VERSION ""

NS_ :

BS_:

BU_: VDCU_M CDCU VDR_TBOX ADCU VIU_B VIU_C VDCU_V EPB EBS FCS EPS_M EPS_S CMS_R CMS_B ECAS EGSM MTCU

BO_ 2566834778 DM1_MTCU: 56 MTCU
 SG_ ProtectLampStatus_MTCU : 0|2@1+ (1,0) [0|3] "" VDCU_M
 SG_ AmberWarningLampStatus_MTCU : 2|2@1+ (1,0) [0|3] "" VDCU_M
 SG_ RedStopLampState_MTCU : 4|2@1+ (1,0) [0|3] "" VDCU_M
 SG_ MalfunctionIndicatorLampStatus_MTCU : 6|2@1+ (1,0) [0|3] "" VDCU_M
 SG_ FlashProtectLamp_MTCU : 8|2@1+ (1,0) [0|3] "" VDCU_M
 SG_ FlashAmberWarningLamp_MTCU : 10|2@1+ (1,0) [0|3] "" VDCU_M
 SG_ FlashRedStopLamp_MTCU : 12|2@1+ (1,0) [0|3] "" VDCU_M
 SG_ FlashMalfuncIndicatorLamp_MTCU : 14|2@1+ (1,0) [0|3] "" VDCU_M
 SG_ DTC1_MTCU : 16|32@1+ (1,0) [0|4294967295] "" VDCU_M
 SG_ DTC2_MTCU : 48|32@1+ (1,0) [0|4294967295] "" VDCU_M
 SG_ DTC3_MTCU : 80|32@1+ (1,0) [0|4294967295] "" VDCU_M
 SG_ DTC4_MTCU : 112|32@1+ (1,0) [0|4294967295] "" VDCU_M
 SG_ DTC5_MTCU : 144|32@1+ (1,0) [0|4294967295] "" VDCU_M

BO_ 2566834692 DM1_MTCU_Axle2: 56 MTCU
 SG_ ProtectLampStatus_MTCU_Axle2 : 0|2@1+ (1,0) [0|3] "" VDCU_M
 SG_ AmberWarningLampStatus_MTCU_Axle2 : 2|2@1+ (1,0) [0|3] "" VDCU_M
 SG_ RedStopLampState_MTCU_Axle2 : 4|2@1+ (1,0) [0|3] "" VDCU_M
 SG_ MalfunctionIndicatorLampStatus_MTCU_Axle2 : 6|2@1+ (1,0) [0|3] "" VDCU_M
 SG_ FlashProtectLamp_MTCU_Axle2 : 8|2@1+ (1,0) [0|3] "" VDCU_M
 SG_ FlashAmberWarningLamp_MTCU_Axle2 : 10|2@1+ (1,0) [0|3] "" VDCU_M
 SG_ FlashRedStopLamp_MTCU_Axle2 : 12|2@1+ (1,0) [0|3] "" VDCU_M
 SG_ FlashMalfuncIndicatorLamp_MTCU_Axle2 : 14|2@1+ (1,0) [0|3] "" VDCU_M
 SG_ DTC1_MTCU_Axle2 : 16|32@1+ (1,0) [0|4294967295] "" VDCU_M
 SG_ DTC2_MTCU_Axle2 : 48|32@1+ (1,0) [0|4294967295] "" VDCU_M
 SG_ DTC3_MTCU_Axle2 : 80|32@1+ (1,0) [0|4294967295] "" VDCU_M
 SG_ DTC4_MTCU_Axle2 : 112|32@1+ (1,0) [0|4294967295] "" VDCU_M
 SG_ DTC5_MTCU_Axle2 : 144|32@1+ (1,0) [0|4294967295] "" VDCU_M

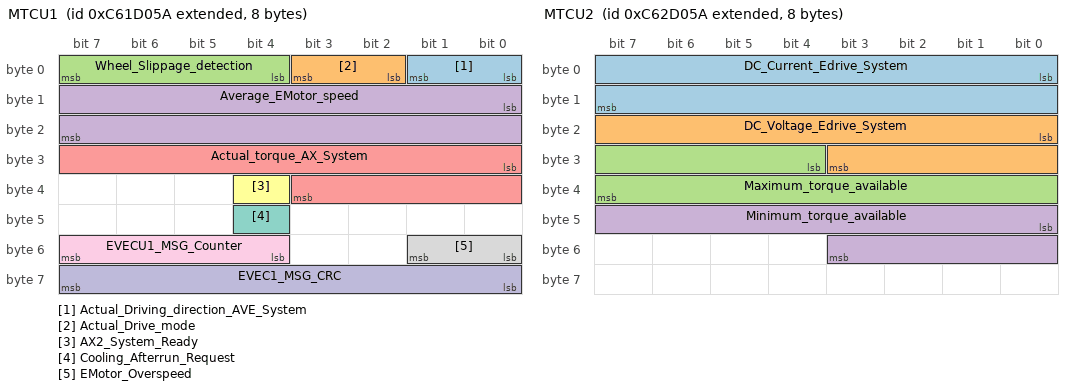
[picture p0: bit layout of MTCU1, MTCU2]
BO_ 2355220570 MTCU1: 8 MTCU
 SG_ Actual_Driving_direction_AVE_System : 0|2@1+ (1,0) [0|2] "" VDCU_M
 SG_ Actual_Drive_mode : 2|2@1+ (1,0) [0|3] "" VDCU_M
 SG_ Wheel_Slippage_detection : 4|4@1+ (1,0) [0|3] "" VDCU_M
 SG_ Average_EMotor_speed : 8|16@1+ (1,0) [0|15000] "rpm" VDCU_M
 SG_ Actual_torque_AX_System : 24|12@1+ (1,0) [0|3200] "Nm" VDCU_M
 SG_ AX2_System_Ready : 36|1@1+ (1,0) [0|1] "" VDCU_M
 SG_ Cooling_Afterrun_Request : 44|1@1+ (1,0) [0|1] "" VDCU_M
 SG_ EMotor_Overspeed : 48|2@1+ (1,0) [0|3] "" VDCU_M
 SG_ EVECU1_MSG_Counter : 52|4@1+ (1,0) [0|15] "" VDCU_M
 SG_ EVEC1_MSG_CRC : 56|8@1+ (1,0) [0|255] "" VDCU_M

BO_ 2355286106 MTCU2: 8 MTCU
 SG_ DC_Current_Edrive_System : 0|16@1+ (0.05,-1638) [-1638|1638] "A" VDCU_M
 SG_ DC_Voltage_Edrive_System : 16|12@1+ (0.25,0) [0|1022] "V" VDCU_M
 SG_ Maximum_torque_available : 28|12@1+ (1,0) [0|3200] "Nm" VDCU_M
 SG_ Minimum_torque_available : 40|12@1+ (1,-3200) [-3200|0] "Nm" VDCU_M

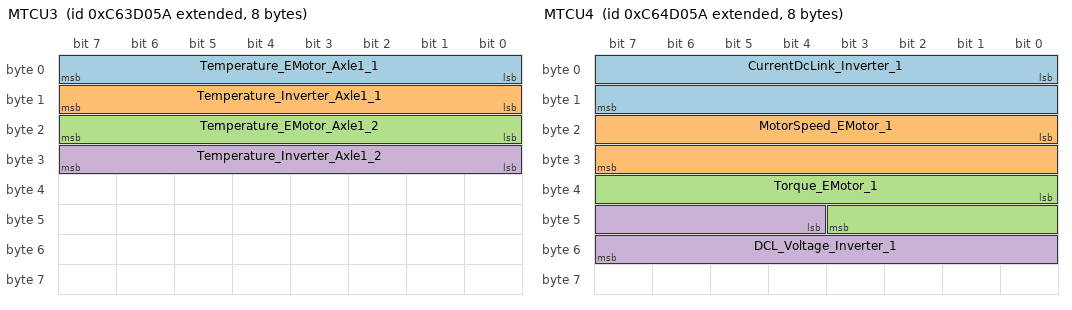
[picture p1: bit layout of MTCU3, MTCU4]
BO_ 2355351642 MTCU3: 8 MTCU
 SG_ Temperature_EMotor_Axle1_1 : 0|8@1+ (1,-40) [-40|213] "°C" VDCU_M
 SG_ Temperature_Inverter_Axle1_1 : 8|8@1+ (1,-40) [-40|213] "°C" VDCU_M
 SG_ Temperature_EMotor_Axle1_2 : 16|8@1+ (1,-40) [-40|213] "°C" VDCU_M
 SG_ Temperature_Inverter_Axle1_2 : 24|8@1+ (1,-40) [-40|213] "°C" VDCU_M

BO_ 2355417178 MTCU4: 8 MTCU
 SG_ CurrentDcLink_Inverter_1 : 0|16@1+ (0.05,-1638) [-1638|1638] "A" VDCU_M
 SG_ MotorSpeed_EMotor_1 : 16|16@1+ (1,-32128) [-32128|32128] "rpm" VDCU_M
 SG_ Torque_EMotor_1 : 32|12@1+ (1,-2048) [-2048|2047] "Nm" VDCU_M
 SG_ DCL_Voltage_Inverter_1 : 44|12@1+ (1,0) [0|2047] "V" VDCU_M

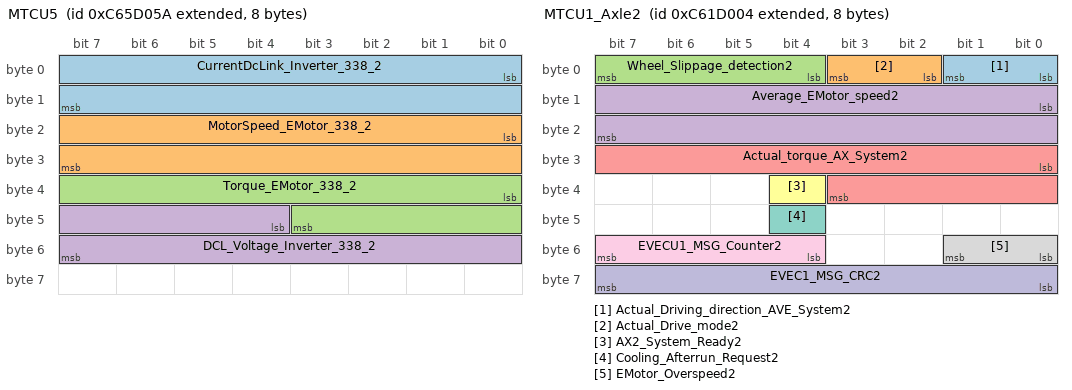
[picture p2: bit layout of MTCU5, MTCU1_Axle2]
BO_ 2355482714 MTCU5: 8 MTCU
 SG_ CurrentDcLink_Inverter_338_2 : 0|16@1+ (0.05,-1638) [-1638|1638] "A" VDCU_M
 SG_ MotorSpeed_EMotor_338_2 : 16|16@1+ (1,-32128) [-32128|32128] "rpm" VDCU_M
 SG_ Torque_EMotor_338_2 : 32|12@1+ (1,-2048) [-2048|2047] "Nm" VDCU_M
 SG_ DCL_Voltage_Inverter_338_2 : 44|12@1+ (1,0) [0|2047] "V" VDCU_M

BO_ 2355548250 MTCU_Inf: 8 MTCU
 SG_ ECU_Cl15_State : 0|2@1+ (1,0) [0|3] "" VDCU_M
 SG_ EV_Driveline_Shutdown_Indication : 2|2@1+ (1,0) [0|3] "" VDCU_M

BO_ 2356007002 Derating: 8 MTCU
 SG_ Derating_Flag : 18|11@1+ (1,0) [0|2047] "" VDCU_M

BO_ 2355220484 MTCU1_Axle2: 8 MTCU
 SG_ Actual_Driving_direction_AVE_System2 : 0|2@1+ (1,0) [0|2] "" VDCU_M
 SG_ Actual_Drive_mode2 : 2|2@1+ (1,0) [0|3] "" VDCU_M
 SG_ Wheel_Slippage_detection2 : 4|4@1+ (1,0) [0|3] "" VDCU_M
 SG_ Average_EMotor_speed2 : 8|16@1+ (1,0) [0|15000] "rpm" VDCU_M
 SG_ Actual_torque_AX_System2 : 24|12@1+ (1,0) [0|3200] "Nm" VDCU_M
 SG_ AX2_System_Ready2 : 36|1@1+ (1,0) [0|1] "" VDCU_M
 SG_ Cooling_Afterrun_Request2 : 44|1@1+ (1,0) [0|1] "" VDCU_M
 SG_ EMotor_Overspeed2 : 48|2@1+ (1,0) [0|3] "" VDCU_M
 SG_ EVECU1_MSG_Counter2 : 52|4@1+ (1,0) [0|15] "" VDCU_M
 SG_ EVEC1_MSG_CRC2 : 56|8@1+ (1,0) [0|255] "" VDCU_M

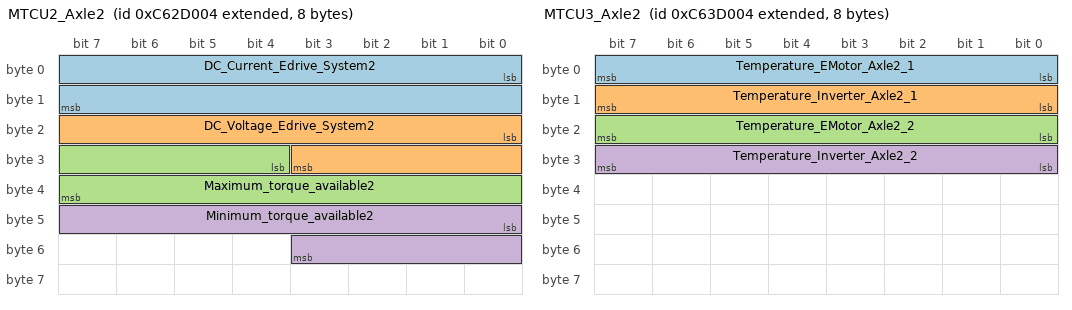
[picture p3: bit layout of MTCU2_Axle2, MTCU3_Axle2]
BO_ 2355286020 MTCU2_Axle2: 8 MTCU
 SG_ DC_Current_Edrive_System2 : 0|16@1+ (0.05,-1638) [-1638|1638] "A" VDCU_M
 SG_ DC_Voltage_Edrive_System2 : 16|12@1+ (0.25,0) [0|1022] "V" VDCU_M
 SG_ Maximum_torque_available2 : 28|12@1+ (1,0) [0|3200] "Nm" VDCU_M
 SG_ Minimum_torque_available2 : 40|12@1+ (1,-3200) [-3200|0] "Nm" VDCU_M

BO_ 2355351556 MTCU3_Axle2: 8 MTCU
 SG_ Temperature_EMotor_Axle2_1 : 0|8@1+ (1,-40) [-40|213] "°C" VDCU_M
 SG_ Temperature_Inverter_Axle2_1 : 8|8@1+ (1,-40) [-40|213] "°C" VDCU_M
 SG_ Temperature_EMotor_Axle2_2 : 16|8@1+ (1,-40) [-40|213] "°C" VDCU_M
 SG_ Temperature_Inverter_Axle2_2 : 24|8@1+ (1,-40) [-40|213] "°C" VDCU_M

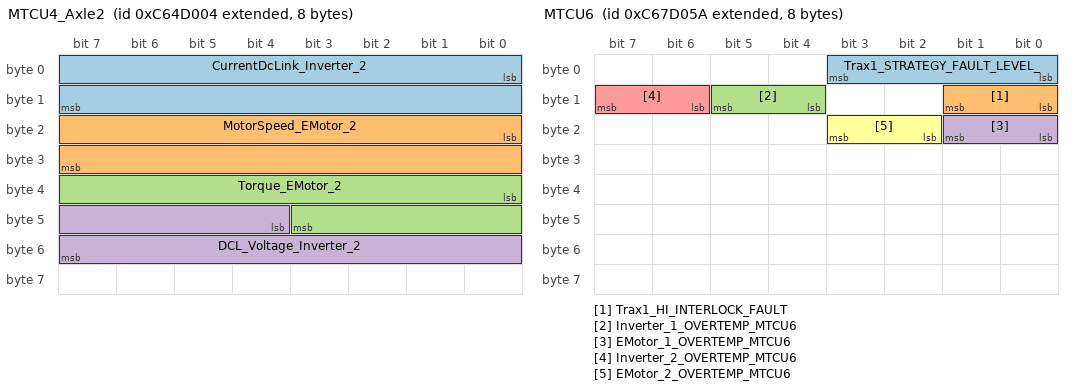
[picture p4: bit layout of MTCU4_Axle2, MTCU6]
BO_ 2355417092 MTCU4_Axle2: 8 MTCU
 SG_ CurrentDcLink_Inverter_2 : 0|16@1+ (0.05,-1638) [-1638|1638] "A" VDCU_M
 SG_ MotorSpeed_EMotor_2 : 16|16@1+ (1,-32128) [-32128|32128] "rpm" VDCU_M
 SG_ Torque_EMotor_2 : 32|12@1+ (1,-2048) [-2048|2047] "Nm" VDCU_M
 SG_ DCL_Voltage_Inverter_2 : 44|12@1+ (1,0) [0|2047] "V" VDCU_M

BO_ 2355548164 MTCU_Inf_Axle2: 8 MTCU
 SG_ ECU_Cl15_State2 : 0|2@1+ (1,0) [0|3] "" VDCU_M
 SG_ EV_Driveline_Shutdown_Indication2 : 2|2@1+ (1,0) [0|3] "" VDCU_M

BO_ 2356006916 Derating_Axle2: 8 MTCU
 SG_ Derating_Flag_Axle2 : 18|11@1+ (1,0) [0|2047] "" VDCU_M

BO_ 2355613786 MTCU6: 8 MTCU
 SG_ Trax1_STRATEGY_FAULT_LEVEL_ : 0|4@1+ (1,0) [0|15] "" VDCU_M
 SG_ Trax1_HI_INTERLOCK_FAULT : 8|2@1+ (1,0) [0|3] "" VDCU_M
 SG_ Inverter_1_OVERTEMP_MTCU6 : 12|2@1+ (1,0) [0|3] "" VDCU_M
 SG_ EMotor_1_OVERTEMP_MTCU6 : 16|2@1+ (1,0) [0|3] "" VDCU_M
 SG_ Inverter_2_OVERTEMP_MTCU6 : 14|2@1+ (1,0) [0|3] "" VDCU_M
 SG_ EMotor_2_OVERTEMP_MTCU6 : 18|2@1+ (1,0) [0|3] "" VDCU_M

BO_ 2557005914 MTCU7: 8 MTCU
 SG_ MCU1_NRF_PHASE_HW_OVERCUR : 0|1@1+ (1,0) [0|1] "" VDCU_M
 SG_ MCU1_RF_UNBANLANCEDCUR : 1|1@1+ (1,0) [0|1] "" VDCU_M
 SG_ MCU1_NRF_CUR_SENSORZERO_FAULT_U : 2|1@1+ (1,0) [0|1] "" VDCU_M
 SG_ MCU1_NRF_CUR_SENSORZERO_FAULT_V : 3|1@1+ (1,0) [0|1] "" VDCU_M
 SG_ MCU1_NRF_CUR_SENSORZERO_FAULT_W : 4|1@1+ (1,0) [0|1] "" VDCU_M
 SG_ MCU1_NRF_PHASE_OVERCUR_U : 5|1@1+ (1,0) [0|1] "" VDCU_M
 SG_ MCU1_NRF_PHASE_OVERCUR_V : 6|1@1+ (1,0) [0|1] "" VDCU_M
 SG_ MCU1_NRF_PHASE_OVERCUR_W : 7|1@1+ (1,0) [0|1] "" VDCU_M
 SG_ MCU1_RF_PHASE_OVERCUR_U : 8|1@1+ (1,0) [0|1] "" VDCU_M
 SG_ MCU1_RF_PHASE_OVERCUR_V : 9|1@1+ (1,0) [0|1] "" VDCU_M
 SG_ MCU1_RF_PHASE_OVERCUR_W : 10|1@1+ (1,0) [0|1] "" VDCU_M
 SG_ MCU1_NRF_DC_SENSORZERO_FAULT : 11|1@1+ (1,0) [0|1] "" VDCU_M
 SG_ MCU1_NRF_DC_OVERCUR : 12|1@1+ (1,0) [0|1] "" VDCU_M
 SG_ MCU1_NRF_DCFEED_INTERRUPT : 13|1@1+ (1,0) [0|1] "" VDCU_M
 SG_ MCU1_NRF_DC_HW_OVERVOL : 14|1@1+ (1,0) [0|1] "" VDCU_M
 SG_ MCU1_NRF_DC_SW_OVERVOL : 15|1@1+ (1,0) [0|1] "" VDCU_M
 SG_ MCU1_RF_DC_OVERVOL : 16|1@1+ (1,0) [0|1] "" VDCU_M
 SG_ MCU1_LIF_DC_OVERVOL : 17|1@1+ (1,0) [0|1] "" VDCU_M
 SG_ MCU1_NRF_DC_UNDERVOL : 18|1@1+ (1,0) [0|1] "" VDCU_M
 SG_ MCU1_RF_DC_UNDERVOL : 19|1@1+ (1,0) [0|1] "" VDCU_M
 SG_ MCU1_LIF_DC_UNDERVO : 20|1@1+ (1,0) [0|1] "" VDCU_M
 SG_ MCU1_IGBT_TEMPSENSOR_FAULT : 21|1@1+ (1,0) [0|1] "" VDCU_M
 SG_ MCU1_RF_INVTEMP_OVERTEMP : 23|1@1+ (1,0) [0|1] "" VDCU_M
 SG_ MCU1_TORQUE_LOSTCONTROL : 24|1@1+ (1,0) [0|1] "" VDCU_M
 SG_ MCU1_MOTOR_TEMSENSOR_FAULT : 25|1@1+ (1,0) [0|1] "" VDCU_M
 SG_ MCU1_RF_MOTOR_OVERTEMP : 27|1@1+ (1,0) [0|1] "" VDCU_M
 SG_ MCU1_NRF_RDC_FAULT : 28|1@1+ (1,0) [0|1] "" VDCU_M
 SG_ MCU1_NRF_F_OVERSPEED : 29|1@1+ (1,0) [0|1] "" VDCU_M
 SG_ MCU1_RF_F_OVERSPEED : 30|1@1+ (1,0) [0|1] "" VDCU_M
 SG_ MCU1_LIF_R_OVERSPEED : 31|1@1+ (1,0) [0|1] "" VDCU_M
 SG_ MCU1_NRF_IGBT_HWTEST_FAULT : 32|1@1+ (1,0) [0|1] "" VDCU_M
 SG_ MCU1_NRF_IGBT_HWLV_VOL_FAULT : 33|1@1+ (1,0) [0|1] "" VDCU_M
 SG_ MCU1_NRF_5V_SUPPLY_FAULT : 34|1@1+ (1,0) [0|1] "" VDCU_M
 SG_ MCU1_LIF_MOTOR_OVERTEMP : 35|1@1+ (1,0) [0|1] "" VDCU_M
 SG_ MCU1_NRF_LV_VOL_SUPPLY : 36|1@1+ (1,0) [0|1] "" VDCU_M
 SG_ MCU1_LIF_INVTEMP_OVERTEMP : 37|1@1+ (1,0) [0|1] "" VDCU_M
 SG_ MCU1_NRF_CAN_BUSOFF : 38|1@1+ (1,0) [0|1] "" VDCU_M
 SG_ MCU1_RF_CAN_BUSOFF : 39|1@1+ (1,0) [0|1] "" VDCU_M
 SG_ MCU1_RF_CAN_INTERNAL_FAULT : 40|1@1+ (1,0) [0|1] "" VDCU_M
 SG_ MCU1_VCU_COM_LOST_ : 41|1@1+ (1,0) [0|1] "" VDCU_M
 SG_ MCU1_EEPRROM_FAULT_ : 42|1@1+ (1,0) [0|1] "" VDCU_M
 SG_ MCU1_LOCKED_ROTOR_FAULT : 43|1@1+ (1,0) [0|1] "" VDCU_M
 SG_ MCU1_DISCHARGE_FAULT : 44|1@1+ (1,0) [0|1] "" VDCU_M
 SG_ MCU1_SOFTWARE_INTERRUPT : 45|1@1+ (1,0) [0|1] "" VDCU_M
 SG_ MCU1_POST_FAULT : 46|1@1+ (1,0) [0|1] "" VDCU_M
 SG_ MCU1_MOTOR_SELFLEARNING_FAULT : 47|1@1+ (1,0) [0|1] "" VDCU_M
 SG_ MCU1_DATA_OVERFLOW_FAULT : 48|1@1+ (1,0) [0|1] "" VDCU_M
 SG_ MCU1_MCU_OVERLOAD_FAULT : 49|1@1+ (1,0) [0|1] "" VDCU_M
 SG_ MCU1_MOTOR_OVERLOAD_FAULT : 50|1@1+ (1,0) [0|1] "" VDCU_M
 SG_ MCU1_LIF_F_OVERSPEED : 51|1@1+ (1,0) [0|1] "" VDCU_M
 SG_ MCU1_TjIGBT_OVER_TEMP : 53|1@1+ (1,0) [0|1] "" VDCU_M
 SG_ MCU1_FS_Mw_faultiac_L3 : 54|1@1+ (1,0) [0|1] "" VDCU_M
 SG_ MCU1_FS_Mw_faultUdc_L3 : 55|1@1+ (1,0) [0|1] "" VDCU_M
 SG_ MCU1_FS_Mw_faultspeedcal_L3 : 56|1@1+ (1,0) [0|1] "" VDCU_M
 SG_ MCU1_FS_Mw_faulttorcomp_L3 : 57|1@1+ (1,0) [0|1] "" VDCU_M
 SG_ MCU1_FS_Mw_faultpwmpowerup_L3 : 58|1@1+ (1,0) [0|1] "" VDCU_M
 SG_ MCU1_FS_Mw_faultpwmpowerdown_L3 : 59|1@1+ (1,0) [0|1] "" VDCU_M
 SG_ MCU1_FS_Mw_faultpwm_L3 : 60|1@1+ (1,0) [0|1] "" VDCU_M
 SG_ MCU1_FS_Mw_faultacdischarge_L3 : 61|1@1+ (1,0) [0|1] "" VDCU_M
 SG_ MCU1_FS_Mw_faultpowermanager_L3 : 62|1@1+ (1,0) [0|1] "" VDCU_M

BO_ 2557071450 MTCU8: 8 MTCU
 SG_ MCU1_516_CURSENSOR_SHORT_FAULT__A : 0|1@1+ (1,0) [0|1] "" VDCU_M
 SG_ MCU1_516_CURSENSOR_SHORT_FAULT__B : 1|1@1+ (1,0) [0|1] "" VDCU_M
 SG_ MCU1_516_CURSENSOR_SHORT_FAULT__C : 2|1@1+ (1,0) [0|1] "" VDCU_M
 SG_ MCU1_516_CURSENSOR_OPEN_FAULT__A : 3|1@1+ (1,0) [0|1] "" VDCU_M
 SG_ MCU1_516_CURSENSOR_OPEN_FAULT__B : 4|1@1+ (1,0) [0|1] "" VDCU_M
 SG_ MCU1_516_CURSENSOR_OPEN_FAULT__C : 5|1@1+ (1,0) [0|1] "" VDCU_M
 SG_ MCU1_516_NRF_ANGLE_FAULT : 6|1@1+ (1,0) [0|1] "" VDCU_M
 SG_ MCU1_516_RF_POWER_FAULT : 7|1@1+ (1,0) [0|1] "" VDCU_M
 SG_ MCU1_516_NRF_PHASE_LOST_FAULT : 8|1@1+ (1,0) [0|1] "" VDCU_M
 SG_ MCU1_516_NRF_HEATSINK_FAULT : 9|1@1+ (1,0) [0|1] "" VDCU_M
 SG_ MCU1_516_RF_HEATSINK_FAULT : 10|1@1+ (1,0) [0|1] "" VDCU_M
 SG_ MCU1_516_LIF_HEATSINK_FAULT : 11|1@1+ (1,0) [0|1] "" VDCU_M
 SG_ MCU1_NRF_IGBT_B_HWTEST_FAULT : 12|1@1+ (1,0) [0|1] "" VDCU_M
 SG_ MCU1_NRF_IGBT_C_HWTEST_FAULT : 13|1@1+ (1,0) [0|1] "" VDCU_M
 SG_ MCU1_NRF_PHASE_B_HW_OVERCUR : 14|1@1+ (1,0) [0|1] "" VDCU_M
 SG_ MCU1_NRF_PHASE_C_HW_OVERCUR : 15|1@1+ (1,0) [0|1] "" VDCU_M
 SG_ MCU1_NRF_PHASE_OVERCUR : 16|1@1+ (1,0) [0|1] "" VDCU_M
 SG_ MCU1_RF_PHASE_OVERCUR : 17|1@1+ (1,0) [0|1] "" VDCU_M
 SG_ MCU1_LIF_PHASE_OVERCUR : 18|1@1+ (1,0) [0|1] "" VDCU_M
 SG_ MCU1_LIF_PHASE_OVERCUR_U : 19|1@1+ (1,0) [0|1] "" VDCU_M
 SG_ MCU1_LIF_PHASE_OVERCUR_V : 20|1@1+ (1,0) [0|1] "" VDCU_M
 SG_ MCU1_LIF_PHASE_OVERCUR_W : 21|1@1+ (1,0) [0|1] "" VDCU_M
 SG_ MCU1_MCU_OVERLOAD_FAULT_A : 22|1@1+ (1,0) [0|1] "" VDCU_M
 SG_ MCU1_MCU_OVERLOAD_FAULT_B : 23|1@1+ (1,0) [0|1] "" VDCU_M
 SG_ MCU1_MCU_OVERLOAD_FAULT_C : 24|1@1+ (1,0) [0|1] "" VDCU_M
 SG_ MCU1_IGBT_TEMPSENSOR_SHORT_FAULT_B : 25|1@1+ (1,0) [0|1] "" VDCU_M
 SG_ MCU1_IGBT_TEMPSENSOR_SHORT_FAULT_C : 26|1@1+ (1,0) [0|1] "" VDCU_M
 SG_ MCU1_IGBT_TEMPSENSOR_OPEN_FAULT_A : 27|1@1+ (1,0) [0|1] "" VDCU_M
 SG_ MCU1_IGBT_TEMPSENSOR_OPEN_FAULT_B : 28|1@1+ (1,0) [0|1] "" VDCU_M
 SG_ MCU1_IGBT_TEMPSENSOR_OPEN_FAULT_C : 29|1@1+ (1,0) [0|1] "" VDCU_M
 SG_ MCU1_NRF_INVTEMP_OVERTEMP_A : 30|1@1+ (1,0) [0|1] "" VDCU_M
 SG_ MCU1_NRF_INVTEMP_OVERTEMP_B : 31|1@1+ (1,0) [0|1] "" VDCU_M
 SG_ MCU1_NRF_INVTEMP_OVERTEMP_C : 32|1@1+ (1,0) [0|1] "" VDCU_M
 SG_ MCU1_RF_INVTEMP_OVERTEMP_A : 33|1@1+ (1,0) [0|1] "" VDCU_M
 SG_ MCU1_RF_INVTEMP_OVERTEMP_B : 34|1@1+ (1,0) [0|1] "" VDCU_M
 SG_ MCU1_RF_INVTEMP_OVERTEMP_C : 35|1@1+ (1,0) [0|1] "" VDCU_M
 SG_ MCU1_LIF_INVTEMP_OVERTEMP_A : 36|1@1+ (1,0) [0|1] "" VDCU_M
 SG_ MCU1_LIF_INVTEMP_OVERTEMP_B : 37|1@1+ (1,0) [0|1] "" VDCU_M
 SG_ MCU1_LIF_INVTEMP_OVERTEMP_C : 38|1@1+ (1,0) [0|1] "" VDCU_M
 SG_ MCU1_MOTOR_TEMSENSOR_1_SHORT_FAULT : 39|1@1+ (1,0) [0|1] "" VDCU_M
 SG_ MCU1_MOTOR_TEMSENSOR_1_OPEN_FAULT : 40|1@1+ (1,0) [0|1] "" VDCU_M
 SG_ MCU1_MOTOR_TEMSENSOR_2_OPEN_FAULT : 41|1@1+ (1,0) [0|1] "" VDCU_M
 SG_ MCU1_RF_R_OVERSPEED : 42|1@1+ (1,0) [0|1] "" VDCU_M
 SG_ MCU1_NRF_LV_OVERVOL_SUPPLY : 43|1@1+ (1,0) [0|1] "" VDCU_M
 SG_ MCU1_NRF_LV_BKP_OVERVOL_SUPPLY : 44|1@1+ (1,0) [0|1] "" VDCU_M
 SG_ MCU1_NRF_LV_BKP_UNDERVOL_SUPPLY : 45|1@1+ (1,0) [0|1] "" VDCU_M
 SG_ MCU1_NRF_DC_HW_OVERVOL_2 : 46|1@1+ (1,0) [0|1] "" VDCU_M
 SG_ MCU1_NRF_DC_HW_OVERVOL_1 : 47|1@1+ (1,0) [0|1] "" VDCU_M
 SG_ MCU1_NRF_DC_HW_HVIL : 48|1@1+ (1,0) [0|1] "" VDCU_M
 SG_ MCU1_NRF_5V_DCCUR_SUPPLY_OVERVOL_FAULT : 49|1@1+ (1,0) [0|1] "" VDCU_M
 SG_ MCU1_NRF_5V_DCCUR_SUPPLY_UNDERVOL_FAULT : 50|1@1+ (1,0) [0|1] "" VDCU_M
 SG_ MCU1_NRF_5V_CUR_SUPPLY_OVERVOL_FAULT : 51|1@1+ (1,0) [0|1] "" VDCU_M
 SG_ MCU1_NRF_5V_CUR_SUPPLY_UNDERVOL_FAULT : 52|1@1+ (1,0) [0|1] "" VDCU_M
 SG_ MCU1_NRF_5V_DRV_SUPPLY_OVERVOL_FAULT : 53|1@1+ (1,0) [0|1] "" VDCU_M
 SG_ MCU1_NRF_PCBTEMP_OVERTEMP : 54|1@1+ (1,0) [0|1] "" VDCU_M
 SG_ MCU1_ACCLR_FAULT : 55|1@1+ (1,0) [0|1] "" VDCU_M

BO_ 2557136986 MTCU9: 8 MTCU
 SG_ TCU_Power_Over_1st : 0|1@1+ (1,0) [0|1] "" VDCU_M
 SG_ TCU_Power_Down_1st : 1|1@1+ (1,0) [0|1] "" VDCU_M
 SG_ TCU_CPUNvm_Fault_1st : 2|1@1+ (1,0) [0|1] "" VDCU_M
 SG_ TCU_CPURam_Fault_1st : 3|1@1+ (1,0) [0|1] "" VDCU_M
 SG_ TCU_CPURom_Fault_1st : 4|1@1+ (1,0) [0|1] "" VDCU_M
 SG_ TCU_Reset_Fault_1st : 5|1@1+ (1,0) [0|1] "" VDCU_M
 SG_ TCU_System_Fault_1st : 6|1@1+ (1,0) [0|1] "" VDCU_M
 SG_ TCU_HSD2AndPowerShort_1st : 7|1@1+ (1,0) [0|1] "" VDCU_M
 SG_ TCU_HighPinShort_1st : 8|1@1+ (1,0) [0|1] "" VDCU_M
 SG_ TCU_CAN1Disconnect_1st : 9|1@1+ (1,0) [0|1] "" VDCU_M
 SG_ TCU_CAN2Disconnect_1st : 10|1@1+ (1,0) [0|1] "" VDCU_M
 SG_ TCU_HSD1AndPowerShort_1st : 11|1@1+ (1,0) [0|1] "" VDCU_M
 SG_ TCU_AccPdlLoss_1st : 12|1@1+ (1,0) [0|1] "" VDCU_M
 SG_ TCU_AccPdlMessgLengthErr_1st : 13|1@1+ (1,0) [0|1] "" VDCU_M
 SG_ TCU_AccPdlCheckSumCheckErr_1st : 14|1@1+ (1,0) [0|1] "" VDCU_M
 SG_ TCU_AccPdlRollingCounterErr_1st : 15|1@1+ (1,0) [0|1] "" VDCU_M
 SG_ TCU_AccPdlInvalidEnab_1st : 16|1@1+ (1,0) [0|1] "" VDCU_M
 SG_ TCU_AccPdlEqualInvalidVal_1st : 17|1@1+ (1,0) [0|1] "" VDCU_M
 SG_ TCU_TemSnsrOpen_1st : 18|1@1+ (1,0) [0|1] "" VDCU_M
 SG_ TCU_TemSnsrShorttoPower_1st : 19|1@1+ (1,0) [0|1] "" VDCU_M
 SG_ TCU_TemSnsrShorttoGround_1st : 20|1@1+ (1,0) [0|1] "" VDCU_M
 SG_ TCU_OutSftSpdSnsrOpen_1st : 21|1@1+ (1,0) [0|1] "" VDCU_M
 SG_ TCU_OutSftSpdShorttoPower_1st : 22|1@1+ (1,0) [0|1] "" VDCU_M
 SG_ TCU_OutSftSpdShorttoGround_1st : 23|1@1+ (1,0) [0|1] "" VDCU_M
 SG_ TCU_SlctGValStPCSG2_Open_1st : 24|1@1+ (1,0) [0|1] "" VDCU_M
 SG_ TCU_SlctGValStPCSG2_ShorttoPower_1st : 25|1@1+ (1,0) [0|1] "" VDCU_M
 SG_ TCU_SlctGValStPCSG2_ShorttoGround_1st : 26|1@1+ (1,0) [0|1] "" VDCU_M
 SG_ TCU_SlctGValStPCSG2_OverLoad_1st : 27|1@1+ (1,0) [0|1] "" VDCU_M
 SG_ TCU_SlctGValStPCSG2_UnderLoad_1st : 28|1@1+ (1,0) [0|1] "" VDCU_M
 SG_ TCU_SlctGValStPCSG4_Open_1st : 29|1@1+ (1,0) [0|1] "" VDCU_M
 SG_ TCU_SlctGValStPCSG4_ShorttoPower_1st : 30|1@1+ (1,0) [0|1] "" VDCU_M
 SG_ TCU_SlctGValStPCSG4_ShorttoGround_1st : 31|1@1+ (1,0) [0|1] "" VDCU_M
 SG_ TCU_SlctGValStPCSG4_OverLoad_1st : 32|1@1+ (1,0) [0|1] "" VDCU_M
 SG_ TCU_SlctGValStPCSG4_UnderLoad_1st : 33|1@1+ (1,0) [0|1] "" VDCU_M
 SG_ TCU_SlctGValStPCSS3_Open_1st : 34|1@1+ (1,0) [0|1] "" VDCU_M
 SG_ TCU_SlctGValStPCSS3_ShorttoPower_1st : 35|1@1+ (1,0) [0|1] "" VDCU_M
 SG_ TCU_SlctGValStPCSS3_ShorttoGround_1st : 36|1@1+ (1,0) [0|1] "" VDCU_M
 SG_ TCU_SlctGValStPCSS3_OverLoad_1st : 37|1@1+ (1,0) [0|1] "" VDCU_M
 SG_ TCU_SlctGValStPCSS3_UnderLoad_1st : 38|1@1+ (1,0) [0|1] "" VDCU_M
 SG_ TCU_SlctGValStPCSS4_Open_1st : 39|1@1+ (1,0) [0|1] "" VDCU_M
 SG_ TCU_SlctGValStPCSS4_ShorttoPower_1st : 40|1@1+ (1,0) [0|1] "" VDCU_M
 SG_ TCU_SlctGValStPCSS4_ShorttoGround_1st : 41|1@1+ (1,0) [0|1] "" VDCU_M
 SG_ TCU_SlctGValStPCSS4_OverLoad_1st : 42|1@1+ (1,0) [0|1] "" VDCU_M
 SG_ TCU_SlctGValStPCSS4_UnderLoad_1st : 43|1@1+ (1,0) [0|1] "" VDCU_M
 SG_ TCU_9VElectricity_OverHigh_1st : 44|1@1+ (1,0) [0|1] "" VDCU_M
 SG_ TCU_9VElectricity_OverLow_1st : 45|1@1+ (1,0) [0|1] "" VDCU_M
 SG_ TCU_9VElectricityAndPow_Short_1st : 46|1@1+ (1,0) [0|1] "" VDCU_M
 SG_ TCU_9VElectricityAndGnd_Short_1st : 47|1@1+ (1,0) [0|1] "" VDCU_M
 SG_ TCU_HSD1_Broken_1st : 48|1@1+ (1,0) [0|1] "" VDCU_M
 SG_ TCU_HSD1AndGnd_Broken_1st : 49|1@1+ (1,0) [0|1] "" VDCU_M
 SG_ TCU_HSD2_Broken_1st : 50|1@1+ (1,0) [0|1] "" VDCU_M
 SG_ TCU_HSD2AndGnd_Broken_1st : 51|1@1+ (1,0) [0|1] "" VDCU_M
 SG_ TCU_CAN1Node_Fault_1st : 52|1@1+ (1,0) [0|1] "" VDCU_M
 SG_ TCU_CANBus_Silence_1st : 53|1@1+ (1,0) [0|1] "" VDCU_M
 SG_ TCU_CAN2Node_Fault_1st : 54|1@1+ (1,0) [0|1] "" VDCU_M
 SG_ TCU_PosSensorD_Broken_1st : 55|1@1+ (1,0) [0|1] "" VDCU_M
 SG_ TCU_PosSensorDAndPow_Broken_1st : 56|1@1+ (1,0) [0|1] "" VDCU_M
 SG_ TCU_PosSensorDAndGnd_Broken_1st : 57|1@1+ (1,0) [0|1] "" VDCU_M
 SG_ TCU_PosSensorE_Broken_1st : 58|1@1+ (1,0) [0|1] "" VDCU_M
 SG_ TCU_PosSensorEAndPow_Broken_1st : 59|1@1+ (1,0) [0|1] "" VDCU_M
 SG_ TCU_PosSensorEAndGnd_Broken_1st : 60|1@1+ (1,0) [0|1] "" VDCU_M
 SG_ TCU_PrssSenso_Broken_1st : 61|1@1+ (1,0) [0|1] "" VDCU_M
 SG_ TCU_PrssSensoAndPow_Broken_1st : 62|1@1+ (1,0) [0|1] "" VDCU_M
 SG_ TCU_PrssSensoAndGnd_Broken_1st : 63|1@1+ (1,0) [0|1] "" VDCU_M

BO_ 2557202522 MTCU10: 8 MTCU
 SG_ TCU_5VElectricity_OverHigh_1st : 0|1@1+ (1,0) [0|1] "" VDCU_M
 SG_ TCU_5VElectricity_OverLow_1st : 1|1@1+ (1,0) [0|1] "" VDCU_M
 SG_ TCU_5VElectricityAndPow_Short_1st : 2|1@1+ (1,0) [0|1] "" VDCU_M
 SG_ TCU_5VElectricityAndGnd_Short_1st : 3|1@1+ (1,0) [0|1] "" VDCU_M
 SG_ TCU_VehSpd_Lost_1st : 4|1@1+ (1,0) [0|1] "" VDCU_M
 SG_ TCU_VehSpdMessLength_Fault_1st : 5|1@1+ (1,0) [0|1] "" VDCU_M
 SG_ TCU_VehSpdChecSum_Fault_1st : 6|1@1+ (1,0) [0|1] "" VDCU_M
 SG_ TCU_VehSpd_InvalidFg_1st : 7|1@1+ (1,0) [0|1] "" VDCU_M
 SG_ TCU_VehSpd_Invalid_1st : 8|1@1+ (1,0) [0|1] "" VDCU_M
 SG_ TCU_OilTemp_level3_1st : 9|1@1+ (1,0) [0|1] "" VDCU_M
 SG_ TCU_OilTemp_level4_1st : 10|1@1+ (1,0) [0|1] "" VDCU_M
 SG_ TCU_ATFOilTemp_Low_1st : 11|1@1+ (1,0) [0|1] "" VDCU_M
 SG_ TCU_ATFOilTemp_Hop_1st : 12|1@1+ (1,0) [0|1] "" VDCU_M
 SG_ TCU_OptSftSpd_High_1st : 13|1@1+ (1,0) [0|1] "" VDCU_M
 SG_ TCU_OptSftSpd_Hop_1st : 14|1@1+ (1,0) [0|1] "" VDCU_M
 SG_ TCU_OptSftSpd_Zero_1st : 15|1@1+ (1,0) [0|1] "" VDCU_M
 SG_ TCU_SftOG_Stuk_1st : 16|1@1+ (1,0) [0|1] "" VDCU_M
 SG_ TCU_TqResponse_Failure_1st : 17|1@1+ (1,0) [0|1] "" VDCU_M
 SG_ TCU_SftIG_Stuk_1st : 18|1@1+ (1,0) [0|1] "" VDCU_M
 SG_ TCU_RollingCounter_Fault_1st : 19|1@1+ (1,0) [0|1] "" VDCU_M
 SG_ TCU_PowOn_Failure_1st : 20|1@1+ (1,0) [0|1] "" VDCU_M
 SG_ TCU_PowOff_Failure_1st : 21|1@1+ (1,0) [0|1] "" VDCU_M
 SG_ TCU_OilTemp_level1_1st : 22|1@1+ (1,0) [0|1] "" VDCU_M
 SG_ TCU_OilTemp_level2_1st : 23|1@1+ (1,0) [0|1] "" VDCU_M

BO_ 2566899802 CR1: 8 MTCU
 SG_ Coolant_Request : 0|16@1+ (0.03125,-273) [-273|1734.94] "°C" VDCU_M
 SG_ Coolant_flow_request : 16|16@1+ (0.1,0) [0|6425.5] "l/min" VDCU_M

BO_ 2566840666 RC1: 19 MTCU
 SG_ Retarder_Type : 0|4@1+ (1,0) [0|15] "" VDCU_M
 SG_ Retarder_Location : 4|4@1+ (1,0) [0|15] "" VDCU_M
 SG_ Retarder_Speed_at_Idle_point1 : 16|16@1+ (0.125,0) [0|8031.875] "rpm" VDCU_M
 SG_ RC_Percent_Torque_at_Idle_point1 : 32|8@1+ (1,-125) [-125|125] "%" VDCU_M
 SG_ Maximum_Retarder_Speed_point2 : 40|16@1+ (0.125,0) [0|8031.875] "rpm" VDCU_M
 SG_ RC_Percent_Torque_at_maximum_Speed_point2 : 56|8@1+ (1,-125) [-125|125] "%" VDCU_M
 SG_ Retarder_Speed_at_point3 : 64|16@1+ (0.125,0) [0|8031.875] "rpm" VDCU_M
 SG_ RC_Percent_Torque_at_point3 : 80|8@1+ (1,-125) [-125|125] "%" VDCU_M
 SG_ Retarder_Speed_at_point4 : 88|16@1+ (0.125,0) [0|8031.875] "rpm" VDCU_M
 SG_ RC_Percent_Torque_at_point4 : 104|8@1+ (1,-125) [-125|125] "%" VDCU_M
 SG_ Retarder_Speed_at_peak_Torque_point5 : 112|16@1+ (1,0) [0|64255] "Nm" VDCU_M
 SG_ Reference_Retarder_Torque : 128|16@1+ (1,0) [0|64255] "Nm" VDCU_M
 SG_ RC_Percent_Torque_at_point5 : 144|8@1+ (1,-125) [-125|125] "%" VDCU_M

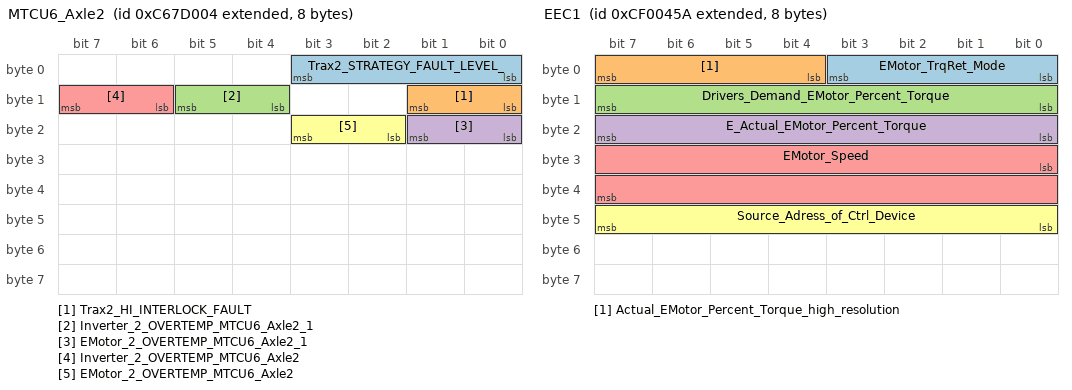
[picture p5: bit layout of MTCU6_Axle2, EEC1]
BO_ 2355613700 MTCU6_Axle2: 8 MTCU
 SG_ Trax2_STRATEGY_FAULT_LEVEL_ : 0|4@1+ (1,0) [0|15] "" VDCU_M
 SG_ Trax2_HI_INTERLOCK_FAULT : 8|2@1+ (1,0) [0|3] "" VDCU_M
 SG_ Inverter_2_OVERTEMP_MTCU6_Axle2_1 : 12|2@1+ (1,0) [0|3] "" VDCU_M
 SG_ EMotor_2_OVERTEMP_MTCU6_Axle2_1 : 16|2@1+ (1,0) [0|3] "" VDCU_M
 SG_ Inverter_2_OVERTEMP_MTCU6_Axle2 : 14|2@1+ (1,0) [0|3] "" VDCU_M
 SG_ EMotor_2_OVERTEMP_MTCU6_Axle2 : 18|2@1+ (1,0) [0|3] "" VDCU_M

BO_ 2557005828 MTCU7_Axle2: 8 MTCU
 SG_ MCU2_NRF_PHASE_HW_OVERCUR : 0|1@1+ (1,0) [0|1] "" VDCU_M
 SG_ MCU2_RF_UNBANLANCEDCUR : 1|1@1+ (1,0) [0|1] "" VDCU_M
 SG_ MCU2_NRF_CUR_SENSORZERO_FAULT_U : 2|1@1+ (1,0) [0|1] "" VDCU_M
 SG_ MCU2_NRF_CUR_SENSORZERO_FAULT_V : 3|1@1+ (1,0) [0|1] "" VDCU_M
 SG_ MCU2_NRF_CUR_SENSORZERO_FAULT_W : 4|1@1+ (1,0) [0|1] "" VDCU_M
 SG_ MCU2_NRF_PHASE_OVERCUR_U : 5|1@1+ (1,0) [0|1] "" VDCU_M
 SG_ MCU2_NRF_PHASE_OVERCUR_V : 6|1@1+ (1,0) [0|1] "" VDCU_M
 SG_ MCU2_NRF_PHASE_OVERCUR_W : 7|1@1+ (1,0) [0|1] "" VDCU_M
 SG_ MCU2_RF_PHASE_OVERCUR_U : 8|1@1+ (1,0) [0|1] "" VDCU_M
 SG_ MCU2_RF_PHASE_OVERCUR_V : 9|1@1+ (1,0) [0|1] "" VDCU_M
 SG_ MCU2_RF_PHASE_OVERCUR_W : 10|1@1+ (1,0) [0|1] "" VDCU_M
 SG_ MCU2_NRF_DC_SENSORZERO_FAULT : 11|1@1+ (1,0) [0|1] "" VDCU_M
 SG_ MCU2_NRF_DC_OVERCUR : 12|1@1+ (1,0) [0|1] "" VDCU_M
 SG_ MCU2_NRF_DCFEED_INTERRUPT : 13|1@1+ (1,0) [0|1] "" VDCU_M
 SG_ MCU2_NRF_DC_HW_OVERVOL : 14|1@1+ (1,0) [0|1] "" VDCU_M
 SG_ MCU2_NRF_DC_SW_OVERVOL : 15|1@1+ (1,0) [0|1] "" VDCU_M
 SG_ MCU2_RF_DC_OVERVOL : 16|1@1+ (1,0) [0|1] "" VDCU_M
 SG_ MCU2_LIF_DC_OVERVOL : 17|1@1+ (1,0) [0|1] "" VDCU_M
 SG_ MCU2_NRF_DC_UNDERVOL : 18|1@1+ (1,0) [0|1] "" VDCU_M
 SG_ MCU2_RF_DC_UNDERVOL : 19|1@1+ (1,0) [0|1] "" VDCU_M
 SG_ MCU2_LIF_DC_UNDERVO : 20|1@1+ (1,0) [0|1] "" VDCU_M
 SG_ MCU2_IGBT_TEMPSENSOR_FAULT : 21|1@1+ (1,0) [0|1] "" VDCU_M
 SG_ MCU2_RF_INVTEMP_OVERTEMP : 23|1@1+ (1,0) [0|1] "" VDCU_M
 SG_ MCU2_TORQUE_LOSTCONTROL : 24|1@1+ (1,0) [0|1] "" VDCU_M
 SG_ MCU2_MOTOR_TEMSENSOR_FAULT : 25|1@1+ (1,0) [0|1] "" VDCU_M
 SG_ MCU2_RF_MOTOR_OVERTEMP : 27|1@1+ (1,0) [0|1] "" VDCU_M
 SG_ MCU2_NRF_RDC_FAULT : 28|1@1+ (1,0) [0|1] "" VDCU_M
 SG_ MCU2_NRF_F_OVERSPEED : 29|1@1+ (1,0) [0|1] "" VDCU_M
 SG_ MCU2_RF_F_OVERSPEED : 30|1@1+ (1,0) [0|1] "" VDCU_M
 SG_ MCU2_LIF_R_OVERSPEED : 31|1@1+ (1,0) [0|1] "" VDCU_M
 SG_ MCU2_NRF_IGBT_HWTEST_FAULT : 32|1@1+ (1,0) [0|1] "" VDCU_M
 SG_ MCU2_NRF_IGBT_HWLV_VOL_FAULT : 33|1@1+ (1,0) [0|1] "" VDCU_M
 SG_ MCU2_NRF_5V_SUPPLY_FAULT : 34|1@1+ (1,0) [0|1] "" VDCU_M
 SG_ MCU2_LIF_MOTOR_OVERTEMP : 35|1@1+ (1,0) [0|1] "" VDCU_M
 SG_ MCU2_NRF_LV_VOL_SUPPLY : 36|1@1+ (1,0) [0|1] "" VDCU_M
 SG_ MCU2_LIF_INVTEMP_OVERTEMP : 37|1@1+ (1,0) [0|1] "" VDCU_M
 SG_ MCU2_NRF_CAN_BUSOFF : 38|1@1+ (1,0) [0|1] "" VDCU_M
 SG_ MCU2_RF_CAN_BUSOFF : 39|1@1+ (1,0) [0|1] "" VDCU_M
 SG_ MCU2_RF_CAN_INTERNAL_FAULT : 40|1@1+ (1,0) [0|1] "" VDCU_M
 SG_ MCU2_VCU_COM_LOST_ : 41|1@1+ (1,0) [0|1] "" VDCU_M
 SG_ MCU2_EEPRROM_FAULT_ : 42|1@1+ (1,0) [0|1] "" VDCU_M
 SG_ MCU2_LOCKED_ROTOR_FAULT : 43|1@1+ (1,0) [0|1] "" VDCU_M
 SG_ MCU2_DISCHARGE_FAULT : 44|1@1+ (1,0) [0|1] "" VDCU_M
 SG_ MCU2_SOFTWARE_INTERRUPT : 45|1@1+ (1,0) [0|1] "" VDCU_M
 SG_ MCU2_POST_FAULT : 46|1@1+ (1,0) [0|1] "" VDCU_M
 SG_ MCU2_MOTOR_SELFLEARNING_FAULT : 47|1@1+ (1,0) [0|1] "" VDCU_M
 SG_ MCU2_DATA_OVERFLOW_FAULT : 48|1@1+ (1,0) [0|1] "" VDCU_M
 SG_ MCU2_MCU_OVERLOAD_FAULT : 49|1@1+ (1,0) [0|1] "" VDCU_M
 SG_ MCU2_MOTOR_OVERLOAD_FAULT : 50|1@1+ (1,0) [0|1] "" VDCU_M
 SG_ MCU2_LIF_F_OVERSPEED : 51|1@1+ (1,0) [0|1] "" VDCU_M
 SG_ MCU2_TjIGBT_OVER_TEMP : 53|1@1+ (1,0) [0|1] "" VDCU_M
 SG_ MCU2_FS_Mw_faultiac_L3 : 54|1@1+ (1,0) [0|1] "" VDCU_M
 SG_ MCU2_FS_Mw_faultUdc_L3 : 55|1@1+ (1,0) [0|1] "" VDCU_M
 SG_ MCU2_FS_Mw_faultspeedcal_L3 : 56|1@1+ (1,0) [0|1] "" VDCU_M
 SG_ MCU2_FS_Mw_faulttorcomp_L3 : 57|1@1+ (1,0) [0|1] "" VDCU_M
 SG_ MCU2_FS_Mw_faultpwmpowerup_L3 : 58|1@1+ (1,0) [0|1] "" VDCU_M
 SG_ MCU2_FS_Mw_faultpwmpowerdown_L3 : 59|1@1+ (1,0) [0|1] "" VDCU_M
 SG_ MCU2_FS_Mw_faultpwm_L3 : 60|1@1+ (1,0) [0|1] "" VDCU_M
 SG_ MCU2_FS_Mw_faultacdischarge_L3 : 61|1@1+ (1,0) [0|1] "" VDCU_M
 SG_ MCU2_FS_Mw_faultpowermanager_L3 : 62|1@1+ (1,0) [0|1] "" VDCU_M

BO_ 2557071364 MTCU8_Axle2: 8 MTCU
 SG_ MCU2_516_CURSENSOR_SHORT_FAULT__A : 0|1@1+ (1,0) [0|1] "" VDCU_M
 SG_ MCU2_516_CURSENSOR_SHORT_FAULT__B : 1|1@1+ (1,0) [0|1] "" VDCU_M
 SG_ MCU2_516_CURSENSOR_SHORT_FAULT__C : 2|1@1+ (1,0) [0|1] "" VDCU_M
 SG_ MCU2_516_CURSENSOR_OPEN_FAULT__A : 3|1@1+ (1,0) [0|1] "" VDCU_M
 SG_ MCU2_516_CURSENSOR_OPEN_FAULT__B : 4|1@1+ (1,0) [0|1] "" VDCU_M
 SG_ MCU2_516_CURSENSOR_OPEN_FAULT__C : 5|1@1+ (1,0) [0|1] "" VDCU_M
 SG_ MCU2_516_NRF_ANGLE_FAULT : 6|1@1+ (1,0) [0|1] "" VDCU_M
 SG_ MCU2_516_RF_POWER_FAULT : 7|1@1+ (1,0) [0|1] "" VDCU_M
 SG_ MCU2_516_NRF_PHASE_LOST_FAULT : 8|1@1+ (1,0) [0|1] "" VDCU_M
 SG_ MCU2_516_NRF_HEATSINK_FAULT : 9|1@1+ (1,0) [0|1] "" VDCU_M
 SG_ MCU2_516_RF_HEATSINK_FAULT : 10|1@1+ (1,0) [0|1] "" VDCU_M
 SG_ MCU2_516_LIF_HEATSINK_FAULT : 11|1@1+ (1,0) [0|1] "" VDCU_M
 SG_ MCU2_NRF_IGBT_B_HWTEST_FAULT : 12|1@1+ (1,0) [0|1] "" VDCU_M
 SG_ MCU2_NRF_IGBT_C_HWTEST_FAULT : 13|1@1+ (1,0) [0|1] "" VDCU_M
 SG_ MCU2_NRF_PHASE_B_HW_OVERCUR : 14|1@1+ (1,0) [0|1] "" VDCU_M
 SG_ MCU2_NRF_PHASE_C_HW_OVERCUR : 15|1@1+ (1,0) [0|1] "" VDCU_M
 SG_ MCU2_NRF_PHASE_OVERCUR : 16|1@1+ (1,0) [0|1] "" VDCU_M
 SG_ MCU2_RF_PHASE_OVERCUR : 17|1@1+ (1,0) [0|1] "" VDCU_M
 SG_ MCU2_LIF_PHASE_OVERCUR : 18|1@1+ (1,0) [0|1] "" VDCU_M
 SG_ MCU2_LIF_PHASE_OVERCUR_U : 19|1@1+ (1,0) [0|1] "" VDCU_M
 SG_ MCU2_LIF_PHASE_OVERCUR_V : 20|1@1+ (1,0) [0|1] "" VDCU_M
 SG_ MCU2_LIF_PHASE_OVERCUR_W : 21|1@1+ (1,0) [0|1] "" VDCU_M
 SG_ MCU2_MCU_OVERLOAD_FAULT_A : 22|1@1+ (1,0) [0|1] "" VDCU_M
 SG_ MCU2_MCU_OVERLOAD_FAULT_B : 23|1@1+ (1,0) [0|1] "" VDCU_M
 SG_ MCU2_MCU_OVERLOAD_FAULT_C : 24|1@1+ (1,0) [0|1] "" VDCU_M
 SG_ MCU2_IGBT_TEMPSENSOR_SHORT_FAULT_B : 25|1@1+ (1,0) [0|1] "" VDCU_M
 SG_ MCU2_IGBT_TEMPSENSOR_SHORT_FAULT_C : 26|1@1+ (1,0) [0|1] "" VDCU_M
 SG_ MCU2_IGBT_TEMPSENSOR_OPEN_FAULT_A : 27|1@1+ (1,0) [0|1] "" VDCU_M
 SG_ MCU2_IGBT_TEMPSENSOR_OPEN_FAULT_B : 28|1@1+ (1,0) [0|1] "" VDCU_M
 SG_ MCU2_IGBT_TEMPSENSOR_OPEN_FAULT_C : 29|1@1+ (1,0) [0|1] "" VDCU_M
 SG_ MCU2_NRF_INVTEMP_OVERTEMP_A : 30|1@1+ (1,0) [0|1] "" VDCU_M
 SG_ MCU2_NRF_INVTEMP_OVERTEMP_B : 31|1@1+ (1,0) [0|1] "" VDCU_M
 SG_ MCU2_NRF_INVTEMP_OVERTEMP_C : 32|1@1+ (1,0) [0|1] "" VDCU_M
 SG_ MCU2_RF_INVTEMP_OVERTEMP_A : 33|1@1+ (1,0) [0|1] "" VDCU_M
 SG_ MCU2_RF_INVTEMP_OVERTEMP_B : 34|1@1+ (1,0) [0|1] "" VDCU_M
 SG_ MCU2_RF_INVTEMP_OVERTEMP_C : 35|1@1+ (1,0) [0|1] "" VDCU_M
 SG_ MCU2_LIF_INVTEMP_OVERTEMP_A : 36|1@1+ (1,0) [0|1] "" VDCU_M
 SG_ MCU2_LIF_INVTEMP_OVERTEMP_B : 37|1@1+ (1,0) [0|1] "" VDCU_M
 SG_ MCU2_LIF_INVTEMP_OVERTEMP_C : 38|1@1+ (1,0) [0|1] "" VDCU_M
 SG_ MCU2_MOTOR_TEMSENSOR_1_SHORT_FAULT : 39|1@1+ (1,0) [0|1] "" VDCU_M
 SG_ MCU2_MOTOR_TEMSENSOR_1_OPEN_FAULT : 40|1@1+ (1,0) [0|1] "" VDCU_M
 SG_ MCU2_MOTOR_TEMSENSOR_2_OPEN_FAULT : 41|1@1+ (1,0) [0|1] "" VDCU_M
 SG_ MCU2_RF_R_OVERSPEED : 42|1@1+ (1,0) [0|1] "" VDCU_M
 SG_ MCU2_NRF_LV_OVERVOL_SUPPLY : 43|1@1+ (1,0) [0|1] "" VDCU_M
 SG_ MCU2_NRF_LV_BKP_OVERVOL_SUPPLY : 44|1@1+ (1,0) [0|1] "" VDCU_M
 SG_ MCU2_NRF_LV_BKP_UNDERVOL_SUPPLY : 45|1@1+ (1,0) [0|1] "" VDCU_M
 SG_ MCU2_NRF_DC_HW_OVERVOL_2 : 46|1@1+ (1,0) [0|1] "" VDCU_M
 SG_ MCU2_NRF_DC_HW_OVERVOL_1 : 47|1@1+ (1,0) [0|1] "" VDCU_M
 SG_ MCU2_NRF_DC_HW_HVIL : 48|1@1+ (1,0) [0|1] "" VDCU_M
 SG_ MCU2_NRF_5V_DCCUR_SUPPLY_OVERVOL_FAULT : 49|1@1+ (1,0) [0|1] "" VDCU_M
 SG_ MCU2_NRF_5V_DCCUR_SUPPLY_UNDERVOL_FAULT : 50|1@1+ (1,0) [0|1] "" VDCU_M
 SG_ MCU2_NRF_5V_CUR_SUPPLY_OVERVOL_FAULT : 51|1@1+ (1,0) [0|1] "" VDCU_M
 SG_ MCU2_NRF_5V_CUR_SUPPLY_UNDERVOL_FAULT : 52|1@1+ (1,0) [0|1] "" VDCU_M
 SG_ MCU2_NRF_5V_DRV_SUPPLY_OVERVOL_FAULT : 53|1@1+ (1,0) [0|1] "" VDCU_M
 SG_ MCU2_NRF_PCBTEMP_OVERTEMP : 54|1@1+ (1,0) [0|1] "" VDCU_M
 SG_ MCU2_ACCLR_FAULT : 55|1@1+ (1,0) [0|1] "" VDCU_M

BO_ 2557136900 MTCU9_Axle2: 8 MTCU
 SG_ TCU_Power_Over_2nd : 0|1@1+ (1,0) [0|1] "" VDCU_M
 SG_ TCU_Power_Down_2nd : 1|1@1+ (1,0) [0|1] "" VDCU_M
 SG_ TCU_CPUNvm_Fault_2nd : 2|1@1+ (1,0) [0|1] "" VDCU_M
 SG_ TCU_CPURam_Fault_2nd : 3|1@1+ (1,0) [0|1] "" VDCU_M
 SG_ TCU_CPURom_Fault_2nd : 4|1@1+ (1,0) [0|1] "" VDCU_M
 SG_ TCU_Reset_Fault_2nd : 5|1@1+ (1,0) [0|1] "" VDCU_M
 SG_ TCU_System_Fault_2nd : 6|1@1+ (1,0) [0|1] "" VDCU_M
 SG_ TCU_HSD2AndPowerShort_2nd : 7|1@1+ (1,0) [0|1] "" VDCU_M
 SG_ TCU_HighPinShort_2nd : 8|1@1+ (1,0) [0|1] "" VDCU_M
 SG_ TCU_CAN1Disconnect_2nd : 9|1@1+ (1,0) [0|1] "" VDCU_M
 SG_ TCU_CAN2Disconnect_2nd : 10|1@1+ (1,0) [0|1] "" VDCU_M
 SG_ TCU_HSD1AndPowerShort_2nd : 11|1@1+ (1,0) [0|1] "" VDCU_M
 SG_ TCU_AccPdlLoss_2nd : 12|1@1+ (1,0) [0|1] "" VDCU_M
 SG_ TCU_AccPdlMessgLengthErr_2nd : 13|1@1+ (1,0) [0|1] "" VDCU_M
 SG_ TCU_AccPdlCheckSumCheckErr_2nd : 14|1@1+ (1,0) [0|1] "" VDCU_M
 SG_ TCU_AccPdlRollingCounterErr_2nd : 15|1@1+ (1,0) [0|1] "" VDCU_M
 SG_ TCU_AccPdlInvalidEnab_2nd : 16|1@1+ (1,0) [0|1] "" VDCU_M
 SG_ TCU_AccPdlEqualInvalidVal_2nd : 17|1@1+ (1,0) [0|1] "" VDCU_M
 SG_ TCU_TemSnsrOpen_2nd : 18|1@1+ (1,0) [0|1] "" VDCU_M
 SG_ TCU_TemSnsrShorttoPower_2nd : 19|1@1+ (1,0) [0|1] "" VDCU_M
 SG_ TCU_TemSnsrShorttoGround_2nd : 20|1@1+ (1,0) [0|1] "" VDCU_M
 SG_ TCU_OutSftSpdSnsrOpen_2nd : 21|1@1+ (1,0) [0|1] "" VDCU_M
 SG_ TCU_OutSftSpdShorttoPower_2nd : 22|1@1+ (1,0) [0|1] "" VDCU_M
 SG_ TCU_OutSftSpdShorttoGround_2nd : 23|1@1+ (1,0) [0|1] "" VDCU_M
 SG_ TCU_SlctGValStPCSG2_Open_2nd : 24|1@1+ (1,0) [0|1] "" VDCU_M
 SG_ TCU_SlctGValStPCSG2_ShorttoPower_2nd : 25|1@1+ (1,0) [0|1] "" VDCU_M
 SG_ TCU_SlctGValStPCSG2_ShorttoGround_2nd : 26|1@1+ (1,0) [0|1] "" VDCU_M
 SG_ TCU_SlctGValStPCSG2_OverLoad_2nd : 27|1@1+ (1,0) [0|1] "" VDCU_M
 SG_ TCU_SlctGValStPCSG2_UnderLoad_2nd : 28|1@1+ (1,0) [0|1] "" VDCU_M
 SG_ TCU_SlctGValStPCSG4_Open_2nd : 29|1@1+ (1,0) [0|1] "" VDCU_M
 SG_ TCU_SlctGValStPCSG4_ShorttoPower_2nd : 30|1@1+ (1,0) [0|1] "" VDCU_M
 SG_ TCU_SlctGValStPCSG4_ShorttoGround_2nd : 31|1@1+ (1,0) [0|1] "" VDCU_M
 SG_ TCU_SlctGValStPCSG4_OverLoad_2nd : 32|1@1+ (1,0) [0|1] "" VDCU_M
 SG_ TCU_SlctGValStPCSG4_UnderLoad_2nd : 33|1@1+ (1,0) [0|1] "" VDCU_M
 SG_ TCU_SlctGValStPCSS3_Open_2nd : 34|1@1+ (1,0) [0|1] "" VDCU_M
 SG_ TCU_SlctGValStPCSS3_ShorttoPower_2nd : 35|1@1+ (1,0) [0|1] "" VDCU_M
 SG_ TCU_SlctGValStPCSS3_ShorttoGround_2nd : 36|1@1+ (1,0) [0|1] "" VDCU_M
 SG_ TCU_SlctGValStPCSS3_OverLoad_2nd : 37|1@1+ (1,0) [0|1] "" VDCU_M
 SG_ TCU_SlctGValStPCSS3_UnderLoad_2nd : 38|1@1+ (1,0) [0|1] "" VDCU_M
 SG_ TCU_SlctGValStPCSS4_Open_2nd : 39|1@1+ (1,0) [0|1] "" VDCU_M
 SG_ TCU_SlctGValStPCSS4_ShorttoPower_2nd : 40|1@1+ (1,0) [0|1] "" VDCU_M
 SG_ TCU_SlctGValStPCSS4_ShorttoGround_2nd : 41|1@1+ (1,0) [0|1] "" VDCU_M
 SG_ TCU_SlctGValStPCSS4_OverLoad_2nd : 42|1@1+ (1,0) [0|1] "" VDCU_M
 SG_ TCU_SlctGValStPCSS4_UnderLoad_2nd : 43|1@1+ (1,0) [0|1] "" VDCU_M
 SG_ TCU_9VElectricity_OverHigh_2nd : 44|1@1+ (1,0) [0|1] "" VDCU_M
 SG_ TCU_9VElectricity_OverLow_2nd : 45|1@1+ (1,0) [0|1] "" VDCU_M
 SG_ TCU_9VElectricityAndPow_Short_2nd : 46|1@1+ (1,0) [0|1] "" VDCU_M
 SG_ TCU_9VElectricityAndGnd_Short_2nd : 47|1@1+ (1,0) [0|1] "" VDCU_M
 SG_ TCU_HSD1_Broken_2nd : 48|1@1+ (1,0) [0|1] "" VDCU_M
 SG_ TCU_HSD1AndGnd_Broken_2nd : 49|1@1+ (1,0) [0|1] "" VDCU_M
 SG_ TCU_HSD2_Broken_2nd : 50|1@1+ (1,0) [0|1] "" VDCU_M
 SG_ TCU_HSD2AndGnd_Broken_2nd : 51|1@1+ (1,0) [0|1] "" VDCU_M
 SG_ TCU_CAN1Node_Fault_2nd : 52|1@1+ (1,0) [0|1] "" VDCU_M
 SG_ TCU_CANBus_Silence_2nd : 53|1@1+ (1,0) [0|1] "" VDCU_M
 SG_ TCU_CAN2Node_Fault_2nd : 54|1@1+ (1,0) [0|1] "" VDCU_M
 SG_ TCU_PosSensorD_Broken_2nd : 55|1@1+ (1,0) [0|1] "" VDCU_M
 SG_ TCU_PosSensorDAndPow_Broken_2nd : 56|1@1+ (1,0) [0|1] "" VDCU_M
 SG_ TCU_PosSensorDAndGnd_Broken_2nd : 57|1@1+ (1,0) [0|1] "" VDCU_M
 SG_ TCU_PosSensorE_Broken_2nd : 58|1@1+ (1,0) [0|1] "" VDCU_M
 SG_ TCU_PosSensorEAndPow_Broken_2nd : 59|1@1+ (1,0) [0|1] "" VDCU_M
 SG_ TCU_PosSensorEAndGnd_Broken_2nd : 60|1@1+ (1,0) [0|1] "" VDCU_M
 SG_ TCU_PrssSenso_Broken_2nd : 61|1@1+ (1,0) [0|1] "" VDCU_M
 SG_ TCU_PrssSensoAndPow_Broken_2nd : 62|1@1+ (1,0) [0|1] "" VDCU_M
 SG_ TCU_PrssSensoAndGnd_Broken_2nd : 63|1@1+ (1,0) [0|1] "" VDCU_M

BO_ 2557202436 MTCU10_Axle2: 8 MTCU
 SG_ TCU_5VElectricity_OverHigh_2nd : 0|1@1+ (1,0) [0|1] "" VDCU_M
 SG_ TCU_5VElectricity_OverLow_2nd : 1|1@1+ (1,0) [0|1] "" VDCU_M
 SG_ TCU_5VElectricityAndPow_Short_2nd : 2|1@1+ (1,0) [0|1] "" VDCU_M
 SG_ TCU_5VElectricityAndGnd_Short_2nd : 3|1@1+ (1,0) [0|1] "" VDCU_M
 SG_ TCU_VehSpd_Lost_2nd : 4|1@1+ (1,0) [0|1] "" VDCU_M
 SG_ TCU_VehSpdMessLength_Fault_2nd : 5|1@1+ (1,0) [0|1] "" VDCU_M
 SG_ TCU_VehSpdChecSum_Fault_2nd : 6|1@1+ (1,0) [0|1] "" VDCU_M
 SG_ TCU_VehSpd_InvalidFg_2nd : 7|1@1+ (1,0) [0|1] "" VDCU_M
 SG_ TCU_VehSpd_Invalid_2nd : 8|1@1+ (1,0) [0|1] "" VDCU_M
 SG_ TCU_OilTemp_level3_2nd : 9|1@1+ (1,0) [0|1] "" VDCU_M
 SG_ TCU_OilTemp_level4_2nd : 10|1@1+ (1,0) [0|1] "" VDCU_M
 SG_ TCU_ATFOilTemp_Low_2nd : 11|1@1+ (1,0) [0|1] "" VDCU_M
 SG_ TCU_ATFOilTemp_Hop_2nd : 12|1@1+ (1,0) [0|1] "" VDCU_M
 SG_ TCU_OptSftSpd_High_2nd : 13|1@1+ (1,0) [0|1] "" VDCU_M
 SG_ TCU_OptSftSpd_Hop_2nd : 14|1@1+ (1,0) [0|1] "" VDCU_M
 SG_ TCU_OptSftSpd_Zero_2nd : 15|1@1+ (1,0) [0|1] "" VDCU_M
 SG_ TCU_SftOG_Stuk_2nd : 16|1@1+ (1,0) [0|1] "" VDCU_M
 SG_ TCU_TqResponse_Failure_2nd : 17|1@1+ (1,0) [0|1] "" VDCU_M
 SG_ TCU_SftIG_Stuk_2nd : 18|1@1+ (1,0) [0|1] "" VDCU_M
 SG_ TCU_RollingCounter_Fault_2nd : 19|1@1+ (1,0) [0|1] "" VDCU_M
 SG_ TCU_PowOn_Failure_2nd : 20|1@1+ (1,0) [0|1] "" VDCU_M
 SG_ TCU_PowOff_Failure_2nd : 21|1@1+ (1,0) [0|1] "" VDCU_M
 SG_ TCU_OilTemp_level1_2nd : 22|1@1+ (1,0) [0|1] "" VDCU_M
 SG_ TCU_OilTemp_level2_2nd : 23|1@1+ (1,0) [0|1] "" VDCU_M

BO_ 2566899716 CR1_Axle2: 8 MTCU
 SG_ Coolant_Request_Axle2 : 0|16@1+ (0.03125,-273) [-273|1734.94] "°C" VDCU_M
 SG_ Coolant_flow_request_Axle2 : 16|16@1+ (0.1,0) [0|6425.5] "l/min" VDCU_M

BO_ 2566840580 RC1_Axle2: 20 MTCU
 SG_ Retarder_Type_Axle2 : 0|4@1+ (1,0) [0|15] "" VDCU_M
 SG_ Retarder_Location_Axle2 : 4|4@1+ (1,0) [0|15] "" VDCU_M
 SG_ Retarder_Speed_at_Idle_point1_Axle2 : 16|16@1+ (0.125,0) [0|8031.875] "rpm" VDCU_M
 SG_ RC_Percent_Torque_at_Idle_point1_Axle2 : 32|8@1+ (1,-125) [-125|125] "%" VDCU_M
 SG_ Maximum_Retarder_Speed_point2_Axle2 : 40|16@1+ (0.125,0) [0|8031.875] "rpm" VDCU_M
 SG_ RC_Percent_Torque_at_maximum_Speed_point2_Axle2 : 56|8@1+ (1,-125) [-125|125] "%" VDCU_M
 SG_ Retarder_Speed_at_point3_Axle2 : 64|16@1+ (0.125,0) [0|8031.875] "rpm" VDCU_M
 SG_ RC_Percent_Torque_at_point3_Axle2 : 80|8@1+ (1,-125) [-125|125] "%" VDCU_M
 SG_ Retarder_Speed_at_point4_Axle2 : 88|16@1+ (0.125,0) [0|8031.875] "rpm" VDCU_M
 SG_ RC_Percent_Torque_at_point4_Axle2 : 104|8@1+ (1,-125) [-125|125] "%" VDCU_M
 SG_ Retarder_Speed_at_peak_Torque_point5_Axle2 : 112|16@1+ (1,0) [0|64255] "Nm" VDCU_M
 SG_ Reference_Retarder_Torque_Axle2 : 128|16@1+ (1,0) [0|64255] "Nm" VDCU_M
 SG_ RC_Percent_Torque_at_point5_Axle2 : 144|8@1+ (1,-125) [-125|125] "%" VDCU_M

BO_ 2566841178 EC1: 48 MTCU
 SG_ EMotor_speed_at_idle_Point1 : 0|16@1+ (0.125,0) [0|8031.875] "rpm" VDCU_M
 SG_ EC_Percent_Torque_at_Idle_Point1 : 16|8@1+ (1,-125) [-125|125] "%" VDCU_M
 SG_ EMotor_Speed_at_Point2 : 24|16@1+ (0.125,0) [0|8031.875] "rpm" VDCU_M
 SG_ EC_Percent_Torque_at_Point2 : 40|8@1+ (1,-125) [-125|125] "%" VDCU_M
 SG_ EMotor_Speed_at_Point3 : 48|16@1+ (0.125,0) [0|8031.875] "rpm" VDCU_M
 SG_ EC_Percent_Torque_at_Point3 : 64|8@1+ (1,-125) [-125|125] "%" VDCU_M
 SG_ EMotor_Speed_at_Point4 : 72|16@1+ (0.125,0) [0|8031.875] "rpm" VDCU_M
 SG_ EC_Percent_Torque_at_Point4 : 88|8@1+ (1,-125) [-125|125] "%" VDCU_M
 SG_ EMotor_Speed_at_Point5 : 96|16@1+ (0.125,0) [0|8031.875] "rpm" VDCU_M
 SG_ EC_Percent_Torque_at_Point5 : 112|8@1+ (1,-125) [-125|125] "%" VDCU_M
 SG_ EMotor_reference_torque : 152|16@1+ (1,0) [0|64255] "Nm" VDCU_M

BO_ 2566841092 EC1_Axle2: 48 MTCU
 SG_ EMotor_speed_at_idle_Point1_Axle2 : 0|16@1+ (0.125,0) [0|8031.875] "rpm" VDCU_M
 SG_ EC_Percent_Torque_at_Idle_Point1_Axle2 : 16|8@1+ (1,-125) [-125|125] "%" VDCU_M
 SG_ EMotor_Speed_at_Point2_Axle2 : 24|16@1+ (0.125,0) [0|8031.875] "rpm" VDCU_M
 SG_ EC_Percent_Torque_at_Point2_Axle2 : 40|8@1+ (1,-125) [-125|125] "%" VDCU_M
 SG_ EMotor_Speed_at_Point3_Axle2 : 48|16@1+ (0.125,0) [0|8031.875] "rpm" VDCU_M
 SG_ EC_Percent_Torque_at_Point3_Axle2 : 64|8@1+ (1,-125) [-125|125] "%" VDCU_M
 SG_ EMotor_Speed_at_Point4_Axle2 : 72|16@1+ (0.125,0) [0|8031.875] "rpm" VDCU_M
 SG_ EC_Percent_Torque_at_Point4_Axle2 : 88|8@1+ (1,-125) [-125|125] "%" VDCU_M
 SG_ EMotor_Speed_at_Point5_Axle2 : 96|16@1+ (0.125,0) [0|8031.875] "rpm" VDCU_M
 SG_ EC_Percent_Torque_at_Point5_Axle2 : 112|8@1+ (1,-125) [-125|125] "%" VDCU_M
 SG_ EMotor_reference_torque_Axle2 : 152|16@1+ (1,0) [0|64255] "Nm" VDCU_M

BO_ 2364539994 EEC1: 8 MTCU
 SG_ EMotor_TrqRet_Mode : 0|4@1+ (1,0) [0|15] "" VDCU_M
 SG_ Actual_EMotor_Percent_Torque_high_resolution : 4|4@1+ (0.125,0) [0|0.875] "%" VDCU_M
 SG_ Drivers_Demand_EMotor_Percent_Torque : 8|8@1+ (1,-125) [-125|125] "%" VDCU_M
 SG_ E_Actual_EMotor_Percent_Torque : 16|8@1+ (1,-125) [-125|125] "%" VDCU_M
 SG_ EMotor_Speed : 24|16@1+ (0.125,0) [0|8031.875] "rpm" VDCU_M
 SG_ Source_Adress_of_Ctrl_Device : 40|8@1+ (1,0) [0|255] "" VDCU_M

BO_ 2364539738 EEC2: 8 MTCU
 SG_ Actual_Maximum_Available_Engine_Percent_Torque : 48|8@1+ (0.4,0) [0|100] "%" VDCU_M

BO_ 2566840154 EEC3: 8 MTCU
 SG_ Nominal_FrictionPercent_Torque : 0|8@1+ (1,-125) [-125|125] "%" VDCU_M
 SG_ Engine_EMotor_Parasitic_Losses : 32|8@1+ (1,-125) [-125|125] "%" VDCU_M

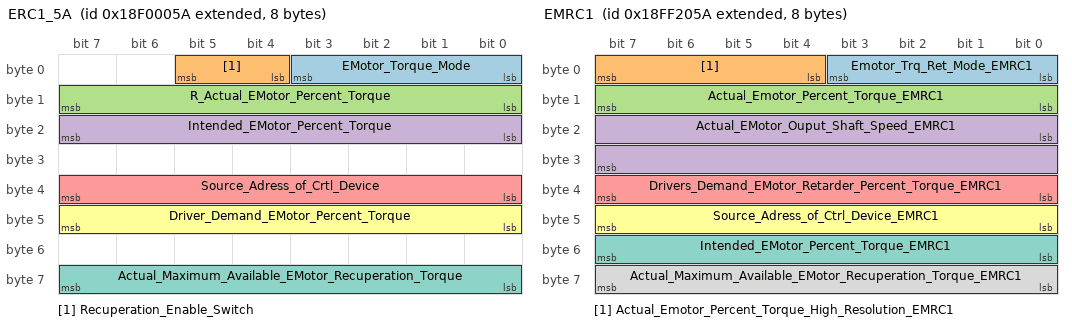
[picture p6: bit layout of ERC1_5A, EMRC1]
BO_ 2565865562 ERC1_5A: 8 MTCU
 SG_ EMotor_Torque_Mode : 0|4@1+ (1,0) [0|15] "" VDCU_M
 SG_ Recuperation_Enable_Switch : 4|2@1+ (1,0) [0|1] "" VDCU_M
 SG_ R_Actual_EMotor_Percent_Torque : 8|8@1+ (1,-125) [-125|125] "%" VDCU_M
 SG_ Intended_EMotor_Percent_Torque : 16|8@1+ (1,-125) [-125|125] "%" VDCU_M
 SG_ Source_Adress_of_Crtl_Device : 32|8@1+ (1,0) [0|255] "" VDCU_M
 SG_ Driver_Demand_EMotor_Percent_Torque : 40|8@1+ (1,-125) [-125|125] "%" VDCU_M
 SG_ Actual_Maximum_Available_EMotor_Recuperation_Torque : 56|8@1+ (1,-125) [-125|125] "%" VDCU_M

BO_ 2566856794 EMRC1: 8 MTCU
 SG_ Emotor_Trq_Ret_Mode_EMRC1 : 0|4@1+ (1,0) [0|15] "" VDCU_M
 SG_ Actual_Emotor_Percent_Torque_High_Resolution_EMRC1 : 4|4@1+ (0.125,0) [0|0.875] "%" VDCU_M
 SG_ Actual_Emotor_Percent_Torque_EMRC1 : 8|8@1+ (1,0) [0|0.875] "%" VDCU_M
 SG_ Actual_EMotor_Ouput_Shaft_Speed_EMRC1 : 16|16@1+ (0.25,0) [0|16255] "rpm" VDCU_M
 SG_ Drivers_Demand_EMotor_Retarder_Percent_Torque_EMRC1 : 32|8@1+ (1,-125) [-125|125] "%" VDCU_M
 SG_ Source_Adress_of_Ctrl_Device_EMRC1 : 40|8@1+ (1,0) [0|255] "" VDCU_M
 SG_ Intended_EMotor_Percent_Torque_EMRC1 : 48|8@1+ (1,-125) [-125|125] "%" VDCU_M
 SG_ Actual_Maximum_Available_EMotor_Recuperation_Torque_EMRC1 : 56|8@1+ (1,-125) [-125|125] "%" VDCU_M

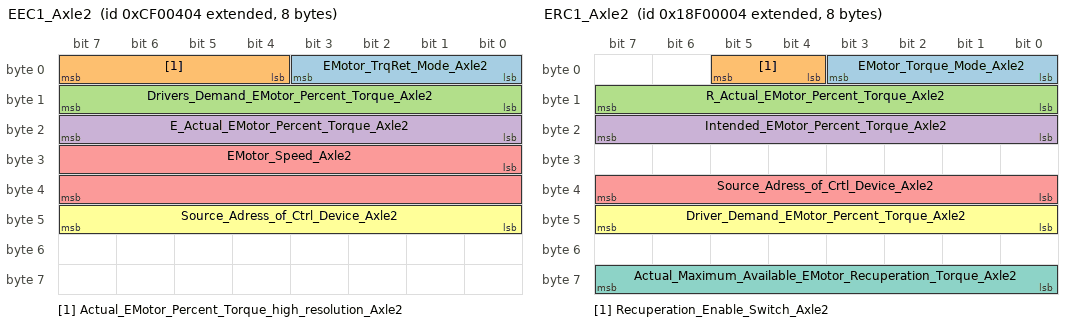
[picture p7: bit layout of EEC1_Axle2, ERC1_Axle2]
BO_ 2364539908 EEC1_Axle2: 8 MTCU
 SG_ EMotor_TrqRet_Mode_Axle2 : 0|4@1+ (1,0) [0|15] "" VDCU_M
 SG_ Actual_EMotor_Percent_Torque_high_resolution_Axle2 : 4|4@1+ (0.125,0) [0|0.875] "%" VDCU_M
 SG_ Drivers_Demand_EMotor_Percent_Torque_Axle2 : 8|8@1+ (1,-125) [-125|125] "%" VDCU_M
 SG_ E_Actual_EMotor_Percent_Torque_Axle2 : 16|8@1+ (1,-125) [-125|125] "%" VDCU_M
 SG_ EMotor_Speed_Axle2 : 24|16@1+ (0.125,0) [0|8031.875] "rpm" VDCU_M
 SG_ Source_Adress_of_Ctrl_Device_Axle2 : 40|8@1+ (1,0) [0|255] "" VDCU_M

BO_ 2364539652 EEC2_Axle2: 8 MTCU
 SG_ Actual_Maximum_Available_Engine_Percent_Torque_Axle2 : 48|8@1+ (0.4,0) [0|100] "%" VDCU_M

BO_ 2566840068 EEC3_Axle2: 8 MTCU
 SG_ Nominal_FrictionPercent_Torque_Axle2 : 0|8@1+ (1,-125) [-125|125] "%" VDCU_M
 SG_ Engine_EMotor_Parasitic_Losses_Axle2 : 32|8@1+ (1,-125) [-125|125] "%" VDCU_M

BO_ 2565865476 ERC1_Axle2: 8 MTCU
 SG_ EMotor_Torque_Mode_Axle2 : 0|4@1+ (1,0) [0|15] "" VDCU_M
 SG_ Recuperation_Enable_Switch_Axle2 : 4|2@1+ (1,0) [0|1] "" VDCU_M
 SG_ R_Actual_EMotor_Percent_Torque_Axle2 : 8|8@1+ (1,-125) [-125|125] "%" VDCU_M
 SG_ Intended_EMotor_Percent_Torque_Axle2 : 16|8@1+ (1,-125) [-125|125] "%" VDCU_M
 SG_ Source_Adress_of_Crtl_Device_Axle2 : 32|8@1+ (1,0) [0|255] "" VDCU_M
 SG_ Driver_Demand_EMotor_Percent_Torque_Axle2 : 40|8@1+ (1,-125) [-125|125] "%" VDCU_M
 SG_ Actual_Maximum_Available_EMotor_Recuperation_Torque_Axle2 : 56|8@1+ (1,-125) [-125|125] "%" VDCU_M

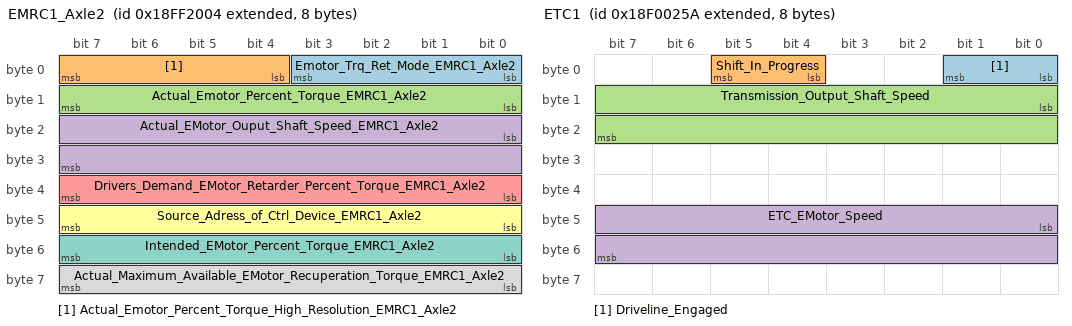
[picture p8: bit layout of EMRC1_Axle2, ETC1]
BO_ 2566856708 EMRC1_Axle2: 8 MTCU
 SG_ Emotor_Trq_Ret_Mode_EMRC1_Axle2 : 0|4@1+ (1,0) [0|15] "" VDCU_M
 SG_ Actual_Emotor_Percent_Torque_High_Resolution_EMRC1_Axle2 : 4|4@1+ (0.125,0) [0|0.875] "%" VDCU_M
 SG_ Actual_Emotor_Percent_Torque_EMRC1_Axle2 : 8|8@1+ (1,0) [0|0.875] "%" VDCU_M
 SG_ Actual_EMotor_Ouput_Shaft_Speed_EMRC1_Axle2 : 16|16@1+ (0.25,0) [0|16255] "rpm" VDCU_M
 SG_ Drivers_Demand_EMotor_Retarder_Percent_Torque_EMRC1_Axle2 : 32|8@1+ (1,-125) [-125|125] "%" VDCU_M
 SG_ Source_Adress_of_Ctrl_Device_EMRC1_Axle2 : 40|8@1+ (1,0) [0|255] "" VDCU_M
 SG_ Intended_EMotor_Percent_Torque_EMRC1_Axle2 : 48|8@1+ (1,-125) [-125|125] "%" VDCU_M
 SG_ Actual_Maximum_Available_EMotor_Recuperation_Torque_EMRC1_Axle2 : 56|8@1+ (1,-125) [-125|125] "%" VDCU_M

BO_ 2565866074 ETC1: 8 MTCU
 SG_ Driveline_Engaged : 0|2@1+ (1,0) [0|3] "" VDCU_M
 SG_ Shift_In_Progress : 4|2@1+ (1,0) [0|1] "" VDCU_M
 SG_ Transmission_Output_Shaft_Speed : 8|16@1+ (0.125,0) [0|8031.875] "rpm" VDCU_M
 SG_ ETC_EMotor_Speed : 40|16@1+ (0.125,0) [0|8031.875] "rpm" VDCU_M

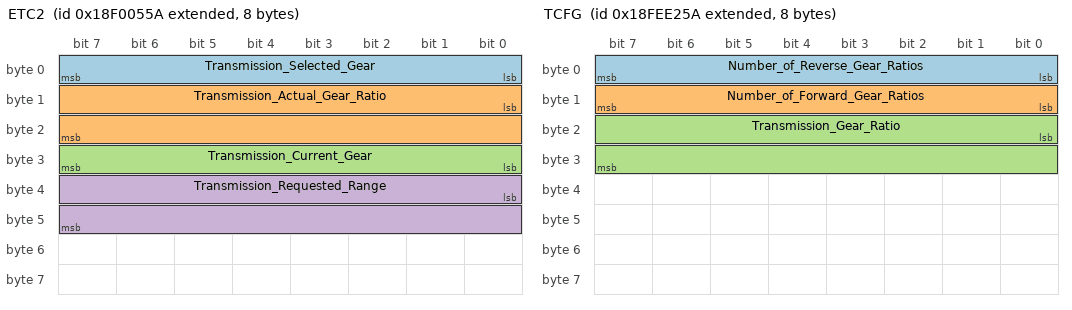
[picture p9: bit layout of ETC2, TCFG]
BO_ 2565866842 ETC2: 8 MTCU
 SG_ Transmission_Selected_Gear : 0|8@1+ (1,-125) [-125|125] "" VDCU_M
 SG_ Transmission_Actual_Gear_Ratio : 8|16@1+ (0.001,0) [0|64.255] "ratio" VDCU_M
 SG_ Transmission_Current_Gear : 24|8@1+ (1,-125) [-125|125] "" VDCU_M
 SG_ Transmission_Requested_Range : 32|16@1+ (1,0) [0|255] "ASC" VDCU_M

BO_ 2566802010 ETC7: 8 MTCU
 SG_ Transmission_Ready_for_Brake_Release : 8|2@1+ (1,0) [0|3] "" VDCU_M

BO_ 2566840922 TCFG: 8 MTCU
 SG_ Number_of_Reverse_Gear_Ratios : 0|8@1+ (1,0) [0|250] "" VDCU_M
 SG_ Number_of_Forward_Gear_Ratios : 8|8@1+ (1,0) [0|250] "" VDCU_M
 SG_ Transmission_Gear_Ratio : 16|16@1+ (0.001,0) [0|64.255] "" VDCU_M

BO_ 2566846554 TRF1: 8 MTCU
 SG_ Transmission_Oil_Temperature1 : 32|16@1+ (0.03125,-273) [-273|1734.96875] "°C" VDCU_M

BO_ 2565867098 EAC1: 8 MTCU
 SG_ DiffLockStateRearAxle1_EAC1 : 12|2@1+ (1,0) [0|3] "" VDCU_M

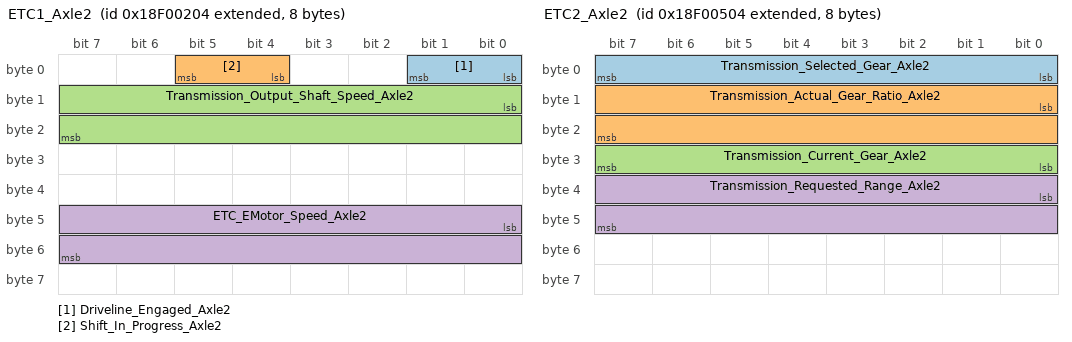
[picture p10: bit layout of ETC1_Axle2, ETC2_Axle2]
BO_ 2565865988 ETC1_Axle2: 8 MTCU
 SG_ Driveline_Engaged_Axle2 : 0|2@1+ (1,0) [0|3] "" VDCU_M
 SG_ Shift_In_Progress_Axle2 : 4|2@1+ (1,0) [0|1] "" VDCU_M
 SG_ Transmission_Output_Shaft_Speed_Axle2 : 8|16@1+ (0.125,0) [0|8031.875] "rpm" VDCU_M
 SG_ ETC_EMotor_Speed_Axle2 : 40|16@1+ (0.125,0) [0|8031.875] "rpm" VDCU_M

BO_ 2565866756 ETC2_Axle2: 8 MTCU
 SG_ Transmission_Selected_Gear_Axle2 : 0|8@1+ (1,-125) [-125|125] "" VDCU_M
 SG_ Transmission_Actual_Gear_Ratio_Axle2 : 8|16@1+ (0.001,0) [0|64.255] "ratio" VDCU_M
 SG_ Transmission_Current_Gear_Axle2 : 24|8@1+ (1,-125) [-125|125] "" VDCU_M
 SG_ Transmission_Requested_Range_Axle2 : 32|16@1+ (1,0) [0|255] "ASC" VDCU_M

BO_ 2566801924 ETC7_Axle_2: 8 MTCU
 SG_ Transmission_Ready_for_Brake_Release_Axle2 : 8|2@1+ (1,0) [0|3] "" VDCU_M

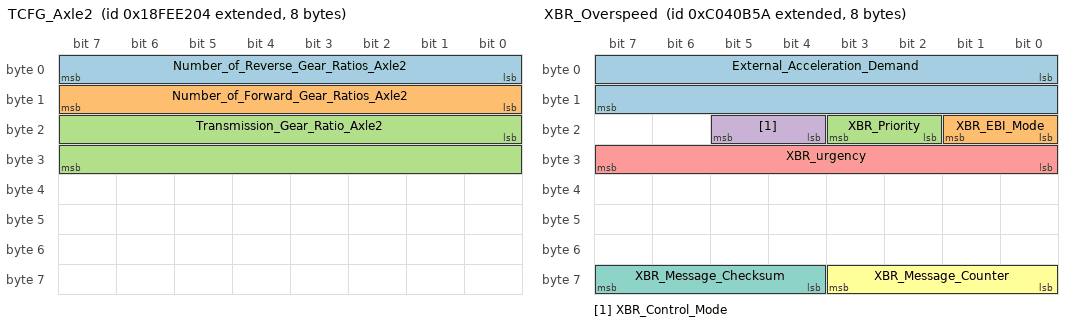
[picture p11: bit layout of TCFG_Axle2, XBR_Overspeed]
BO_ 2566840836 TCFG_Axle2: 8 MTCU
 SG_ Number_of_Reverse_Gear_Ratios_Axle2 : 0|8@1+ (1,0) [0|250] "" VDCU_M
 SG_ Number_of_Forward_Gear_Ratios_Axle2 : 8|8@1+ (1,0) [0|250] "" VDCU_M
 SG_ Transmission_Gear_Ratio_Axle2 : 16|16@1+ (0.001,0) [0|64.255] "" VDCU_M

BO_ 2566846468 TRF1_Axle2: 8 MTCU
 SG_ Transmission_Oil_Temperature1_Axle2 : 32|16@1+ (0.03125,-273) [-273|1734.96875] "°C" VDCU_M

BO_ 2565867012 EAC1_Axel2: 8 MTCU
 SG_ DiffLockStateRearAxle2_EAC1 : 14|2@1+ (1,0) [0|3] "" VDCU_M

BO_ 2349075290 XBR_Overspeed: 8 MTCU
 SG_ External_Acceleration_Demand : 0|16@1+ (4.8828125E-4,-15.687) [-15.687|15.687] "m/s?" VDCU_M
 SG_ XBR_EBI_Mode : 16|2@1+ (1,0) [0|3] "" VDCU_M
 SG_ XBR_Priority : 18|2@1+ (1,0) [0|3] "" VDCU_M
 SG_ XBR_Control_Mode : 20|2@1+ (1,0) [0|3] "" VDCU_M
 SG_ XBR_urgency : 24|8@1+ (1,0) [0|255] "" VDCU_M
 SG_ XBR_Message_Counter : 56|4@1+ (1,0) [0|15] "" VDCU_M
 SG_ XBR_Message_Checksum : 60|4@1+ (1,0) [0|15] "" VDCU_M

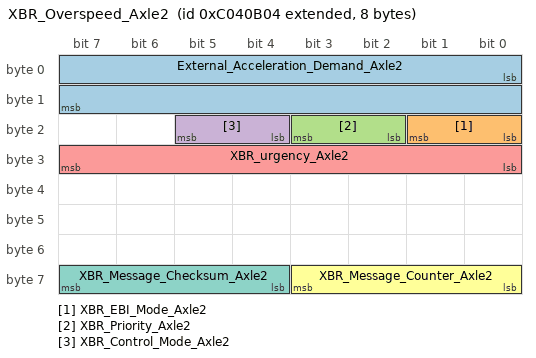
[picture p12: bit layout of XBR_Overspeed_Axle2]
BO_ 2349075204 XBR_Overspeed_Axle2: 8 MTCU
 SG_ External_Acceleration_Demand_Axle2 : 0|16@1+ (4.8828125E-4,-15.687) [-15.687|15.687] "m/s?" VDCU_M
 SG_ XBR_EBI_Mode_Axle2 : 16|2@1+ (1,0) [0|3] "" VDCU_M
 SG_ XBR_Priority_Axle2 : 18|2@1+ (1,0) [0|3] "" VDCU_M
 SG_ XBR_Control_Mode_Axle2 : 20|2@1+ (1,0) [0|3] "" VDCU_M
 SG_ XBR_urgency_Axle2 : 24|8@1+ (1,0) [0|255] "" VDCU_M
 SG_ XBR_Message_Counter_Axle2 : 56|4@1+ (1,0) [0|15] "" VDCU_M
 SG_ XBR_Message_Checksum_Axle2 : 60|4@1+ (1,0) [0|15] "" VDCU_M

BO_ 2355941466 Towing: 8 MTCU
 SG_ Allowed_Towing_Mode : 16|3@1+ (1,0) [0|7] "" VDCU_M
 SG_ Towing_Error : 19|4@1+ (1,0) [0|15] "" VDCU_M

BO_ 2355941380 Towing_Axle2: 8 MTCU
 SG_ Allowed_Towing_Mode_Axle2 : 16|3@1+ (1,0) [0|7] "" VDCU_M
 SG_ Towing_Error_Axle2 : 19|4@1+ (1,0) [0|15] "" VDCU_M

CM_ SG_ 2566834778 ProtectLampStatus_MTCU "This lamp is used to relay trouble code information that is reporting a problem with a vehicle system that is most probably not electronic subsystem related. For instance, engine coolant temperature is exceeding its prescribed temperature range.00 ...";
CM_ SG_ 2566834778 AmberWarningLampStatus_MTCU "This lamp is used to relay trouble code information that is reporting a problem with the vehicle system but the vehicle need not be immediately stopped. 00     Lamp Off01     Lamp On10     Reserved11     Not available";
CM_ SG_ 2566834778 RedStopLampState_MTCU "This lamp is used to relay trouble code information that is of a severe enough condition that it warrants stopping the vehicle.00     Lamp Off01     Lamp On10     Reserved11     Not available";
CM_ SG_ 2566834778 MalfunctionIndicatorLampStatus_MTCU "A lamp used to relay only emissions-related trouble code information. This lamp is only illuminated when there is an emission-related trouble code active.00     Lamp Off01     Lamp On10     Short MIL for WWH OBD11     Not availableNote ...";
CM_ SG_ 2566834778 FlashProtectLamp_MTCU "This parameter provides the capability to flash the engine protect lamp00 - Slow Flash (1 Hz, 50 % duty cycle)01 - Fast Flash (2 Hz or faster, 50% duty cycle)10 - Reserved11 - Unavailable / Do Not Flash";
CM_ SG_ 2566834778 FlashAmberWarningLamp_MTCU "This parameter provides the capability to flash the AWL00 - Slow Flash (1 Hz, 50 % duty cycle)01 - Fast Flash (2 Hz or faster, 50% duty cycle)10 - Reserved11 - Unavailable / Do Not Flash";
CM_ SG_ 2566834778 FlashRedStopLamp_MTCU "This parameter provides the capability to flash the RSL00 - Slow Flash (1 Hz, 50 % duty cycle)01 - Fast Flash (2 Hz or faster, 50% duty cycle)10 - Reserved11 - Unavailable / Do Not Flash";
CM_ SG_ 2566834778 FlashMalfuncIndicatorLamp_MTCU "This parameter provides the capability to flash the MIL00 - Slow Flash (1 Hz, 50 % duty cycle)01 - Fast Flash (2 Hz or faster, 50% duty cycle)10 - Class C DTC11 - Unavailable / Do Not FlashNote:  State 10 is for WWH OBD discriminatory ...";
CM_ SG_ 2566834778 DTC1_MTCU "Diagnostic Trouble Code";
CM_ SG_ 2566834778 DTC2_MTCU "Diagnostic Trouble Code";
CM_ SG_ 2566834778 DTC3_MTCU "Diagnostic Trouble Code";
CM_ SG_ 2566834778 DTC4_MTCU "Diagnostic Trouble Code";
CM_ SG_ 2566834778 DTC5_MTCU "Diagnostic Trouble Code";
CM_ SG_ 2566834692 ProtectLampStatus_MTCU_Axle2 "This lamp is used to relay trouble code information that is reporting a problem with a vehicle system that is most probably not electronic subsystem related. For instance, engine coolant temperature is exceeding its prescribed temperature range.00 ...";
CM_ SG_ 2566834692 AmberWarningLampStatus_MTCU_Axle2 "This lamp is used to relay trouble code information that is reporting a problem with the vehicle system but the vehicle need not be immediately stopped. 00     Lamp Off01     Lamp On10     Reserved11     Not available";
CM_ SG_ 2566834692 RedStopLampState_MTCU_Axle2 "This lamp is used to relay trouble code information that is of a severe enough condition that it warrants stopping the vehicle.00     Lamp Off01     Lamp On10     Reserved11     Not available";
CM_ SG_ 2566834692 MalfunctionIndicatorLampStatus_MTCU_Axle2 "A lamp used to relay only emissions-related trouble code information. This lamp is only illuminated when there is an emission-related trouble code active.00     Lamp Off01     Lamp On10     Short MIL for WWH OBD11     Not availableNote ...";
CM_ SG_ 2566834692 FlashProtectLamp_MTCU_Axle2 "This parameter provides the capability to flash the engine protect lamp00 - Slow Flash (1 Hz, 50 % duty cycle)01 - Fast Flash (2 Hz or faster, 50% duty cycle)10 - Reserved11 - Unavailable / Do Not Flash";
CM_ SG_ 2566834692 FlashAmberWarningLamp_MTCU_Axle2 "This parameter provides the capability to flash the AWL00 - Slow Flash (1 Hz, 50 % duty cycle)01 - Fast Flash (2 Hz or faster, 50% duty cycle)10 - Reserved11 - Unavailable / Do Not Flash";
CM_ SG_ 2566834692 FlashRedStopLamp_MTCU_Axle2 "This parameter provides the capability to flash the RSL00 - Slow Flash (1 Hz, 50 % duty cycle)01 - Fast Flash (2 Hz or faster, 50% duty cycle)10 - Reserved11 - Unavailable / Do Not Flash";
CM_ SG_ 2566834692 FlashMalfuncIndicatorLamp_MTCU_Axle2 "This parameter provides the capability to flash the MIL00 - Slow Flash (1 Hz, 50 % duty cycle)01 - Fast Flash (2 Hz or faster, 50% duty cycle)10 - Class C DTC11 - Unavailable / Do Not FlashNote:  State 10 is for WWH OBD discriminatory ...";
CM_ SG_ 2566834692 DTC1_MTCU_Axle2 "Diagnostic Trouble Code";
CM_ SG_ 2566834692 DTC2_MTCU_Axle2 "Diagnostic Trouble Code";
CM_ SG_ 2566834692 DTC3_MTCU_Axle2 "Diagnostic Trouble Code";
CM_ SG_ 2566834692 DTC4_MTCU_Axle2 "Diagnostic Trouble Code";
CM_ SG_ 2566834692 DTC5_MTCU_Axle2 "Diagnostic Trouble Code";
CM_ SG_ 2355220570 Actual_Driving_direction_AVE_System "Driving direction of the Vehicle (for using in a display, ..)";
CM_ SG_ 2355220570 Actual_Drive_mode "Working mode of AVE130-System";
CM_ SG_ 2355220570 Wheel_Slippage_detection "Wheel slippage is detected on the Wheel (compare to Front Axle Speed), and specific torque reduction is active";
CM_ SG_ 2355220570 Average_EMotor_speed "E-Motor-Speed (unsigned)Average E-Motor-Speed of both E-Motors";
CM_ SG_ 2355220570 Actual_torque_AX_System "E-Motor-Torque (unsigned)Average E-Motor-Torque of both E-Motors";
CM_ SG_ 2355220570 AX2_System_Ready "Ready Status of the System";
CM_ SG_ 2355220570 Cooling_Afterrun_Request "KL30 Power is still requested for keeping Cooling and Oil Pump running, after KL15 off";
CM_ SG_ 2355220570 EMotor_Overspeed "Displays that the Emotor Speed is in critical speed range and the Driver should brake the vehicle to reduce the maximum allowed driveline speed";
CM_ SG_ 2355220570 EVECU1_MSG_Counter "optional available";
CM_ SG_ 2355220570 EVEC1_MSG_CRC "optional available";
CM_ SG_ 2355286106 DC_Current_Edrive_System "Sum DC_Current of both E-Motors";
CM_ SG_ 2355286106 DC_Voltage_Edrive_System "Average DC-Voltage of both Inverters";
CM_ SG_ 2355286106 Maximum_torque_available "Value of both inverters for traction";
CM_ SG_ 2355286106 Minimum_torque_available "Value of both inverters for recuperation";
CM_ SG_ 2355351642 Temperature_EMotor_Axle1_1 "Temperature E-Motor 1";
CM_ SG_ 2355351642 Temperature_Inverter_Axle1_1 "Temperature Inverter 1";
CM_ SG_ 2355351642 Temperature_EMotor_Axle1_2 "Temperature E-Motor 2";
CM_ SG_ 2355351642 Temperature_Inverter_Axle1_2 "Temperature Inverter 2";
CM_ SG_ 2355417178 CurrentDcLink_Inverter_1 "DC current of Inverter 1";
CM_ SG_ 2355417178 MotorSpeed_EMotor_1 "Motor speed of E-motor 1";
CM_ SG_ 2355417178 Torque_EMotor_1 "Actual torque of E-motor 1";
CM_ SG_ 2355417178 DCL_Voltage_Inverter_1 "DCL Voltage of  Inverter 1";
CM_ SG_ 2355482714 CurrentDcLink_Inverter_338_2 "DC current of Inverter 338 2";
CM_ SG_ 2355482714 MotorSpeed_EMotor_338_2 "Motor speed of E-motor 338 2";
CM_ SG_ 2355482714 Torque_EMotor_338_2 "Actual torque of E-motor 338 2";
CM_ SG_ 2355482714 DCL_Voltage_Inverter_338_2 "DCL Voltage of  Inverter 338 2";
CM_ SG_ 2355548250 ECU_Cl15_State "Current Status of CL15 input of the ECU";
CM_ SG_ 2355548250 EV_Driveline_Shutdown_Indication "Shutdown of the EV Driveline is started.";
CM_ SG_ 2356007002 Derating_Flag "Derating Information,shows currently active derating flag";
CM_ SG_ 2355220484 Actual_Driving_direction_AVE_System2 "Driving direction of the Vehicle (for using in a display, ..)";
CM_ SG_ 2355220484 Actual_Drive_mode2 "Working mode of AVE130-System";
CM_ SG_ 2355220484 Wheel_Slippage_detection2 "Wheel slippage is detected on the Wheel (compare to Front Axle Speed), and specific torque reduction is active";
CM_ SG_ 2355220484 Average_EMotor_speed2 "E-Motor-Speed (unsigned)Average E-Motor-Speed of both E-Motors";
CM_ SG_ 2355220484 Actual_torque_AX_System2 "E-Motor-Torque (unsigned)Average E-Motor-Torque of both E-Motors";
CM_ SG_ 2355220484 AX2_System_Ready2 "Ready Status of the System";
CM_ SG_ 2355220484 Cooling_Afterrun_Request2 "KL30 Power is still requested for keeping Cooling and Oil Pump running, after KL15 off";
CM_ SG_ 2355220484 EMotor_Overspeed2 "Displays that the Emotor Speed is in critical speed range and the Driver should brake the vehicle to reduce the maximum allowed driveline speed";
CM_ SG_ 2355220484 EVECU1_MSG_Counter2 "optional available";
CM_ SG_ 2355220484 EVEC1_MSG_CRC2 "optional available";
CM_ SG_ 2355286020 DC_Current_Edrive_System2 "Sum DC_Current of both E-Motors";
CM_ SG_ 2355286020 DC_Voltage_Edrive_System2 "Average DC-Voltage of both Inverters";
CM_ SG_ 2355286020 Maximum_torque_available2 "Value of both inverters for traction";
CM_ SG_ 2355286020 Minimum_torque_available2 "Value of both inverters for recuperation";
CM_ SG_ 2355351556 Temperature_EMotor_Axle2_1 "Temperature E-Motor 1";
CM_ SG_ 2355351556 Temperature_Inverter_Axle2_1 "Temperature Inverter 1";
CM_ SG_ 2355351556 Temperature_EMotor_Axle2_2 "Temperature E-Motor 2";
CM_ SG_ 2355351556 Temperature_Inverter_Axle2_2 "Temperature Inverter 2";
CM_ SG_ 2355417092 CurrentDcLink_Inverter_2 "DC current of Inverter 2";
CM_ SG_ 2355417092 MotorSpeed_EMotor_2 "Motor speed of E-motor 2";
CM_ SG_ 2355417092 Torque_EMotor_2 "Actual torque of E-motor 2";
CM_ SG_ 2355417092 DCL_Voltage_Inverter_2 "DCL Voltage of  Inverter 2";
CM_ SG_ 2355548164 ECU_Cl15_State2 "Current Status of CL15 input of the ECU";
CM_ SG_ 2355548164 EV_Driveline_Shutdown_Indication2 "Shutdown of the EV Driveline is started.";
CM_ SG_ 2356006916 Derating_Flag_Axle2 "Derating Information,shows currently active derating flag";
CM_ SG_ 2355613786 Trax1_STRATEGY_FAULT_LEVEL_ "MTCU系统故障等级(Axle 1)";
CM_ SG_ 2355613786 Trax1_HI_INTERLOCK_FAULT "高低压互锁故障(Axle 1)";
CM_ SG_ 2355613786 Inverter_1_OVERTEMP_MTCU6 "IGBT过温故障3级_Axle 1（最高等级，温度阈值最高的那一级）";
CM_ SG_ 2355613786 EMotor_1_OVERTEMP_MTCU6 "驱动电机过温故障3级_Axle 1（最高等级，温度阈值最高的那一级）";
CM_ SG_ 2355613786 Inverter_2_OVERTEMP_MTCU6 "IGBT2过温故障3级_Axle 1（最高等级，温度阈值最高的那一级）";
CM_ SG_ 2355613786 EMotor_2_OVERTEMP_MTCU6 "驱动电机2过温故障3级_Axle 1（最高等级，温度阈值最高的那一级）";
CM_ SG_ 2557005914 MCU1_NRF_PHASE_HW_OVERCUR "相电流硬件检测过流故障";
CM_ SG_ 2557005914 MCU1_RF_UNBANLANCEDCUR "三相电流不平衡故障";
CM_ SG_ 2557005914 MCU1_NRF_CUR_SENSORZERO_FAULT_U "U相电流传感器零位故障";
CM_ SG_ 2557005914 MCU1_NRF_CUR_SENSORZERO_FAULT_V "V相电流传感器零位故障";
CM_ SG_ 2557005914 MCU1_NRF_CUR_SENSORZERO_FAULT_W "W相电流传感器零位故障";
CM_ SG_ 2557005914 MCU1_NRF_PHASE_OVERCUR_U "IGBT驱动电路过流故障(U相)_3级/（华创）IGBT相电流过流故障";
CM_ SG_ 2557005914 MCU1_NRF_PHASE_OVERCUR_V "IGBT驱动电路过流故障(V相)_3级";
CM_ SG_ 2557005914 MCU1_NRF_PHASE_OVERCUR_W "IGBT驱动电路过流故障(W相)_3级";
CM_ SG_ 2557005914 MCU1_RF_PHASE_OVERCUR_U "IGBT驱动电路过流故障(U相)_2级";
CM_ SG_ 2557005914 MCU1_RF_PHASE_OVERCUR_V "IGBT驱动电路过流故障(V相)_2级";
CM_ SG_ 2557005914 MCU1_RF_PHASE_OVERCUR_W "IGBT驱动电路过流故障(W相)_2级";
CM_ SG_ 2557005914 MCU1_NRF_DC_SENSORZERO_FAULT "母线电流传感器零位故障";
CM_ SG_ 2557005914 MCU1_NRF_DC_OVERCUR "MCU母线过流故障";
CM_ SG_ 2557005914 MCU1_NRF_DCFEED_INTERRUPT "MCU馈电高压断开故障";
CM_ SG_ 2557005914 MCU1_NRF_DC_HW_OVERVOL "MCU母线过压故障（电压采样故障）";
CM_ SG_ 2557005914 MCU1_NRF_DC_SW_OVERVOL "MCU母线过压故障_3级";
CM_ SG_ 2557005914 MCU1_RF_DC_OVERVOL "MCU母线过压故障_2级";
CM_ SG_ 2557005914 MCU1_LIF_DC_OVERVOL "MCU母线过压故障_1级";
CM_ SG_ 2557005914 MCU1_NRF_DC_UNDERVOL "MCU母线欠压故障_3级";
CM_ SG_ 2557005914 MCU1_RF_DC_UNDERVOL "MCU母线欠压故障_2级";
CM_ SG_ 2557005914 MCU1_LIF_DC_UNDERVO "MCU母线欠压故障_1级";
CM_ SG_ 2557005914 MCU1_IGBT_TEMPSENSOR_FAULT "IGBT温度传感器短路或断路故障";
CM_ SG_ 2557005914 MCU1_RF_INVTEMP_OVERTEMP "IGBT过温故障_2级";
CM_ SG_ 2557005914 MCU1_TORQUE_LOSTCONTROL "扭矩失控故障";
CM_ SG_ 2557005914 MCU1_MOTOR_TEMSENSOR_FAULT "电机温度传感器短路或断路故障";
CM_ SG_ 2557005914 MCU1_RF_MOTOR_OVERTEMP "驱动电机过温故障_2级";
CM_ SG_ 2557005914 MCU1_NRF_RDC_FAULT "MCU旋变解析故障";
CM_ SG_ 2557005914 MCU1_NRF_F_OVERSPEED "正向超速故障_3级";
CM_ SG_ 2557005914 MCU1_RF_F_OVERSPEED "正向超速故障_2级";
CM_ SG_ 2557005914 MCU1_LIF_R_OVERSPEED "反向超速故障";
CM_ SG_ 2557005914 MCU1_NRF_IGBT_HWTEST_FAULT "IGBT硬件检测故障";
CM_ SG_ 2557005914 MCU1_NRF_IGBT_HWLV_VOL_FAULT "IGBT硬件低压检测故障";
CM_ SG_ 2557005914 MCU1_NRF_5V_SUPPLY_FAULT "MCU输出5V电压故障";
CM_ SG_ 2557005914 MCU1_LIF_MOTOR_OVERTEMP "驱动电机过温故障_1级";
CM_ SG_ 2557005914 MCU1_NRF_LV_VOL_SUPPLY "MCU低压供电电源故障";
CM_ SG_ 2557005914 MCU1_LIF_INVTEMP_OVERTEMP "IGBT过温故障_1级";
CM_ SG_ 2557005914 MCU1_NRF_CAN_BUSOFF "MCU_BUSOFF故障_3级";
CM_ SG_ 2557005914 MCU1_RF_CAN_BUSOFF "MCU_BUSOFF故障_2级";
CM_ SG_ 2557005914 MCU1_RF_CAN_INTERNAL_FAULT "MCU程序超时故障";
CM_ SG_ 2557005914 MCU1_VCU_COM_LOST_ "VCU节点丢失";
CM_ SG_ 2557005914 MCU1_EEPRROM_FAULT_ "MCU_EEPROM故障";
CM_ SG_ 2557005914 MCU1_LOCKED_ROTOR_FAULT "堵转故障";
CM_ SG_ 2557005914 MCU1_DISCHARGE_FAULT "MCU主动放电失败故障";
CM_ SG_ 2557005914 MCU1_SOFTWARE_INTERRUPT "MCU芯片软件假中断故障";
CM_ SG_ 2557005914 MCU1_POST_FAULT "MCU上电自检故障";
CM_ SG_ 2557005914 MCU1_MOTOR_SELFLEARNING_FAULT "电机自学习故障";
CM_ SG_ 2557005914 MCU1_DATA_OVERFLOW_FAULT "数据溢出故障";
CM_ SG_ 2557005914 MCU1_MCU_OVERLOAD_FAULT "变频器过载报警";
CM_ SG_ 2557005914 MCU1_MOTOR_OVERLOAD_FAULT "电机过载故障";
CM_ SG_ 2557005914 MCU1_LIF_F_OVERSPEED "正向超速故障_1级(标定用）";
CM_ SG_ 2557005914 MCU1_TjIGBT_OVER_TEMP "结温限扭故障_2级";
CM_ SG_ 2557005914 MCU1_FS_Mw_faultiac_L3 "交流安全故障";
CM_ SG_ 2557005914 MCU1_FS_Mw_faultUdc_L3 "直流电压安全故障";
CM_ SG_ 2557005914 MCU1_FS_Mw_faultspeedcal_L3 "转速安全故障";
CM_ SG_ 2557005914 MCU1_FS_Mw_faulttorcomp_L3 "转矩比较安全故障";
CM_ SG_ 2557005914 MCU1_FS_Mw_faultpwmpowerup_L3 "上桥电源安全故障";
CM_ SG_ 2557005914 MCU1_FS_Mw_faultpwmpowerdown_L3 "下桥电源安全故障";
CM_ SG_ 2557005914 MCU1_FS_Mw_faultpwm_L3 "PWM安全故障";
CM_ SG_ 2557005914 MCU1_FS_Mw_faultacdischarge_L3 "主动放电安全故障";
CM_ SG_ 2557005914 MCU1_FS_Mw_faultpowermanager_L3 "电源管理安全故障";
CM_ SG_ 2557071450 MCU1_516_CURSENSOR_SHORT_FAULT__A "A相电流传感器短路故障";
CM_ SG_ 2557071450 MCU1_516_CURSENSOR_SHORT_FAULT__B "B相电流传感器短路故障";
CM_ SG_ 2557071450 MCU1_516_CURSENSOR_SHORT_FAULT__C "C相电流传感器短路故障";
CM_ SG_ 2557071450 MCU1_516_CURSENSOR_OPEN_FAULT__A "A相电流传感器断路故障";
CM_ SG_ 2557071450 MCU1_516_CURSENSOR_OPEN_FAULT__B "B相电流传感器断路故障";
CM_ SG_ 2557071450 MCU1_516_CURSENSOR_OPEN_FAULT__C "C相电流传感器断路故障";
CM_ SG_ 2557071450 MCU1_516_NRF_ANGLE_FAULT "旋变角度故障";
CM_ SG_ 2557071450 MCU1_516_RF_POWER_FAULT "功率不合理故障";
CM_ SG_ 2557071450 MCU1_516_NRF_PHASE_LOST_FAULT "缺相故障";
CM_ SG_ 2557071450 MCU1_516_NRF_HEATSINK_FAULT "冷却水严重故障_3级（预留）";
CM_ SG_ 2557071450 MCU1_516_RF_HEATSINK_FAULT "冷却水故障_2级（预留）";
CM_ SG_ 2557071450 MCU1_516_LIF_HEATSINK_FAULT "冷却水报警故障_1级（预留）";
CM_ SG_ 2557071450 MCU1_NRF_IGBT_B_HWTEST_FAULT "B相IGBT故障";
CM_ SG_ 2557071450 MCU1_NRF_IGBT_C_HWTEST_FAULT "C相IGBT故障";
CM_ SG_ 2557071450 MCU1_NRF_PHASE_B_HW_OVERCUR "B相电流硬件过流故障";
CM_ SG_ 2557071450 MCU1_NRF_PHASE_C_HW_OVERCUR "C相电流硬件过流故障";
CM_ SG_ 2557071450 MCU1_NRF_PHASE_OVERCUR "相电流严重过流故障_3级";
CM_ SG_ 2557071450 MCU1_RF_PHASE_OVERCUR "相电流过流故障_2级";
CM_ SG_ 2557071450 MCU1_LIF_PHASE_OVERCUR "相电流过流报警故障_1级";
CM_ SG_ 2557071450 MCU1_LIF_PHASE_OVERCUR_U "A相电流过流报警故障_1级";
CM_ SG_ 2557071450 MCU1_LIF_PHASE_OVERCUR_V "B相电流过流报警故障_1级";
CM_ SG_ 2557071450 MCU1_LIF_PHASE_OVERCUR_W "C相电流过流报警故障_1级";
CM_ SG_ 2557071450 MCU1_MCU_OVERLOAD_FAULT_A "A相电流过载故障_2级";
CM_ SG_ 2557071450 MCU1_MCU_OVERLOAD_FAULT_B "B相电流过载故障_2级";
CM_ SG_ 2557071450 MCU1_MCU_OVERLOAD_FAULT_C "C相电流过载故障_2级";
CM_ SG_ 2557071450 MCU1_IGBT_TEMPSENSOR_SHORT_FAULT_B "B相IGBT温度传感器短路故障";
CM_ SG_ 2557071450 MCU1_IGBT_TEMPSENSOR_SHORT_FAULT_C "C相IGBT温度传感器短路故障";
CM_ SG_ 2557071450 MCU1_IGBT_TEMPSENSOR_OPEN_FAULT_A "A相IGBT温度传感器断路故障";
CM_ SG_ 2557071450 MCU1_IGBT_TEMPSENSOR_OPEN_FAULT_B "B相IGBT温度传感器断路故障";
CM_ SG_ 2557071450 MCU1_IGBT_TEMPSENSOR_OPEN_FAULT_C "C相IGBT温度传感器断路故障";
CM_ SG_ 2557071450 MCU1_NRF_INVTEMP_OVERTEMP_A "IGBT A相严重过温故障_3级";
CM_ SG_ 2557071450 MCU1_NRF_INVTEMP_OVERTEMP_B "IGBT B相严重过温故障_3级";
CM_ SG_ 2557071450 MCU1_NRF_INVTEMP_OVERTEMP_C "IGBT C相严重过温故障_3级";
CM_ SG_ 2557071450 MCU1_RF_INVTEMP_OVERTEMP_A "IGBT A相过温故障_2级";
CM_ SG_ 2557071450 MCU1_RF_INVTEMP_OVERTEMP_B "IGBT B相过温故障_2级";
CM_ SG_ 2557071450 MCU1_RF_INVTEMP_OVERTEMP_C "IGBT C相过温故障_2级";
CM_ SG_ 2557071450 MCU1_LIF_INVTEMP_OVERTEMP_A "IGBT A相过温报警故障_1级";
CM_ SG_ 2557071450 MCU1_LIF_INVTEMP_OVERTEMP_B "IGBT B相过温报警故障_1级";
CM_ SG_ 2557071450 MCU1_LIF_INVTEMP_OVERTEMP_C "IGBT C相过温报警故障_1级";
CM_ SG_ 2557071450 MCU1_MOTOR_TEMSENSOR_1_SHORT_FAULT "电机温度传感器1短路故障";
CM_ SG_ 2557071450 MCU1_MOTOR_TEMSENSOR_1_OPEN_FAULT "电机温度传感器1断路故障";
CM_ SG_ 2557071450 MCU1_MOTOR_TEMSENSOR_2_OPEN_FAULT "电机温度传感器2断路故障";
CM_ SG_ 2557071450 MCU1_RF_R_OVERSPEED "反向转速超速状态报警故障_2级";
CM_ SG_ 2557071450 MCU1_NRF_LV_OVERVOL_SUPPLY "24V低压供电电源过压故障";
CM_ SG_ 2557071450 MCU1_NRF_LV_BKP_OVERVOL_SUPPLY "备用24V低压供电电源过压故障";
CM_ SG_ 2557071450 MCU1_NRF_LV_BKP_UNDERVOL_SUPPLY "备用24V低压供电电源欠压故障";
CM_ SG_ 2557071450 MCU1_NRF_DC_HW_OVERVOL_2 "母线电压硬件严重过压故障（硬件）";
CM_ SG_ 2557071450 MCU1_NRF_DC_HW_OVERVOL_1 "母线电压硬件过压故障（硬件）";
CM_ SG_ 2557071450 MCU1_NRF_DC_HW_HVIL "控制器高压互锁故障（硬件）";
CM_ SG_ 2557071450 MCU1_NRF_5V_DCCUR_SUPPLY_OVERVOL_FAULT "母线电流传感器5V电源过压故障";
CM_ SG_ 2557071450 MCU1_NRF_5V_DCCUR_SUPPLY_UNDERVOL_FAULT "母线电流传感器5V电源欠压故障";
CM_ SG_ 2557071450 MCU1_NRF_5V_CUR_SUPPLY_OVERVOL_FAULT "三相电流传感器5V电源过压故障";
CM_ SG_ 2557071450 MCU1_NRF_5V_CUR_SUPPLY_UNDERVOL_FAULT "三相电流传感器5V电源欠压故障";
CM_ SG_ 2557071450 MCU1_NRF_5V_DRV_SUPPLY_OVERVOL_FAULT "驱动板5V电源过压故障";
CM_ SG_ 2557071450 MCU1_NRF_PCBTEMP_OVERTEMP "PCB严重过温故障";
CM_ SG_ 2557071450 MCU1_ACCLR_FAULT "加速度不合理故障";
CM_ SG_ 2557136986 TCU_Power_Over_1st "电源电压过高";
CM_ SG_ 2557136986 TCU_Power_Down_1st "电源电压过低";
CM_ SG_ 2557136986 TCU_CPUNvm_Fault_1st "CPUNvm故障";
CM_ SG_ 2557136986 TCU_CPURam_Fault_1st "CPURam故障";
CM_ SG_ 2557136986 TCU_CPURom_Fault_1st "CPURom故障";
CM_ SG_ 2557136986 TCU_Reset_Fault_1st "CPU复位故障";
CM_ SG_ 2557136986 TCU_System_Fault_1st "CPU系统故障";
CM_ SG_ 2557136986 TCU_HSD2AndPowerShort_1st "HSD2与电源短路";
CM_ SG_ 2557136986 TCU_HighPinShort_1st "高端pin脚相互短路";
CM_ SG_ 2557136986 TCU_CAN1Disconnect_1st "CAN1掉线";
CM_ SG_ 2557136986 TCU_CAN2Disconnect_1st "CAN2掉线";
CM_ SG_ 2557136986 TCU_HSD1AndPowerShort_1st "HSD1与电源短路";
CM_ SG_ 2557136986 TCU_AccPdlLoss_1st "油门信号丢失";
CM_ SG_ 2557136986 TCU_AccPdlMessgLengthErr_1st "油门信号报文长度错误";
CM_ SG_ 2557136986 TCU_AccPdlCheckSumCheckErr_1st "油门信号CheckSum校验错误";
CM_ SG_ 2557136986 TCU_AccPdlRollingCounterErr_1st "油门信号RollingCounter错误";
CM_ SG_ 2557136986 TCU_AccPdlInvalidEnab_1st "油门无效标志";
CM_ SG_ 2557136986 TCU_AccPdlEqualInvalidVal_1st "油门等于无效值";
CM_ SG_ 2557136986 TCU_TemSnsrOpen_1st "温度传感器断路";
CM_ SG_ 2557136986 TCU_TemSnsrShorttoPower_1st "温度传感器对电源短路";
CM_ SG_ 2557136986 TCU_TemSnsrShorttoGround_1st "温度传感器对地短路";
CM_ SG_ 2557136986 TCU_OutSftSpdSnsrOpen_1st "输出轴转速传感器开路";
CM_ SG_ 2557136986 TCU_OutSftSpdShorttoPower_1st "输出轴转速对电源短路";
CM_ SG_ 2557136986 TCU_OutSftSpdShorttoGround_1st "输出轴转速对地短路";
CM_ SG_ 2557136986 TCU_SlctGValStPCSG2_Open_1st "选挡电磁阀G2断路";
CM_ SG_ 2557136986 TCU_SlctGValStPCSG2_ShorttoPower_1st "选挡电磁阀G2对电源短路";
CM_ SG_ 2557136986 TCU_SlctGValStPCSG2_ShorttoGround_1st "选挡电磁阀G2对地短路";
CM_ SG_ 2557136986 TCU_SlctGValStPCSG2_OverLoad_1st "选挡电磁阀G2过载";
CM_ SG_ 2557136986 TCU_SlctGValStPCSG2_UnderLoad_1st "选挡电磁阀G2欠载";
CM_ SG_ 2557136986 TCU_SlctGValStPCSG4_Open_1st "选挡电磁阀G4断路";
CM_ SG_ 2557136986 TCU_SlctGValStPCSG4_ShorttoPower_1st "选挡电磁阀G4对电源短路";
CM_ SG_ 2557136986 TCU_SlctGValStPCSG4_ShorttoGround_1st "选挡电磁阀G4对地短路";
CM_ SG_ 2557136986 TCU_SlctGValStPCSG4_OverLoad_1st "选挡电磁阀G4过载";
CM_ SG_ 2557136986 TCU_SlctGValStPCSG4_UnderLoad_1st "选挡电磁阀G4欠载";
CM_ SG_ 2557136986 TCU_SlctGValStPCSS3_Open_1st "换挡电磁阀S3断路";
CM_ SG_ 2557136986 TCU_SlctGValStPCSS3_ShorttoPower_1st "换挡电磁阀S3对电源短路";
CM_ SG_ 2557136986 TCU_SlctGValStPCSS3_ShorttoGround_1st "换挡电磁阀S3对地短路";
CM_ SG_ 2557136986 TCU_SlctGValStPCSS3_OverLoad_1st "换挡电磁阀S3过载";
CM_ SG_ 2557136986 TCU_SlctGValStPCSS3_UnderLoad_1st "换挡电磁阀S3欠载";
CM_ SG_ 2557136986 TCU_SlctGValStPCSS4_Open_1st "换挡电磁阀S4断路";
CM_ SG_ 2557136986 TCU_SlctGValStPCSS4_ShorttoPower_1st "换挡电磁阀S4对电源短路";
CM_ SG_ 2557136986 TCU_SlctGValStPCSS4_ShorttoGround_1st "换挡电磁阀S4对地短路";
CM_ SG_ 2557136986 TCU_SlctGValStPCSS4_OverLoad_1st "换挡电磁阀S4过载";
CM_ SG_ 2557136986 TCU_SlctGValStPCSS4_UnderLoad_1st "换挡电磁阀S4欠载";
CM_ SG_ 2557136986 TCU_9VElectricity_OverHigh_1st "9V供电过高";
CM_ SG_ 2557136986 TCU_9VElectricity_OverLow_1st "9V供电过低";
CM_ SG_ 2557136986 TCU_9VElectricityAndPow_Short_1st "9V供电与电源短路";
CM_ SG_ 2557136986 TCU_9VElectricityAndGnd_Short_1st "9V供电与地短路";
CM_ SG_ 2557136986 TCU_HSD1_Broken_1st "HSD1开路";
CM_ SG_ 2557136986 TCU_HSD1AndGnd_Broken_1st "HSD1与地短路";
CM_ SG_ 2557136986 TCU_HSD2_Broken_1st "HSD2开路";
CM_ SG_ 2557136986 TCU_HSD2AndGnd_Broken_1st "HSD2与地短路";
CM_ SG_ 2557136986 TCU_CAN1Node_Fault_1st "CAN1单节点故障";
CM_ SG_ 2557136986 TCU_CANBus_Silence_1st "CAN总线静默";
CM_ SG_ 2557136986 TCU_CAN2Node_Fault_1st "CAN2单节点故障";
CM_ SG_ 2557136986 TCU_PosSensorD_Broken_1st "位置传感器D开路";
CM_ SG_ 2557136986 TCU_PosSensorDAndPow_Broken_1st "位置传感器D对电源短路";
CM_ SG_ 2557136986 TCU_PosSensorDAndGnd_Broken_1st "位置传感器D对地短路";
CM_ SG_ 2557136986 TCU_PosSensorE_Broken_1st "位置传感器E开路";
CM_ SG_ 2557136986 TCU_PosSensorEAndPow_Broken_1st "位置传感器E对电源短路";
CM_ SG_ 2557136986 TCU_PosSensorEAndGnd_Broken_1st "位置传感器E对地短路";
CM_ SG_ 2557136986 TCU_PrssSenso_Broken_1st "压力传感器开路";
CM_ SG_ 2557136986 TCU_PrssSensoAndPow_Broken_1st "压力传感器对电源短路";
CM_ SG_ 2557136986 TCU_PrssSensoAndGnd_Broken_1st "压力传感器对地短路";
CM_ SG_ 2557202522 TCU_5VElectricity_OverHigh_1st "5V供电过高";
CM_ SG_ 2557202522 TCU_5VElectricity_OverLow_1st "5V供电过低";
CM_ SG_ 2557202522 TCU_5VElectricityAndPow_Short_1st "5V供电与电源短路";
CM_ SG_ 2557202522 TCU_5VElectricityAndGnd_Short_1st "5V供电与地短路";
CM_ SG_ 2557202522 TCU_VehSpd_Lost_1st "车速信号丢失";
CM_ SG_ 2557202522 TCU_VehSpdMessLength_Fault_1st "车速信号报文长度错误";
CM_ SG_ 2557202522 TCU_VehSpdChecSum_Fault_1st "车速信号CheckSum校验错误";
CM_ SG_ 2557202522 TCU_VehSpd_InvalidFg_1st "车速无效标志";
CM_ SG_ 2557202522 TCU_VehSpd_Invalid_1st "车速等于无效值";
CM_ SG_ 2557202522 TCU_OilTemp_level3_1st "油温高达到3级 135℃";
CM_ SG_ 2557202522 TCU_OilTemp_level4_1st "油温高达到4级 138℃";
CM_ SG_ 2557202522 TCU_ATFOilTemp_Low_1st "变速箱油温常低";
CM_ SG_ 2557202522 TCU_ATFOilTemp_Hop_1st "变速箱油温跳变";
CM_ SG_ 2557202522 TCU_OptSftSpd_High_1st "输出轴转速过高";
CM_ SG_ 2557202522 TCU_OptSftSpd_Hop_1st "输出轴转速跳变";
CM_ SG_ 2557202522 TCU_OptSftSpd_Zero_1st "输出轴无转速";
CM_ SG_ 2557202522 TCU_SftOG_Stuk_1st "退挡卡滞";
CM_ SG_ 2557202522 TCU_TqResponse_Failure_1st "扭矩响应失败";
CM_ SG_ 2557202522 TCU_SftIG_Stuk_1st "进挡卡滞";
CM_ SG_ 2557202522 TCU_RollingCounter_Fault_1st "车速信号RollingCounter错误";
CM_ SG_ 2557202522 TCU_PowOn_Failure_1st "上电失败";
CM_ SG_ 2557202522 TCU_PowOff_Failure_1st "下电失败";
CM_ SG_ 2557202522 TCU_OilTemp_level1_1st "油温高达到1级 110℃";
CM_ SG_ 2557202522 TCU_OilTemp_level2_1st "油温高达到2级 120℃";
CM_ SG_ 2566899802 Coolant_Request "Coolant temperature request from propulsion system to cooling system.";
CM_ SG_ 2566899802 Coolant_flow_request "Coolant feed flow request from propulsion system to cooling system.";
CM_ SG_ 2566840666 Retarder_Type "Type of retarder. Standard will be 0.";
CM_ SG_ 2566840666 Retarder_Location "Will be send 0; recuperation torque is depending on Engine rpm";
CM_ SG_ 2566840666 Retarder_Speed_at_Idle_point1 "E-Motor speed of point 1 of the E-Motor recuperation torque map. Will be send as fixed value or actual Speed (depending on requierement)";
CM_ SG_ 2566840666 RC_Percent_Torque_at_Idle_point1 "The recuperation torque limit that indicates the available E-Motor recuperation torque which can be provided by the E-Motor at point 1 of the E-Motor map";
CM_ SG_ 2566840666 Maximum_Retarder_Speed_point2 "E-Motor speed of point 2 of the E-Motor recuperation torque map";
CM_ SG_ 2566840666 RC_Percent_Torque_at_maximum_Speed_point2 "The recuperation torque limit that indicates the available E-Motor recuperation torque which can be provided by the E-Motor at point 2 of the E-Motor map";
CM_ SG_ 2566840666 Retarder_Speed_at_point3 "E-Motor speed of point 3 of the E-Motor recuperation torque map";
CM_ SG_ 2566840666 RC_Percent_Torque_at_point3 "The recuperation torque limit that indicates the available E-Motor recuperation torque which can be provided by the E-Motor at point 3 of the E-Motor map";
CM_ SG_ 2566840666 Retarder_Speed_at_point4 "E-Motor speed of point 4 of the E-Motor recuperation torque map";
CM_ SG_ 2566840666 RC_Percent_Torque_at_point4 "The recuperation torque limit that indicates the available E-Motor recuperation torque which can be provided by the E-Motor at point 4 of the E-Motor map";
CM_ SG_ 2566840666 Retarder_Speed_at_peak_Torque_point5 "E-Motor speed of point 5 of the E-Motor recuperation torque map";
CM_ SG_ 2566840666 Reference_Retarder_Torque "100% reference value for all defined indicated E-Motor recuperation recuperation torque parameters";
CM_ SG_ 2566840666 RC_Percent_Torque_at_point5 "The recuperation torque limit that indicates the available E-Motor recuperation torque which can be provided by the E-Motor at point 5 of the E-Motor map";
CM_ SG_ 2355613700 Trax2_STRATEGY_FAULT_LEVEL_ "MTCU系统故障等级(Axle 2)";
CM_ SG_ 2355613700 Trax2_HI_INTERLOCK_FAULT "高低压互锁故障(Axle 2)";
CM_ SG_ 2355613700 Inverter_2_OVERTEMP_MTCU6_Axle2_1 "IGBT过温故障3级_Axle 2（最高等级，温度阈值最高的那一级）";
CM_ SG_ 2355613700 EMotor_2_OVERTEMP_MTCU6_Axle2_1 "驱动电机过温故障3级_Axle 2（最高等级，温度阈值最高的那一级）";
CM_ SG_ 2355613700 Inverter_2_OVERTEMP_MTCU6_Axle2 "IGBT2过温故障3级_Axle 2（最高等级，温度阈值最高的那一级）";
CM_ SG_ 2355613700 EMotor_2_OVERTEMP_MTCU6_Axle2 "驱动电机2过温故障3级_Axle 2（最高等级，温度阈值最高的那一级）";
CM_ SG_ 2557005828 MCU2_NRF_PHASE_HW_OVERCUR "相电流硬件检测过流故障";
CM_ SG_ 2557005828 MCU2_RF_UNBANLANCEDCUR "三相电流不平衡故障";
CM_ SG_ 2557005828 MCU2_NRF_CUR_SENSORZERO_FAULT_U "U相电流传感器零位故障";
CM_ SG_ 2557005828 MCU2_NRF_CUR_SENSORZERO_FAULT_V "V相电流传感器零位故障";
CM_ SG_ 2557005828 MCU2_NRF_CUR_SENSORZERO_FAULT_W "W相电流传感器零位故障";
CM_ SG_ 2557005828 MCU2_NRF_PHASE_OVERCUR_U "IGBT驱动电路过流故障(U相)_3级/（华创）IGBT相电流过流故障";
CM_ SG_ 2557005828 MCU2_NRF_PHASE_OVERCUR_V "IGBT驱动电路过流故障(V相)_3级";
CM_ SG_ 2557005828 MCU2_NRF_PHASE_OVERCUR_W "IGBT驱动电路过流故障(W相)_3级";
CM_ SG_ 2557005828 MCU2_RF_PHASE_OVERCUR_U "IGBT驱动电路过流故障(U相)_2级";
CM_ SG_ 2557005828 MCU2_RF_PHASE_OVERCUR_V "IGBT驱动电路过流故障(V相)_2级";
CM_ SG_ 2557005828 MCU2_RF_PHASE_OVERCUR_W "IGBT驱动电路过流故障(W相)_2级";
CM_ SG_ 2557005828 MCU2_NRF_DC_SENSORZERO_FAULT "母线电流传感器零位故障";
CM_ SG_ 2557005828 MCU2_NRF_DC_OVERCUR "MCU母线过流故障";
CM_ SG_ 2557005828 MCU2_NRF_DCFEED_INTERRUPT "MCU馈电高压断开故障";
CM_ SG_ 2557005828 MCU2_NRF_DC_HW_OVERVOL "MCU母线过压故障（电压采样故障）";
CM_ SG_ 2557005828 MCU2_NRF_DC_SW_OVERVOL "MCU母线过压故障_3级";
CM_ SG_ 2557005828 MCU2_RF_DC_OVERVOL "MCU母线过压故障_2级";
CM_ SG_ 2557005828 MCU2_LIF_DC_OVERVOL "MCU母线过压故障_1级";
CM_ SG_ 2557005828 MCU2_NRF_DC_UNDERVOL "MCU母线欠压故障_3级";
CM_ SG_ 2557005828 MCU2_RF_DC_UNDERVOL "MCU母线欠压故障_2级";
CM_ SG_ 2557005828 MCU2_LIF_DC_UNDERVO "MCU母线欠压故障_1级";
CM_ SG_ 2557005828 MCU2_IGBT_TEMPSENSOR_FAULT "IGBT温度传感器短路或断路故障";
CM_ SG_ 2557005828 MCU2_RF_INVTEMP_OVERTEMP "IGBT过温故障_2级";
CM_ SG_ 2557005828 MCU2_TORQUE_LOSTCONTROL "扭矩失控故障";
CM_ SG_ 2557005828 MCU2_MOTOR_TEMSENSOR_FAULT "电机温度传感器短路或断路故障";
CM_ SG_ 2557005828 MCU2_RF_MOTOR_OVERTEMP "驱动电机过温故障_2级";
CM_ SG_ 2557005828 MCU2_NRF_RDC_FAULT "MCU旋变解析故障";
CM_ SG_ 2557005828 MCU2_NRF_F_OVERSPEED "正向超速故障_3级";
CM_ SG_ 2557005828 MCU2_RF_F_OVERSPEED "正向超速故障_2级";
CM_ SG_ 2557005828 MCU2_LIF_R_OVERSPEED "反向超速故障";
CM_ SG_ 2557005828 MCU2_NRF_IGBT_HWTEST_FAULT "IGBT硬件检测故障";
CM_ SG_ 2557005828 MCU2_NRF_IGBT_HWLV_VOL_FAULT "IGBT硬件低压检测故障";
CM_ SG_ 2557005828 MCU2_NRF_5V_SUPPLY_FAULT "MCU输出5V电压故障";
CM_ SG_ 2557005828 MCU2_LIF_MOTOR_OVERTEMP "驱动电机过温故障_1级";
CM_ SG_ 2557005828 MCU2_NRF_LV_VOL_SUPPLY "MCU低压供电电源故障";
CM_ SG_ 2557005828 MCU2_LIF_INVTEMP_OVERTEMP "IGBT过温故障_1级";
CM_ SG_ 2557005828 MCU2_NRF_CAN_BUSOFF "MCU_BUSOFF故障_3级";
CM_ SG_ 2557005828 MCU2_RF_CAN_BUSOFF "MCU_BUSOFF故障_2级";
CM_ SG_ 2557005828 MCU2_RF_CAN_INTERNAL_FAULT "MCU程序超时故障";
CM_ SG_ 2557005828 MCU2_VCU_COM_LOST_ "VCU节点丢失";
CM_ SG_ 2557005828 MCU2_EEPRROM_FAULT_ "MCU_EEPROM故障";
CM_ SG_ 2557005828 MCU2_LOCKED_ROTOR_FAULT "堵转故障";
CM_ SG_ 2557005828 MCU2_DISCHARGE_FAULT "MCU主动放电失败故障";
CM_ SG_ 2557005828 MCU2_SOFTWARE_INTERRUPT "MCU芯片软件假中断故障";
CM_ SG_ 2557005828 MCU2_POST_FAULT "MCU上电自检故障";
CM_ SG_ 2557005828 MCU2_MOTOR_SELFLEARNING_FAULT "电机自学习故障";
CM_ SG_ 2557005828 MCU2_DATA_OVERFLOW_FAULT "数据溢出故障";
CM_ SG_ 2557005828 MCU2_MCU_OVERLOAD_FAULT "变频器过载报警";
CM_ SG_ 2557005828 MCU2_MOTOR_OVERLOAD_FAULT "电机过载故障";
CM_ SG_ 2557005828 MCU2_LIF_F_OVERSPEED "正向超速故障_1级(标定用）";
CM_ SG_ 2557005828 MCU2_TjIGBT_OVER_TEMP "结温限扭故障_2级";
CM_ SG_ 2557005828 MCU2_FS_Mw_faultiac_L3 "交流安全故障";
CM_ SG_ 2557005828 MCU2_FS_Mw_faultUdc_L3 "直流电压安全故障";
CM_ SG_ 2557005828 MCU2_FS_Mw_faultspeedcal_L3 "转速安全故障";
CM_ SG_ 2557005828 MCU2_FS_Mw_faulttorcomp_L3 "转矩比较安全故障";
CM_ SG_ 2557005828 MCU2_FS_Mw_faultpwmpowerup_L3 "上桥电源安全故障";
CM_ SG_ 2557005828 MCU2_FS_Mw_faultpwmpowerdown_L3 "下桥电源安全故障";
CM_ SG_ 2557005828 MCU2_FS_Mw_faultpwm_L3 "PWM安全故障";
CM_ SG_ 2557005828 MCU2_FS_Mw_faultacdischarge_L3 "主动放电安全故障";
CM_ SG_ 2557005828 MCU2_FS_Mw_faultpowermanager_L3 "电源管理安全故障";
CM_ SG_ 2557071364 MCU2_516_CURSENSOR_SHORT_FAULT__A "A相电流传感器短路故障";
CM_ SG_ 2557071364 MCU2_516_CURSENSOR_SHORT_FAULT__B "B相电流传感器短路故障";
CM_ SG_ 2557071364 MCU2_516_CURSENSOR_SHORT_FAULT__C "C相电流传感器短路故障";
CM_ SG_ 2557071364 MCU2_516_CURSENSOR_OPEN_FAULT__A "A相电流传感器断路故障";
CM_ SG_ 2557071364 MCU2_516_CURSENSOR_OPEN_FAULT__B "B相电流传感器断路故障";
CM_ SG_ 2557071364 MCU2_516_CURSENSOR_OPEN_FAULT__C "C相电流传感器断路故障";
CM_ SG_ 2557071364 MCU2_516_NRF_ANGLE_FAULT "旋变角度故障";
CM_ SG_ 2557071364 MCU2_516_RF_POWER_FAULT "功率不合理故障";
CM_ SG_ 2557071364 MCU2_516_NRF_PHASE_LOST_FAULT "缺相故障";
CM_ SG_ 2557071364 MCU2_516_NRF_HEATSINK_FAULT "冷却水严重故障_3级（预留）";
CM_ SG_ 2557071364 MCU2_516_RF_HEATSINK_FAULT "冷却水故障_2级（预留）";
CM_ SG_ 2557071364 MCU2_516_LIF_HEATSINK_FAULT "冷却水报警故障_1级（预留）";
CM_ SG_ 2557071364 MCU2_NRF_IGBT_B_HWTEST_FAULT "B相IGBT故障";
CM_ SG_ 2557071364 MCU2_NRF_IGBT_C_HWTEST_FAULT "C相IGBT故障";
CM_ SG_ 2557071364 MCU2_NRF_PHASE_B_HW_OVERCUR "B相电流硬件过流故障";
CM_ SG_ 2557071364 MCU2_NRF_PHASE_C_HW_OVERCUR "C相电流硬件过流故障";
CM_ SG_ 2557071364 MCU2_NRF_PHASE_OVERCUR "相电流严重过流故障_3级";
CM_ SG_ 2557071364 MCU2_RF_PHASE_OVERCUR "相电流过流故障_2级";
CM_ SG_ 2557071364 MCU2_LIF_PHASE_OVERCUR "相电流过流报警故障_1级";
CM_ SG_ 2557071364 MCU2_LIF_PHASE_OVERCUR_U "A相电流过流报警故障_1级";
CM_ SG_ 2557071364 MCU2_LIF_PHASE_OVERCUR_V "B相电流过流报警故障_1级";
CM_ SG_ 2557071364 MCU2_LIF_PHASE_OVERCUR_W "C相电流过流报警故障_1级";
CM_ SG_ 2557071364 MCU2_MCU_OVERLOAD_FAULT_A "A相电流过载故障_2级";
CM_ SG_ 2557071364 MCU2_MCU_OVERLOAD_FAULT_B "B相电流过载故障_2级";
CM_ SG_ 2557071364 MCU2_MCU_OVERLOAD_FAULT_C "C相电流过载故障_2级";
CM_ SG_ 2557071364 MCU2_IGBT_TEMPSENSOR_SHORT_FAULT_B "B相IGBT温度传感器短路故障";
CM_ SG_ 2557071364 MCU2_IGBT_TEMPSENSOR_SHORT_FAULT_C "C相IGBT温度传感器短路故障";
CM_ SG_ 2557071364 MCU2_IGBT_TEMPSENSOR_OPEN_FAULT_A "A相IGBT温度传感器断路故障";
CM_ SG_ 2557071364 MCU2_IGBT_TEMPSENSOR_OPEN_FAULT_B "B相IGBT温度传感器断路故障";
CM_ SG_ 2557071364 MCU2_IGBT_TEMPSENSOR_OPEN_FAULT_C "C相IGBT温度传感器断路故障";
CM_ SG_ 2557071364 MCU2_NRF_INVTEMP_OVERTEMP_A "IGBT A相严重过温故障_3级";
CM_ SG_ 2557071364 MCU2_NRF_INVTEMP_OVERTEMP_B "IGBT B相严重过温故障_3级";
CM_ SG_ 2557071364 MCU2_NRF_INVTEMP_OVERTEMP_C "IGBT C相严重过温故障_3级";
CM_ SG_ 2557071364 MCU2_RF_INVTEMP_OVERTEMP_A "IGBT A相过温故障_2级";
CM_ SG_ 2557071364 MCU2_RF_INVTEMP_OVERTEMP_B "IGBT B相过温故障_2级";
CM_ SG_ 2557071364 MCU2_RF_INVTEMP_OVERTEMP_C "IGBT C相过温故障_2级";
CM_ SG_ 2557071364 MCU2_LIF_INVTEMP_OVERTEMP_A "IGBT A相过温报警故障_1级";
CM_ SG_ 2557071364 MCU2_LIF_INVTEMP_OVERTEMP_B "IGBT B相过温报警故障_1级";
CM_ SG_ 2557071364 MCU2_LIF_INVTEMP_OVERTEMP_C "IGBT C相过温报警故障_1级";
CM_ SG_ 2557071364 MCU2_MOTOR_TEMSENSOR_1_SHORT_FAULT "电机温度传感器1短路故障";
CM_ SG_ 2557071364 MCU2_MOTOR_TEMSENSOR_1_OPEN_FAULT "电机温度传感器1断路故障";
CM_ SG_ 2557071364 MCU2_MOTOR_TEMSENSOR_2_OPEN_FAULT "电机温度传感器2断路故障";
CM_ SG_ 2557071364 MCU2_RF_R_OVERSPEED "反向转速超速状态报警故障_2级";
CM_ SG_ 2557071364 MCU2_NRF_LV_OVERVOL_SUPPLY "24V低压供电电源过压故障";
CM_ SG_ 2557071364 MCU2_NRF_LV_BKP_OVERVOL_SUPPLY "备用24V低压供电电源过压故障";
CM_ SG_ 2557071364 MCU2_NRF_LV_BKP_UNDERVOL_SUPPLY "备用24V低压供电电源欠压故障";
CM_ SG_ 2557071364 MCU2_NRF_DC_HW_OVERVOL_2 "母线电压硬件严重过压故障（硬件）";
CM_ SG_ 2557071364 MCU2_NRF_DC_HW_OVERVOL_1 "母线电压硬件过压故障（硬件）";
CM_ SG_ 2557071364 MCU2_NRF_DC_HW_HVIL "控制器高压互锁故障（硬件）";
CM_ SG_ 2557071364 MCU2_NRF_5V_DCCUR_SUPPLY_OVERVOL_FAULT "母线电流传感器5V电源过压故障";
CM_ SG_ 2557071364 MCU2_NRF_5V_DCCUR_SUPPLY_UNDERVOL_FAULT "母线电流传感器5V电源欠压故障";
CM_ SG_ 2557071364 MCU2_NRF_5V_CUR_SUPPLY_OVERVOL_FAULT "三相电流传感器5V电源过压故障";
CM_ SG_ 2557071364 MCU2_NRF_5V_CUR_SUPPLY_UNDERVOL_FAULT "三相电流传感器5V电源欠压故障";
CM_ SG_ 2557071364 MCU2_NRF_5V_DRV_SUPPLY_OVERVOL_FAULT "驱动板5V电源过压故障";
CM_ SG_ 2557071364 MCU2_NRF_PCBTEMP_OVERTEMP "PCB严重过温故障";
CM_ SG_ 2557071364 MCU2_ACCLR_FAULT "加速度不合理故障";
CM_ SG_ 2557136900 TCU_Power_Over_2nd "电源电压过高";
CM_ SG_ 2557136900 TCU_Power_Down_2nd "电源电压过低";
CM_ SG_ 2557136900 TCU_CPUNvm_Fault_2nd "CPUNvm故障";
CM_ SG_ 2557136900 TCU_CPURam_Fault_2nd "CPURam故障";
CM_ SG_ 2557136900 TCU_CPURom_Fault_2nd "CPURom故障";
CM_ SG_ 2557136900 TCU_Reset_Fault_2nd "CPU复位故障";
CM_ SG_ 2557136900 TCU_System_Fault_2nd "CPU系统故障";
CM_ SG_ 2557136900 TCU_HSD2AndPowerShort_2nd "HSD2与电源短路";
CM_ SG_ 2557136900 TCU_HighPinShort_2nd "高端pin脚相互短路";
CM_ SG_ 2557136900 TCU_CAN1Disconnect_2nd "CAN1掉线";
CM_ SG_ 2557136900 TCU_CAN2Disconnect_2nd "CAN2掉线";
CM_ SG_ 2557136900 TCU_HSD1AndPowerShort_2nd "HSD1与电源短路";
CM_ SG_ 2557136900 TCU_AccPdlLoss_2nd "油门信号丢失";
CM_ SG_ 2557136900 TCU_AccPdlMessgLengthErr_2nd "油门信号报文长度错误";
CM_ SG_ 2557136900 TCU_AccPdlCheckSumCheckErr_2nd "油门信号CheckSum校验错误";
CM_ SG_ 2557136900 TCU_AccPdlRollingCounterErr_2nd "油门信号RollingCounter错误";
CM_ SG_ 2557136900 TCU_AccPdlInvalidEnab_2nd "油门无效标志";
CM_ SG_ 2557136900 TCU_AccPdlEqualInvalidVal_2nd "油门等于无效值";
CM_ SG_ 2557136900 TCU_TemSnsrOpen_2nd "温度传感器断路";
CM_ SG_ 2557136900 TCU_TemSnsrShorttoPower_2nd "温度传感器对电源短路";
CM_ SG_ 2557136900 TCU_TemSnsrShorttoGround_2nd "温度传感器对地短路";
CM_ SG_ 2557136900 TCU_OutSftSpdSnsrOpen_2nd "输出轴转速传感器开路";
CM_ SG_ 2557136900 TCU_OutSftSpdShorttoPower_2nd "输出轴转速对电源短路";
CM_ SG_ 2557136900 TCU_OutSftSpdShorttoGround_2nd "输出轴转速对地短路";
CM_ SG_ 2557136900 TCU_SlctGValStPCSG2_Open_2nd "选挡电磁阀G2断路";
CM_ SG_ 2557136900 TCU_SlctGValStPCSG2_ShorttoPower_2nd "选挡电磁阀G2对电源短路";
CM_ SG_ 2557136900 TCU_SlctGValStPCSG2_ShorttoGround_2nd "选挡电磁阀G2对地短路";
CM_ SG_ 2557136900 TCU_SlctGValStPCSG2_OverLoad_2nd "选挡电磁阀G2过载";
CM_ SG_ 2557136900 TCU_SlctGValStPCSG2_UnderLoad_2nd "选挡电磁阀G2欠载";
CM_ SG_ 2557136900 TCU_SlctGValStPCSG4_Open_2nd "选挡电磁阀G4断路";
CM_ SG_ 2557136900 TCU_SlctGValStPCSG4_ShorttoPower_2nd "选挡电磁阀G4对电源短路";
CM_ SG_ 2557136900 TCU_SlctGValStPCSG4_ShorttoGround_2nd "选挡电磁阀G4对地短路";
CM_ SG_ 2557136900 TCU_SlctGValStPCSG4_OverLoad_2nd "选挡电磁阀G4过载";
CM_ SG_ 2557136900 TCU_SlctGValStPCSG4_UnderLoad_2nd "选挡电磁阀G4欠载";
CM_ SG_ 2557136900 TCU_SlctGValStPCSS3_Open_2nd "换挡电磁阀S3断路";
CM_ SG_ 2557136900 TCU_SlctGValStPCSS3_ShorttoPower_2nd "换挡电磁阀S3对电源短路";
CM_ SG_ 2557136900 TCU_SlctGValStPCSS3_ShorttoGround_2nd "换挡电磁阀S3对地短路";
CM_ SG_ 2557136900 TCU_SlctGValStPCSS3_OverLoad_2nd "换挡电磁阀S3过载";
CM_ SG_ 2557136900 TCU_SlctGValStPCSS3_UnderLoad_2nd "换挡电磁阀S3欠载";
CM_ SG_ 2557136900 TCU_SlctGValStPCSS4_Open_2nd "换挡电磁阀S4断路";
CM_ SG_ 2557136900 TCU_SlctGValStPCSS4_ShorttoPower_2nd "换挡电磁阀S4对电源短路";
CM_ SG_ 2557136900 TCU_SlctGValStPCSS4_ShorttoGround_2nd "换挡电磁阀S4对地短路";
CM_ SG_ 2557136900 TCU_SlctGValStPCSS4_OverLoad_2nd "换挡电磁阀S4过载";
CM_ SG_ 2557136900 TCU_SlctGValStPCSS4_UnderLoad_2nd "换挡电磁阀S4欠载";
CM_ SG_ 2557136900 TCU_9VElectricity_OverHigh_2nd "9V供电过高";
CM_ SG_ 2557136900 TCU_9VElectricity_OverLow_2nd "9V供电过低";
CM_ SG_ 2557136900 TCU_9VElectricityAndPow_Short_2nd "9V供电与电源短路";
CM_ SG_ 2557136900 TCU_9VElectricityAndGnd_Short_2nd "9V供电与地短路";
CM_ SG_ 2557136900 TCU_HSD1_Broken_2nd "HSD1开路";
CM_ SG_ 2557136900 TCU_HSD1AndGnd_Broken_2nd "HSD1与地短路";
CM_ SG_ 2557136900 TCU_HSD2_Broken_2nd "HSD2开路";
CM_ SG_ 2557136900 TCU_HSD2AndGnd_Broken_2nd "HSD2与地短路";
CM_ SG_ 2557136900 TCU_CAN1Node_Fault_2nd "CAN1单节点故障";
CM_ SG_ 2557136900 TCU_CANBus_Silence_2nd "CAN总线静默";
CM_ SG_ 2557136900 TCU_CAN2Node_Fault_2nd "CAN2单节点故障";
CM_ SG_ 2557136900 TCU_PosSensorD_Broken_2nd "位置传感器D开路";
CM_ SG_ 2557136900 TCU_PosSensorDAndPow_Broken_2nd "位置传感器D对电源短路";
CM_ SG_ 2557136900 TCU_PosSensorDAndGnd_Broken_2nd "位置传感器D对地短路";
CM_ SG_ 2557136900 TCU_PosSensorE_Broken_2nd "位置传感器E开路";
CM_ SG_ 2557136900 TCU_PosSensorEAndPow_Broken_2nd "位置传感器E对电源短路";
CM_ SG_ 2557136900 TCU_PosSensorEAndGnd_Broken_2nd "位置传感器E对地短路";
CM_ SG_ 2557136900 TCU_PrssSenso_Broken_2nd "压力传感器开路";
CM_ SG_ 2557136900 TCU_PrssSensoAndPow_Broken_2nd "压力传感器对电源短路";
CM_ SG_ 2557136900 TCU_PrssSensoAndGnd_Broken_2nd "压力传感器对地短路";
CM_ SG_ 2557202436 TCU_5VElectricity_OverHigh_2nd "5V供电过高";
CM_ SG_ 2557202436 TCU_5VElectricity_OverLow_2nd "5V供电过低";
CM_ SG_ 2557202436 TCU_5VElectricityAndPow_Short_2nd "5V供电与电源短路";
CM_ SG_ 2557202436 TCU_5VElectricityAndGnd_Short_2nd "5V供电与地短路";
CM_ SG_ 2557202436 TCU_VehSpd_Lost_2nd "车速信号丢失";
CM_ SG_ 2557202436 TCU_VehSpdMessLength_Fault_2nd "车速信号报文长度错误";
CM_ SG_ 2557202436 TCU_VehSpdChecSum_Fault_2nd "车速信号CheckSum校验错误";
CM_ SG_ 2557202436 TCU_VehSpd_InvalidFg_2nd "车速无效标志";
CM_ SG_ 2557202436 TCU_VehSpd_Invalid_2nd "车速等于无效值";
CM_ SG_ 2557202436 TCU_OilTemp_level3_2nd "油温高达到3级 135℃";
CM_ SG_ 2557202436 TCU_OilTemp_level4_2nd "油温高达到4级 138℃";
CM_ SG_ 2557202436 TCU_ATFOilTemp_Low_2nd "变速箱油温常低";
CM_ SG_ 2557202436 TCU_ATFOilTemp_Hop_2nd "变速箱油温跳变";
CM_ SG_ 2557202436 TCU_OptSftSpd_High_2nd "输出轴转速过高";
CM_ SG_ 2557202436 TCU_OptSftSpd_Hop_2nd "输出轴转速跳变";
CM_ SG_ 2557202436 TCU_OptSftSpd_Zero_2nd "输出轴无转速";
CM_ SG_ 2557202436 TCU_SftOG_Stuk_2nd "退挡卡滞";
CM_ SG_ 2557202436 TCU_TqResponse_Failure_2nd "扭矩响应失败";
CM_ SG_ 2557202436 TCU_SftIG_Stuk_2nd "进挡卡滞";
CM_ SG_ 2557202436 TCU_RollingCounter_Fault_2nd "车速信号RollingCounter错误";
CM_ SG_ 2557202436 TCU_PowOn_Failure_2nd "上电失败";
CM_ SG_ 2557202436 TCU_PowOff_Failure_2nd "下电失败";
CM_ SG_ 2557202436 TCU_OilTemp_level1_2nd "油温高达到1级 110℃";
CM_ SG_ 2557202436 TCU_OilTemp_level2_2nd "油温高达到2级 120℃";
CM_ SG_ 2566899716 Coolant_Request_Axle2 "Coolant temperature request from propulsion system to cooling system.";
CM_ SG_ 2566899716 Coolant_flow_request_Axle2 "Coolant feed flow request from propulsion system to cooling system.";
CM_ SG_ 2566840580 Retarder_Type_Axle2 "Type of retarder. Standard will be 0.";
CM_ SG_ 2566840580 Retarder_Location_Axle2 "Will be send 0; recuperation torque is depending on Engine rpm";
CM_ SG_ 2566840580 Retarder_Speed_at_Idle_point1_Axle2 "E-Motor speed of point 1 of the E-Motor recuperation torque map. Will be send as fixed value or actual Speed (depending on requierement)";
CM_ SG_ 2566840580 RC_Percent_Torque_at_Idle_point1_Axle2 "The recuperation torque limit that indicates the available E-Motor recuperation torque which can be provided by the E-Motor at point 1 of the E-Motor map";
CM_ SG_ 2566840580 Maximum_Retarder_Speed_point2_Axle2 "E-Motor speed of point 2 of the E-Motor recuperation torque map";
CM_ SG_ 2566840580 RC_Percent_Torque_at_maximum_Speed_point2_Axle2 "The recuperation torque limit that indicates the available E-Motor recuperation torque which can be provided by the E-Motor at point 2 of the E-Motor map";
CM_ SG_ 2566840580 Retarder_Speed_at_point3_Axle2 "E-Motor speed of point 3 of the E-Motor recuperation torque map";
CM_ SG_ 2566840580 RC_Percent_Torque_at_point3_Axle2 "The recuperation torque limit that indicates the available E-Motor recuperation torque which can be provided by the E-Motor at point 3 of the E-Motor map";
CM_ SG_ 2566840580 Retarder_Speed_at_point4_Axle2 "E-Motor speed of point 4 of the E-Motor recuperation torque map";
CM_ SG_ 2566840580 RC_Percent_Torque_at_point4_Axle2 "The recuperation torque limit that indicates the available E-Motor recuperation torque which can be provided by the E-Motor at point 4 of the E-Motor map";
CM_ SG_ 2566840580 Retarder_Speed_at_peak_Torque_point5_Axle2 "E-Motor speed of point 5 of the E-Motor recuperation torque map";
CM_ SG_ 2566840580 Reference_Retarder_Torque_Axle2 "100% reference value for all defined indicated E-Motor recuperation recuperation torque parameters";
CM_ SG_ 2566840580 RC_Percent_Torque_at_point5_Axle2 "The recuperation torque limit that indicates the available E-Motor recuperation torque which can be provided by the E-Motor at point 5 of the E-Motor map";
CM_ SG_ 2566841178 EMotor_speed_at_idle_Point1 "E-Motor speed of point 1 of the E-Motor torque mapWill be send as fixed value or actual Speed (depending on requierement)";
CM_ SG_ 2566841178 EC_Percent_Torque_at_Idle_Point1 "The torque limit that indicates the available E-Motor torque which can be provided by the E-Motor at point 1 of the E-Motor map";
CM_ SG_ 2566841178 EMotor_Speed_at_Point2 "E-Motor speed of point 2 of the E-Motor torque map";
CM_ SG_ 2566841178 EC_Percent_Torque_at_Point2 "The torque limit that indicates the available E-Motor torque which can be provided by the E-Motor at point 2 of the E-Motor map";
CM_ SG_ 2566841178 EMotor_Speed_at_Point3 "E-Motor speed of point 3 of the E-Motor torque map";
CM_ SG_ 2566841178 EC_Percent_Torque_at_Point3 "The torque limit that indicates the available E-Motor torque which can be provided by the E-Motor at point 3 of the E-Motor map";
CM_ SG_ 2566841178 EMotor_Speed_at_Point4 "E-Motor speed of point 4 of the E-Motor torque map";
CM_ SG_ 2566841178 EC_Percent_Torque_at_Point4 "The torque limit that indicates the available E-Motor torque which can be provided by the E-Motor at point 4 of the E-Motor map";
CM_ SG_ 2566841178 EMotor_Speed_at_Point5 "E-Motor speed of point 5 of the E-Motor torque map";
CM_ SG_ 2566841178 EC_Percent_Torque_at_Point5 "The torque limit that indicates the available E-Motor torque which can be provided by the E-Motor at point 5 of the E-Motor map";
CM_ SG_ 2566841178 EMotor_reference_torque "100% reference value for all defined indicated E-Motor torque parameters";
CM_ SG_ 2566841092 EMotor_speed_at_idle_Point1_Axle2 "E-Motor speed of point 1 of the E-Motor torque mapWill be send as fixed value or actual Speed (depending on requierement)";
CM_ SG_ 2566841092 EC_Percent_Torque_at_Idle_Point1_Axle2 "The torque limit that indicates the available E-Motor torque which can be provided by the E-Motor at point 1 of the E-Motor map";
CM_ SG_ 2566841092 EMotor_Speed_at_Point2_Axle2 "E-Motor speed of point 2 of the E-Motor torque map";
CM_ SG_ 2566841092 EC_Percent_Torque_at_Point2_Axle2 "The torque limit that indicates the available E-Motor torque which can be provided by the E-Motor at point 2 of the E-Motor map";
CM_ SG_ 2566841092 EMotor_Speed_at_Point3_Axle2 "E-Motor speed of point 3 of the E-Motor torque map";
CM_ SG_ 2566841092 EC_Percent_Torque_at_Point3_Axle2 "The torque limit that indicates the available E-Motor torque which can be provided by the E-Motor at point 3 of the E-Motor map";
CM_ SG_ 2566841092 EMotor_Speed_at_Point4_Axle2 "E-Motor speed of point 4 of the E-Motor torque map";
CM_ SG_ 2566841092 EC_Percent_Torque_at_Point4_Axle2 "The torque limit that indicates the available E-Motor torque which can be provided by the E-Motor at point 4 of the E-Motor map";
CM_ SG_ 2566841092 EMotor_Speed_at_Point5_Axle2 "E-Motor speed of point 5 of the E-Motor torque map";
CM_ SG_ 2566841092 EC_Percent_Torque_at_Point5_Axle2 "The torque limit that indicates the available E-Motor torque which can be provided by the E-Motor at point 5 of the E-Motor map";
CM_ SG_ 2566841092 EMotor_reference_torque_Axle2 "100% reference value for all defined indicated E-Motor torque parameters";
CM_ SG_ 2364539994 EMotor_TrqRet_Mode "State signal which indicates which E-Motor torque mode is currently generating, limiting, or controlling the torque.";
CM_ SG_ 2364539994 Actual_EMotor_Percent_Torque_high_resolution "This parameter displays an additional torque in percent of the reference E-Motor torque.";
CM_ SG_ 2364539994 Drivers_Demand_EMotor_Percent_Torque "Driver's Demand E-Motor - Percent Torque";
CM_ SG_ 2364539994 E_Actual_EMotor_Percent_Torque "The calculated output torque of the E-Motor.";
CM_ SG_ 2364539994 EMotor_Speed "Actual E-Motor speed";
CM_ SG_ 2364539994 Source_Adress_of_Ctrl_Device "Based on J1939 (EEC1)";
CM_ SG_ 2364539738 Actual_Maximum_Available_Engine_Percent_Torque "This is the maximum amount of torque that the engine can immediately deliver as a percentage of the reference engine torque (SPN 544).  The Actual Maximum Available Engine - Percent Torque shall take into consideration all engine torque derates (e.g. air fuel ratio control (AFC), noise control, etc.) that could potentially be active in the system.  This parameter differentiates itself from the engine percent torque points 1 through 5 of the engine configuration map because it takes into account all dynamic internal inputs such as  AFC and that it is updated on a 50ms basis.";
CM_ SG_ 2566840154 Nominal_FrictionPercent_Torque "E-Motor /Drivettrain recuperation torque, wich is created by ZF Energy recuperation strategy. Always negative or 0.";
CM_ SG_ 2566840154 Engine_EMotor_Parasitic_Losses "Estimated losses of the Motor. Not comparable to the combustion engine; will always send with 0%";
CM_ SG_ 2565865562 EMotor_Torque_Mode "State signal which indicates which retarder torque mode is currently generating, limiting, or controlling the torque.";
CM_ SG_ 2565865562 Recuperation_Enable_Switch "Signal which indicates that the Driveline is principially ready to recuperate (send out always as acitve; signal instead of AUX-IO, recperation enable request)";
CM_ SG_ 2565865562 R_Actual_EMotor_Percent_Torque "Actual braking torque of the E-Motor as a percent of E-Motor configuration reference torque SPN 556";
CM_ SG_ 2565865562 Intended_EMotor_Percent_Torque "Braking torque of E-Motor that the E-Motor is currently trying to achieve";
CM_ SG_ 2565865562 Source_Adress_of_Crtl_Device "The source address of the device currently controlling the E-Motor";
CM_ SG_ 2565865562 Driver_Demand_EMotor_Percent_Torque "The Drivers demand E-Motor – percent torque is the maximum torque selected by the driver";
CM_ SG_ 2565865562 Actual_Maximum_Available_EMotor_Recuperation_Torque "This is the maximum amount of torque that the E-Motor can immediately deliver";
CM_ SG_ 2566856794 Emotor_Trq_Ret_Mode_EMRC1 "State signal which indicates which e-motor torque mode is currently generating, limiting or controlling the torque.";
CM_ SG_ 2566856794 Actual_Emotor_Percent_Torque_High_Resolution_EMRC1 "This parameter displays an additional torque in percent of the reference e-motor torque.";
CM_ SG_ 2566856794 Actual_Emotor_Percent_Torque_EMRC1 "This parameter displays an additional torque in percent of the reference e-motor torque.";
CM_ SG_ 2566856794 Actual_EMotor_Ouput_Shaft_Speed_EMRC1 "The calculated output torque of the e-motor.";
CM_ SG_ 2566856794 Drivers_Demand_EMotor_Retarder_Percent_Torque_EMRC1 "Driver's demand e-motor percent torque.";
CM_ SG_ 2566856794 Source_Adress_of_Ctrl_Device_EMRC1 "Based on J1939 (EEC1).";
CM_ SG_ 2566856794 Intended_EMotor_Percent_Torque_EMRC1 "Braking torque of e-motor that the e-motor is currently trying to achieve.";
CM_ SG_ 2566856794 Actual_Maximum_Available_EMotor_Recuperation_Torque_EMRC1 "This is the maximum amount of torque that the e-motor can immediately deliver.";
CM_ SG_ 2364539908 EMotor_TrqRet_Mode_Axle2 "State signal which indicates which E-Motor torque mode is currently generating, limiting, or controlling the torque.";
CM_ SG_ 2364539908 Actual_EMotor_Percent_Torque_high_resolution_Axle2 "This parameter displays an additional torque in percent of the reference E-Motor torque.";
CM_ SG_ 2364539908 Drivers_Demand_EMotor_Percent_Torque_Axle2 "Driver's Demand E-Motor - Percent Torque";
CM_ SG_ 2364539908 E_Actual_EMotor_Percent_Torque_Axle2 "The calculated output torque of the E-Motor.";
CM_ SG_ 2364539908 EMotor_Speed_Axle2 "Actual E-Motor speed";
CM_ SG_ 2364539908 Source_Adress_of_Ctrl_Device_Axle2 "Based on J1939 (EEC1)";
CM_ SG_ 2364539652 Actual_Maximum_Available_Engine_Percent_Torque_Axle2 "This is the maximum amount of torque that the engine can immediately deliver as a percentage of the reference engine torque (SPN 544).  The Actual Maximum Available Engine - Percent Torque shall take into consideration all engine torque derates (e.g. air fuel ratio control (AFC), noise control, etc.) that could potentially be active in the system.  This parameter differentiates itself from the engine percent torque points 1 through 5 of the engine configuration map because it takes into account all dynamic internal inputs such as  AFC and that it is updated on a 50ms basis.";
CM_ SG_ 2566840068 Nominal_FrictionPercent_Torque_Axle2 "E-Motor /Drivettrain recuperation torque, wich is created by ZF Energy recuperation strategy. Always negative or 0.";
CM_ SG_ 2566840068 Engine_EMotor_Parasitic_Losses_Axle2 "Estimated losses of the Motor. Not comparable to the combustion engine; will always send with 0%";
CM_ SG_ 2565865476 EMotor_Torque_Mode_Axle2 "State signal which indicates which retarder torque mode is currently generating, limiting, or controlling the torque.";
CM_ SG_ 2565865476 Recuperation_Enable_Switch_Axle2 "Signal which indicates that the Driveline is principially ready to recuperate (send out always as acitve; signal instead of AUX-IO, recperation enable request)";
CM_ SG_ 2565865476 R_Actual_EMotor_Percent_Torque_Axle2 "Actual braking torque of the E-Motor as a percent of E-Motor configuration reference torque SPN 556";
CM_ SG_ 2565865476 Intended_EMotor_Percent_Torque_Axle2 "Braking torque of E-Motor that the E-Motor is currently trying to achieve";
CM_ SG_ 2565865476 Source_Adress_of_Crtl_Device_Axle2 "The source address of the device currently controlling the E-Motor";
CM_ SG_ 2565865476 Driver_Demand_EMotor_Percent_Torque_Axle2 "The Drivers demand E-Motor – percent torque is the maximum torque selected by the driver";
CM_ SG_ 2565865476 Actual_Maximum_Available_EMotor_Recuperation_Torque_Axle2 "This is the maximum amount of torque that the E-Motor can immediately deliver";
CM_ SG_ 2566856708 Emotor_Trq_Ret_Mode_EMRC1_Axle2 "State signal which indicates which e-motor torque mode is currently generating, limiting or controlling the torque.";
CM_ SG_ 2566856708 Actual_Emotor_Percent_Torque_High_Resolution_EMRC1_Axle2 "This parameter displays an additional torque in percent of the reference e-motor torque.";
CM_ SG_ 2566856708 Actual_Emotor_Percent_Torque_EMRC1_Axle2 "This parameter displays an additional torque in percent of the reference e-motor torque.";
CM_ SG_ 2566856708 Actual_EMotor_Ouput_Shaft_Speed_EMRC1_Axle2 "The calculated output torque of the e-motor.";
CM_ SG_ 2566856708 Drivers_Demand_EMotor_Retarder_Percent_Torque_EMRC1_Axle2 "Driver's demand e-motor percent torque.";
CM_ SG_ 2566856708 Source_Adress_of_Ctrl_Device_EMRC1_Axle2 "Based on J1939 (EEC1).";
CM_ SG_ 2566856708 Intended_EMotor_Percent_Torque_EMRC1_Axle2 "Braking torque of e-motor that the e-motor is currently trying to achieve.";
CM_ SG_ 2566856708 Actual_Maximum_Available_EMotor_Recuperation_Torque_EMRC1_Axle2 "This is the maximum amount of torque that the e-motor can immediately deliver.";
CM_ SG_ 2565866074 Driveline_Engaged "Driveline engaged indicates that the electircal Driveline is ready to drive (Inverters are active)";
CM_ SG_ 2565866074 Shift_In_Progress "Will be send with “0“   in case of :AVE, AX2LF, CeTrax, Cetrax LiteOtherwise it shows the status of  shifting";
CM_ SG_ 2565866074 Transmission_Output_Shaft_Speed "Calculated speed of the transmission output shaft.";
CM_ SG_ 2565866074 ETC_EMotor_Speed "Speed of the Emotor (typicall factor 0.5)";
CM_ SG_ 2565866842 Transmission_Selected_Gear "The gear that the transmission will attempt to achieve during the current shift if a shift is in progress, or the next shift if one is pending (i.e., waiting for torque reduction to initiate the shift).forward 1..125 (unsigned value 126..250)neutral 0 (unsigned value 125)reverse -125..-1 (unsigned value 0..124)error or not available > 125 (unsigned value > 250)";
CM_ SG_ 2565866842 Transmission_Actual_Gear_Ratio "Actual ratio of input shaft speed to output shaft speed.";
CM_ SG_ 2565866842 Transmission_Current_Gear "The gear currently engaged in the transmission or the last gear engaged while the transmission is in the process of shifting to the new or selected gear.  Transitions toward a destination gear will not be indicated.  Once the selected gear has been engaged then Transmission Current Gear (SPN 523) will reflect that gear.forward 1..125 (unsigned value 126..250)neutral 0 (unsigned value 125)reverse -125..-1 (unsigned value 0..124)error or not available > 125 (unsigned value > 250)";
CM_ SG_ 2565866842 Transmission_Requested_Range "Range selected by the operator.  Characters may include P, Rx, Rx-1...R2, R1, R, Nx, Nx-1...N2, N1, N, D, D1, D2..., Dx, L, L1, L2..., Lx-1, 1, 2, 3,...  If only one displayed character is required, the second character shall be used and the first character shall be a space (ASCII 32) or a control character (ASCII 0 to 31).  If the first character is a control character, refer to the manufacturer's application document for definition.";
CM_ SG_ 2566802010 Transmission_Ready_for_Brake_Release "This parameter indicates that enough torque / motive force is available at the transmission output shaft to release all the brakes without a risk of unintentional movement in the opposite direction.";
CM_ SG_ 2566840922 Number_of_Reverse_Gear_Ratios "Number of reverse gear ratios in the transmission, provided as part of the transmission configuration.";
CM_ SG_ 2566840922 Number_of_Forward_Gear_Ratios "Number of forward gear ratios in the transmission, provided as part of the configuration.";
CM_ SG_ 2566840922 Transmission_Gear_Ratio "The transmission configuration describes the number of forward gears, the number of reverse gears, and the ratio of each gear with the following resolution";
CM_ SG_ 2566846554 Transmission_Oil_Temperature1 "First instance of transmission lubricant temperature.";
CM_ SG_ 2565867098 DiffLockStateRearAxle1_EAC1 "State used which indicates the condition of the rear axle 1 differential lock.?";
CM_ SG_ 2565865988 Driveline_Engaged_Axle2 "Driveline engaged indicates that the electircal Driveline is ready to drive (Inverters are active)";
CM_ SG_ 2565865988 Shift_In_Progress_Axle2 "Will be send with “0“   in case of :AVE, AX2LF, CeTrax, Cetrax LiteOtherwise it shows the status of  shifting";
CM_ SG_ 2565865988 Transmission_Output_Shaft_Speed_Axle2 "Calculated speed of the transmission output shaft.";
CM_ SG_ 2565865988 ETC_EMotor_Speed_Axle2 "Speed of the Emotor (typicall factor 0.5)";
CM_ SG_ 2565866756 Transmission_Selected_Gear_Axle2 "The gear that the transmission will attempt to achieve during the current shift if a shift is in progress, or the next shift if one is pending (i.e., waiting for torque reduction to initiate the shift).forward 1..125 (unsigned value 126..250)neutral 0 (unsigned value 125)reverse -125..-1 (unsigned value 0..124)error or not available > 125 (unsigned value > 250)";
CM_ SG_ 2565866756 Transmission_Actual_Gear_Ratio_Axle2 "Actual ratio of input shaft speed to output shaft speed.";
CM_ SG_ 2565866756 Transmission_Current_Gear_Axle2 "The gear currently engaged in the transmission or the last gear engaged while the transmission is in the process of shifting to the new or selected gear.  Transitions toward a destination gear will not be indicated.  Once the selected gear has been engaged then Transmission Current Gear (SPN 523) will reflect that gear.forward 1..125 (unsigned value 126..250)neutral 0 (unsigned value 125)reverse -125..-1 (unsigned value 0..124)error or not available > 125 (unsigned value > 250)";
CM_ SG_ 2565866756 Transmission_Requested_Range_Axle2 "Range selected by the operator.  Characters may include P, Rx, Rx-1...R2, R1, R, Nx, Nx-1...N2, N1, N, D, D1, D2..., Dx, L, L1, L2..., Lx-1, 1, 2, 3,...  If only one displayed character is required, the second character shall be used and the first character shall be a space (ASCII 32) or a control character (ASCII 0 to 31).  If the first character is a control character, refer to the manufacturer's application document for definition.";
CM_ SG_ 2566801924 Transmission_Ready_for_Brake_Release_Axle2 "This parameter indicates that enough torque / motive force is available at the transmission output shaft to release all the brakes without a risk of unintentional movement in the opposite direction.";
CM_ SG_ 2566840836 Number_of_Reverse_Gear_Ratios_Axle2 "Number of reverse gear ratios in the transmission, provided as part of the transmission configuration.";
CM_ SG_ 2566840836 Number_of_Forward_Gear_Ratios_Axle2 "Number of forward gear ratios in the transmission, provided as part of the configuration.";
CM_ SG_ 2566840836 Transmission_Gear_Ratio_Axle2 "The transmission configuration describes the number of forward gears, the number of reverse gears, and the ratio of each gear with the following resolution";
CM_ SG_ 2566846468 Transmission_Oil_Temperature1_Axle2 "First instance of transmission lubricant temperature.";
CM_ SG_ 2565867012 DiffLockStateRearAxle2_EAC1 "State used which indicates the condition of the rear axle 2 differential lock.?";
CM_ SG_ 2349075290 External_Acceleration_Demand "This is the acceleration which the brake system isexpected to realize. It is specified as an absolute acceleration in reference to the road";
CM_ SG_ 2349075290 XBR_EBI_Mode "The XBR EBI (Endurance Brake Integration) Mode is used as an input for the brake system to prescribe the use ofendurance brakes like retarders or engine brakes.";
CM_ SG_ 2349075290 XBR_Priority "The XBR Priority is used as an input to the brake system to manage the priority of overlapping external and internalrequests.";
CM_ SG_ 2349075290 XBR_Control_Mode "The XBR Control Mode is used as an input to the brake system and defines how the external acceleration demand has tobe realized.";
CM_ SG_ 2349075290 XBR_urgency "Currently not used";
CM_ SG_ 2349075290 XBR_Message_Counter "The XBR message counter is to verify the signal path from the demanding device to the brake controller on electronicbrake systems.. The support of this parameter is mandatory.";
CM_ SG_ 2349075290 XBR_Message_Checksum "The XBR message checksum is used to verify the signal path from the demanding device to the brake controller on electronic brake systems. The support of this parameter is mandatory if PGN 1024 is supported as there is no means to indicate “not available”.";
CM_ SG_ 2349075204 External_Acceleration_Demand_Axle2 "This is the acceleration which the brake system isexpected to realize. It is specified as an absolute acceleration in reference to the road";
CM_ SG_ 2349075204 XBR_EBI_Mode_Axle2 "The XBR EBI (Endurance Brake Integration) Mode is used as an input for the brake system to prescribe the use ofendurance brakes like retarders or engine brakes.";
CM_ SG_ 2349075204 XBR_Priority_Axle2 "The XBR Priority is used as an input to the brake system to manage the priority of overlapping external and internalrequests.";
CM_ SG_ 2349075204 XBR_Control_Mode_Axle2 "The XBR Control Mode is used as an input to the brake system and defines how the external acceleration demand has tobe realized.";
CM_ SG_ 2349075204 XBR_urgency_Axle2 "Currently not used";
CM_ SG_ 2349075204 XBR_Message_Counter_Axle2 "The XBR message counter is to verify the signal path from the demanding device to the brake controller on electronicbrake systems.. The support of this parameter is mandatory.";
CM_ SG_ 2349075204 XBR_Message_Checksum_Axle2 "The XBR message checksum is used to verify the signal path from the demanding device to the brake controller on electronic brake systems. The support of this parameter is mandatory if PGN 1024 is supported as there is no means to indicate “not available”.";
CM_ SG_ 2355941466 Allowed_Towing_Mode "Shows allowed towing modes";
CM_ SG_ 2355941466 Towing_Error "show if towing mode parameters have been exceeded";
CM_ SG_ 2355941380 Allowed_Towing_Mode_Axle2 "Shows allowed towing modes";
CM_ SG_ 2355941380 Towing_Error_Axle2 "show if towing mode parameters have been exceeded";
BA_DEF_ BO_ "GenMsgSendType" ENUM "Cycle","NoMsgSendType","IfActive","Event","CA","CE";
BA_DEF_ BO_ "GenMsgNrOfRepetition" INT 0 0;
BA_DEF_ BO_ "GenMsgILSupport" ENUM "No","Yes";
BA_DEF_ BO_ "GenMsgCycleTimeFast" INT 0 0;
BA_DEF_ BO_ "GenMsgCycleTime" INT 0 0;
BA_DEF_ BO_ "NmMessage" ENUM "No","Yes";
BA_DEF_ BO_ "VFrameFormat" ENUM "StandardCAN","ExtendedCAN","reserved","J1939PG";
BA_DEF_ BO_ "J1939CPgTOS" INT 0 7;
BA_DEF_ BO_ "J1939CPgSendTimeout" INT -1 3600000;
BA_DEF_ BO_ "J1939PgAppearanceOnBus" ENUM "Default","CAN_Extended","CANFD_Extended";
BA_DEF_ BO_ "GenMsgRequestable" INT 0 1;
BA_DEF_ SG_ "GenSigInvalidValue" HEX 0 0;
BA_DEF_ SG_ "GenSigStartValue" HEX 0 0;
BA_DEF_ SG_ "GenSigInactiveValue" HEX 0 0;
BA_DEF_ SG_ "GenSigSendType" ENUM "Cycle","OnWrite","OnWriteWithRepetition","OnChange","OnChangeWithRepetition","IfActive","IfActiveWithRepetition","NoSigSendType","vector_leerstring";
BA_DEF_ SG_ "SPN" INT 0 0;
BA_DEF_ SG_ "ASIL" STRING ;
BA_DEF_ SG_ "SigType" ENUM "Default","Range","RangeSigned","ASCII","Discrete","Control","ReferencePGN","DTC","StringDelimiter","StringLength","StringLengthControl","MessageCounter","MessageChecksum";
BA_DEF_ SG_ "GenSigILSupport" ENUM "No","Yes";
BA_DEF_ SG_ "GenSigEVName" STRING ;
BA_DEF_DEF_ "GenMsgSendType" "Cycle";
BA_DEF_DEF_ "GenMsgNrOfRepetition" 0;
BA_DEF_DEF_ "GenMsgILSupport" "Yes";
BA_DEF_DEF_ "GenMsgCycleTimeFast" 0;
BA_DEF_DEF_ "GenMsgCycleTime" 100;
BA_DEF_DEF_ "NmMessage" "No";
BA_DEF_DEF_ "VFrameFormat" "StandardCAN";
BA_DEF_DEF_ "J1939CPgTOS" 2;
BA_DEF_DEF_ "J1939CPgSendTimeout" -1;
BA_DEF_DEF_ "J1939PgAppearanceOnBus" "Default";
BA_DEF_DEF_ "GenMsgRequestable" 1;
BA_DEF_DEF_ "GenSigInvalidValue" 0;
BA_DEF_DEF_ "GenSigStartValue" 0;
BA_DEF_DEF_ "GenSigInactiveValue" 0;
BA_DEF_DEF_ "GenSigSendType" "Cycle";
BA_DEF_DEF_ "SPN" 0;
BA_DEF_DEF_ "ASIL" "";
BA_DEF_DEF_ "SigType" "Default";
BA_DEF_DEF_ "GenSigILSupport" "Yes";
BA_DEF_DEF_ "GenSigEVName" "Env@Nodename_@Signame";
BA_ "GenMsgCycleTime" BO_ 2566834778 0;
BA_ "GenMsgSendType" BO_ 2566834778 3;
BA_ "VFrameFormat" BO_ 2566834778 3;
BA_ "GenMsgCycleTime" BO_ 2566834692 0;
BA_ "GenMsgSendType" BO_ 2566834692 3;
BA_ "VFrameFormat" BO_ 2566834692 3;
BA_ "GenMsgCycleTime" BO_ 2355220570 10;
BA_ "VFrameFormat" BO_ 2355220570 3;
BA_ "GenMsgCycleTime" BO_ 2355286106 20;
BA_ "VFrameFormat" BO_ 2355286106 3;
BA_ "VFrameFormat" BO_ 2355351642 3;
BA_ "GenMsgCycleTime" BO_ 2355417178 20;
BA_ "VFrameFormat" BO_ 2355417178 3;
BA_ "GenMsgCycleTime" BO_ 2355482714 20;
BA_ "VFrameFormat" BO_ 2355482714 3;
BA_ "GenMsgCycleTime" BO_ 2355548250 20;
BA_ "VFrameFormat" BO_ 2355548250 3;
BA_ "GenMsgCycleTime" BO_ 2356007002 200;
BA_ "VFrameFormat" BO_ 2356007002 3;
BA_ "GenMsgCycleTime" BO_ 2355220484 10;
BA_ "VFrameFormat" BO_ 2355220484 3;
BA_ "GenMsgCycleTime" BO_ 2355286020 20;
BA_ "VFrameFormat" BO_ 2355286020 3;
BA_ "VFrameFormat" BO_ 2355351556 3;
BA_ "GenMsgCycleTime" BO_ 2355417092 20;
BA_ "VFrameFormat" BO_ 2355417092 3;
BA_ "GenMsgCycleTime" BO_ 2355548164 20;
BA_ "VFrameFormat" BO_ 2355548164 3;
BA_ "GenMsgCycleTime" BO_ 2356006916 200;
BA_ "VFrameFormat" BO_ 2356006916 3;
BA_ "GenMsgCycleTime" BO_ 2355613786 500;
BA_ "VFrameFormat" BO_ 2355613786 3;
BA_ "GenMsgCycleTime" BO_ 2557005914 500;
BA_ "VFrameFormat" BO_ 2557005914 3;
BA_ "GenMsgCycleTime" BO_ 2557071450 500;
BA_ "VFrameFormat" BO_ 2557071450 3;
BA_ "GenMsgCycleTime" BO_ 2557136986 500;
BA_ "VFrameFormat" BO_ 2557136986 3;
BA_ "GenMsgCycleTime" BO_ 2557202522 500;
BA_ "VFrameFormat" BO_ 2557202522 3;
BA_ "GenMsgCycleTime" BO_ 2566899802 20;
BA_ "VFrameFormat" BO_ 2566899802 3;
BA_ "GenMsgCycleTime" BO_ 2566840666 5000;
BA_ "VFrameFormat" BO_ 2566840666 3;
BA_ "GenMsgCycleTime" BO_ 2355613700 500;
BA_ "VFrameFormat" BO_ 2355613700 3;
BA_ "GenMsgCycleTime" BO_ 2557005828 500;
BA_ "VFrameFormat" BO_ 2557005828 3;
BA_ "GenMsgCycleTime" BO_ 2557071364 500;
BA_ "VFrameFormat" BO_ 2557071364 3;
BA_ "GenMsgCycleTime" BO_ 2557136900 500;
BA_ "VFrameFormat" BO_ 2557136900 3;
BA_ "GenMsgCycleTime" BO_ 2557202436 500;
BA_ "VFrameFormat" BO_ 2557202436 3;
BA_ "GenMsgCycleTime" BO_ 2566899716 20;
BA_ "VFrameFormat" BO_ 2566899716 3;
BA_ "GenMsgCycleTime" BO_ 2566840580 5000;
BA_ "VFrameFormat" BO_ 2566840580 3;
BA_ "GenMsgCycleTime" BO_ 2566841178 5000;
BA_ "VFrameFormat" BO_ 2566841178 3;
BA_ "GenMsgCycleTime" BO_ 2566841092 5000;
BA_ "VFrameFormat" BO_ 2566841092 3;
BA_ "GenMsgCycleTime" BO_ 2364539994 10;
BA_ "VFrameFormat" BO_ 2364539994 3;
BA_ "GenMsgCycleTime" BO_ 2364539738 50;
BA_ "VFrameFormat" BO_ 2364539738 3;
BA_ "GenMsgCycleTime" BO_ 2566840154 250;
BA_ "VFrameFormat" BO_ 2566840154 3;
BA_ "VFrameFormat" BO_ 2565865562 3;
BA_ "GenMsgCycleTime" BO_ 2566856794 10;
BA_ "VFrameFormat" BO_ 2566856794 3;
BA_ "GenMsgCycleTime" BO_ 2364539908 10;
BA_ "VFrameFormat" BO_ 2364539908 3;
BA_ "GenMsgCycleTime" BO_ 2364539652 50;
BA_ "VFrameFormat" BO_ 2364539652 3;
BA_ "GenMsgCycleTime" BO_ 2566840068 250;
BA_ "VFrameFormat" BO_ 2566840068 3;
BA_ "VFrameFormat" BO_ 2565865476 3;
BA_ "GenMsgCycleTime" BO_ 2566856708 10;
BA_ "VFrameFormat" BO_ 2566856708 3;
BA_ "VFrameFormat" BO_ 2565866074 3;
BA_ "GenMsgCycleTime" BO_ 2565866842 50;
BA_ "VFrameFormat" BO_ 2565866842 3;
BA_ "VFrameFormat" BO_ 2566802010 3;
BA_ "GenMsgCycleTime" BO_ 2566840922 5000;
BA_ "VFrameFormat" BO_ 2566840922 3;
BA_ "GenMsgCycleTime" BO_ 2566846554 1000;
BA_ "VFrameFormat" BO_ 2566846554 3;
BA_ "GenMsgCycleTime" BO_ 2565867098 500;
BA_ "VFrameFormat" BO_ 2565867098 3;
BA_ "VFrameFormat" BO_ 2565865988 3;
BA_ "GenMsgCycleTime" BO_ 2565866756 50;
BA_ "VFrameFormat" BO_ 2565866756 3;
BA_ "VFrameFormat" BO_ 2566801924 3;
BA_ "GenMsgCycleTime" BO_ 2566840836 5000;
BA_ "VFrameFormat" BO_ 2566840836 3;
BA_ "GenMsgCycleTime" BO_ 2566846468 1000;
BA_ "VFrameFormat" BO_ 2566846468 3;
BA_ "GenMsgCycleTime" BO_ 2565867012 500;
BA_ "VFrameFormat" BO_ 2565867012 3;
BA_ "GenMsgCycleTime" BO_ 2349075290 50;
BA_ "VFrameFormat" BO_ 2349075290 3;
BA_ "GenMsgCycleTime" BO_ 2349075204 50;
BA_ "VFrameFormat" BO_ 2349075204 3;
BA_ "GenMsgCycleTime" BO_ 2355941466 200;
BA_ "VFrameFormat" BO_ 2355941466 3;
BA_ "GenMsgCycleTime" BO_ 2355941380 200;
BA_ "VFrameFormat" BO_ 2355941380 3;
BA_ "SPN" SG_ 2566834778 ProtectLampStatus_MTCU 987;
BA_ "SPN" SG_ 2566834778 AmberWarningLampStatus_MTCU 624;
BA_ "SPN" SG_ 2566834778 RedStopLampState_MTCU 623;
BA_ "SPN" SG_ 2566834778 MalfunctionIndicatorLampStatus_MTCU 1213;
BA_ "SPN" SG_ 2566834778 FlashProtectLamp_MTCU 3041;
BA_ "SPN" SG_ 2566834778 FlashAmberWarningLamp_MTCU 3040;
BA_ "SPN" SG_ 2566834778 FlashRedStopLamp_MTCU 3039;
BA_ "SPN" SG_ 2566834778 FlashMalfuncIndicatorLamp_MTCU 3038;
BA_ "SPN" SG_ 2566834692 ProtectLampStatus_MTCU_Axle2 987;
BA_ "SPN" SG_ 2566834692 AmberWarningLampStatus_MTCU_Axle2 624;
BA_ "SPN" SG_ 2566834692 RedStopLampState_MTCU_Axle2 623;
BA_ "SPN" SG_ 2566834692 MalfunctionIndicatorLampStatus_MTCU_Axle2 1213;
BA_ "SPN" SG_ 2566834692 FlashProtectLamp_MTCU_Axle2 3041;
BA_ "SPN" SG_ 2566834692 FlashAmberWarningLamp_MTCU_Axle2 3040;
BA_ "SPN" SG_ 2566834692 FlashRedStopLamp_MTCU_Axle2 3039;
BA_ "SPN" SG_ 2566834692 FlashMalfuncIndicatorLamp_MTCU_Axle2 3038;
BA_ "GenSigInvalidValue" SG_ 2355613786 Trax1_STRATEGY_FAULT_LEVEL_ 15;
BA_ "GenSigInvalidValue" SG_ 2355613786 Trax1_HI_INTERLOCK_FAULT 3;
BA_ "GenSigInvalidValue" SG_ 2355613786 Inverter_1_OVERTEMP_MTCU6 3;
BA_ "GenSigInvalidValue" SG_ 2355613786 EMotor_1_OVERTEMP_MTCU6 3;
BA_ "GenSigInvalidValue" SG_ 2355613786 Inverter_2_OVERTEMP_MTCU6 3;
BA_ "GenSigInvalidValue" SG_ 2355613786 EMotor_2_OVERTEMP_MTCU6 3;
BA_ "SPN" SG_ 2566840666 Retarder_Type 901;
BA_ "SPN" SG_ 2566840666 Retarder_Location 902;
BA_ "SPN" SG_ 2566840666 Retarder_Speed_at_Idle_point1 546;
BA_ "SPN" SG_ 2566840666 RC_Percent_Torque_at_Idle_point1 551;
BA_ "SPN" SG_ 2566840666 Maximum_Retarder_Speed_point2 548;
BA_ "SPN" SG_ 2566840666 RC_Percent_Torque_at_maximum_Speed_point2 552;
BA_ "SPN" SG_ 2566840666 Retarder_Speed_at_point3 549;
BA_ "SPN" SG_ 2566840666 RC_Percent_Torque_at_point3 553;
BA_ "SPN" SG_ 2566840666 Retarder_Speed_at_point4 550;
BA_ "SPN" SG_ 2566840666 RC_Percent_Torque_at_point4 554;
BA_ "SPN" SG_ 2566840666 Retarder_Speed_at_peak_Torque_point5 547;
BA_ "SPN" SG_ 2566840666 Reference_Retarder_Torque 556;
BA_ "SPN" SG_ 2566840666 RC_Percent_Torque_at_point5 555;
BA_ "GenSigInvalidValue" SG_ 2355613700 Trax2_STRATEGY_FAULT_LEVEL_ 15;
BA_ "GenSigInvalidValue" SG_ 2355613700 Trax2_HI_INTERLOCK_FAULT 3;
BA_ "GenSigInvalidValue" SG_ 2355613700 Inverter_2_OVERTEMP_MTCU6_Axle2_1 3;
BA_ "GenSigInvalidValue" SG_ 2355613700 EMotor_2_OVERTEMP_MTCU6_Axle2_1 3;
BA_ "GenSigInvalidValue" SG_ 2355613700 Inverter_2_OVERTEMP_MTCU6_Axle2 3;
BA_ "GenSigInvalidValue" SG_ 2355613700 EMotor_2_OVERTEMP_MTCU6_Axle2 3;
BA_ "SPN" SG_ 2566840580 Retarder_Type_Axle2 901;
BA_ "SPN" SG_ 2566840580 Retarder_Location_Axle2 902;
BA_ "SPN" SG_ 2566840580 Retarder_Speed_at_Idle_point1_Axle2 546;
BA_ "SPN" SG_ 2566840580 RC_Percent_Torque_at_Idle_point1_Axle2 551;
BA_ "SPN" SG_ 2566840580 Maximum_Retarder_Speed_point2_Axle2 548;
BA_ "SPN" SG_ 2566840580 RC_Percent_Torque_at_maximum_Speed_point2_Axle2 552;
BA_ "SPN" SG_ 2566840580 Retarder_Speed_at_point3_Axle2 549;
BA_ "SPN" SG_ 2566840580 RC_Percent_Torque_at_point3_Axle2 553;
BA_ "SPN" SG_ 2566840580 Retarder_Speed_at_point4_Axle2 550;
BA_ "SPN" SG_ 2566840580 RC_Percent_Torque_at_point4_Axle2 554;
BA_ "SPN" SG_ 2566840580 Retarder_Speed_at_peak_Torque_point5_Axle2 547;
BA_ "SPN" SG_ 2566840580 Reference_Retarder_Torque_Axle2 556;
BA_ "SPN" SG_ 2566840580 RC_Percent_Torque_at_point5_Axle2 555;
BA_ "SPN" SG_ 2566841178 EMotor_speed_at_idle_Point1 188;
BA_ "SPN" SG_ 2566841178 EC_Percent_Torque_at_Idle_Point1 539;
BA_ "SPN" SG_ 2566841178 EMotor_Speed_at_Point2 528;
BA_ "SPN" SG_ 2566841178 EC_Percent_Torque_at_Point2 540;
BA_ "SPN" SG_ 2566841178 EMotor_Speed_at_Point3 529;
BA_ "SPN" SG_ 2566841178 EC_Percent_Torque_at_Point3 541;
BA_ "SPN" SG_ 2566841178 EMotor_Speed_at_Point4 530;
BA_ "SPN" SG_ 2566841178 EC_Percent_Torque_at_Point4 542;
BA_ "SPN" SG_ 2566841178 EMotor_Speed_at_Point5 531;
BA_ "SPN" SG_ 2566841178 EC_Percent_Torque_at_Point5 543;
BA_ "SPN" SG_ 2566841178 EMotor_reference_torque 544;
BA_ "SPN" SG_ 2566841092 EMotor_speed_at_idle_Point1_Axle2 188;
BA_ "SPN" SG_ 2566841092 EC_Percent_Torque_at_Idle_Point1_Axle2 539;
BA_ "SPN" SG_ 2566841092 EMotor_Speed_at_Point2_Axle2 528;
BA_ "SPN" SG_ 2566841092 EC_Percent_Torque_at_Point2_Axle2 540;
BA_ "SPN" SG_ 2566841092 EMotor_Speed_at_Point3_Axle2 529;
BA_ "SPN" SG_ 2566841092 EC_Percent_Torque_at_Point3_Axle2 541;
BA_ "SPN" SG_ 2566841092 EMotor_Speed_at_Point4_Axle2 530;
BA_ "SPN" SG_ 2566841092 EC_Percent_Torque_at_Point4_Axle2 542;
BA_ "SPN" SG_ 2566841092 EMotor_Speed_at_Point5_Axle2 531;
BA_ "SPN" SG_ 2566841092 EC_Percent_Torque_at_Point5_Axle2 543;
BA_ "SPN" SG_ 2566841092 EMotor_reference_torque_Axle2 544;
BA_ "SPN" SG_ 2364539994 EMotor_TrqRet_Mode 899;
BA_ "SPN" SG_ 2364539994 Actual_EMotor_Percent_Torque_high_resolution 4154;
BA_ "SPN" SG_ 2364539994 Drivers_Demand_EMotor_Percent_Torque 512;
BA_ "SPN" SG_ 2364539994 E_Actual_EMotor_Percent_Torque 513;
BA_ "SPN" SG_ 2364539994 EMotor_Speed 190;
BA_ "SPN" SG_ 2364539994 Source_Adress_of_Ctrl_Device 1483;
BA_ "SPN" SG_ 2364539738 Actual_Maximum_Available_Engine_Percent_Torque 3357;
BA_ "SPN" SG_ 2566840154 Nominal_FrictionPercent_Torque 514;
BA_ "SPN" SG_ 2566840154 Engine_EMotor_Parasitic_Losses 2978;
BA_ "SPN" SG_ 2565865562 EMotor_Torque_Mode 900;
BA_ "SPN" SG_ 2565865562 Recuperation_Enable_Switch 571;
BA_ "SPN" SG_ 2565865562 R_Actual_EMotor_Percent_Torque 520;
BA_ "SPN" SG_ 2565865562 Intended_EMotor_Percent_Torque 1085;
BA_ "SPN" SG_ 2565865562 Source_Adress_of_Crtl_Device 1480;
BA_ "SPN" SG_ 2565865562 Driver_Demand_EMotor_Percent_Torque 1715;
BA_ "SPN" SG_ 2565865562 Actual_Maximum_Available_EMotor_Recuperation_Torque 1717;
BA_ "SPN" SG_ 2566856794 Actual_Emotor_Percent_Torque_High_Resolution_EMRC1 4154;
BA_ "SPN" SG_ 2566856794 Actual_Emotor_Percent_Torque_EMRC1 4154;
BA_ "SPN" SG_ 2566856794 Actual_EMotor_Ouput_Shaft_Speed_EMRC1 513;
BA_ "SPN" SG_ 2566856794 Drivers_Demand_EMotor_Retarder_Percent_Torque_EMRC1 512;
BA_ "SPN" SG_ 2566856794 Source_Adress_of_Ctrl_Device_EMRC1 1483;
BA_ "SPN" SG_ 2566856794 Intended_EMotor_Percent_Torque_EMRC1 1085;
BA_ "SPN" SG_ 2566856794 Actual_Maximum_Available_EMotor_Recuperation_Torque_EMRC1 1717;
BA_ "SPN" SG_ 2364539908 EMotor_TrqRet_Mode_Axle2 899;
BA_ "SPN" SG_ 2364539908 Actual_EMotor_Percent_Torque_high_resolution_Axle2 4154;
BA_ "SPN" SG_ 2364539908 Drivers_Demand_EMotor_Percent_Torque_Axle2 512;
BA_ "SPN" SG_ 2364539908 E_Actual_EMotor_Percent_Torque_Axle2 513;
BA_ "SPN" SG_ 2364539908 EMotor_Speed_Axle2 190;
BA_ "SPN" SG_ 2364539908 Source_Adress_of_Ctrl_Device_Axle2 1483;
BA_ "SPN" SG_ 2364539652 Actual_Maximum_Available_Engine_Percent_Torque_Axle2 3357;
BA_ "SPN" SG_ 2566840068 Nominal_FrictionPercent_Torque_Axle2 514;
BA_ "SPN" SG_ 2566840068 Engine_EMotor_Parasitic_Losses_Axle2 2978;
BA_ "SPN" SG_ 2565865476 EMotor_Torque_Mode_Axle2 900;
BA_ "SPN" SG_ 2565865476 Recuperation_Enable_Switch_Axle2 571;
BA_ "SPN" SG_ 2565865476 R_Actual_EMotor_Percent_Torque_Axle2 520;
BA_ "SPN" SG_ 2565865476 Intended_EMotor_Percent_Torque_Axle2 1085;
BA_ "SPN" SG_ 2565865476 Source_Adress_of_Crtl_Device_Axle2 1480;
BA_ "SPN" SG_ 2565865476 Driver_Demand_EMotor_Percent_Torque_Axle2 1715;
BA_ "SPN" SG_ 2565865476 Actual_Maximum_Available_EMotor_Recuperation_Torque_Axle2 1717;
BA_ "SPN" SG_ 2566856708 Actual_Emotor_Percent_Torque_High_Resolution_EMRC1_Axle2 4154;
BA_ "SPN" SG_ 2566856708 Actual_Emotor_Percent_Torque_EMRC1_Axle2 4154;
BA_ "SPN" SG_ 2566856708 Actual_EMotor_Ouput_Shaft_Speed_EMRC1_Axle2 513;
BA_ "SPN" SG_ 2566856708 Drivers_Demand_EMotor_Retarder_Percent_Torque_EMRC1_Axle2 512;
BA_ "SPN" SG_ 2566856708 Source_Adress_of_Ctrl_Device_EMRC1_Axle2 1483;
BA_ "SPN" SG_ 2566856708 Intended_EMotor_Percent_Torque_EMRC1_Axle2 1085;
BA_ "SPN" SG_ 2566856708 Actual_Maximum_Available_EMotor_Recuperation_Torque_EMRC1_Axle2 1717;
BA_ "SPN" SG_ 2565866074 Driveline_Engaged 560;
BA_ "SPN" SG_ 2565866074 Shift_In_Progress 574;
BA_ "SPN" SG_ 2565866074 Transmission_Output_Shaft_Speed 191;
BA_ "SPN" SG_ 2565866074 ETC_EMotor_Speed 161;
BA_ "SPN" SG_ 2565866842 Transmission_Selected_Gear 524;
BA_ "SPN" SG_ 2565866842 Transmission_Actual_Gear_Ratio 526;
BA_ "SPN" SG_ 2565866842 Transmission_Current_Gear 523;
BA_ "SPN" SG_ 2565866842 Transmission_Requested_Range 162;
BA_ "SPN" SG_ 2566802010 Transmission_Ready_for_Brake_Release 3086;
BA_ "SPN" SG_ 2566840922 Number_of_Reverse_Gear_Ratios 958;
BA_ "SPN" SG_ 2566840922 Number_of_Forward_Gear_Ratios 957;
BA_ "SPN" SG_ 2566840922 Transmission_Gear_Ratio 981;
BA_ "SPN" SG_ 2566846554 Transmission_Oil_Temperature1 177;
BA_ "SPN" SG_ 2565867098 DiffLockStateRearAxle1_EAC1 569;
BA_ "SPN" SG_ 2565865988 Driveline_Engaged_Axle2 560;
BA_ "SPN" SG_ 2565865988 Shift_In_Progress_Axle2 574;
BA_ "SPN" SG_ 2565865988 Transmission_Output_Shaft_Speed_Axle2 191;
BA_ "SPN" SG_ 2565865988 ETC_EMotor_Speed_Axle2 161;
BA_ "SPN" SG_ 2565866756 Transmission_Selected_Gear_Axle2 524;
BA_ "SPN" SG_ 2565866756 Transmission_Actual_Gear_Ratio_Axle2 526;
BA_ "SPN" SG_ 2565866756 Transmission_Current_Gear_Axle2 523;
BA_ "SPN" SG_ 2565866756 Transmission_Requested_Range_Axle2 162;
BA_ "SPN" SG_ 2566801924 Transmission_Ready_for_Brake_Release_Axle2 3086;
BA_ "SPN" SG_ 2566840836 Number_of_Reverse_Gear_Ratios_Axle2 958;
BA_ "SPN" SG_ 2566840836 Number_of_Forward_Gear_Ratios_Axle2 957;
BA_ "SPN" SG_ 2566840836 Transmission_Gear_Ratio_Axle2 981;
BA_ "SPN" SG_ 2566846468 Transmission_Oil_Temperature1_Axle2 177;
BA_ "SPN" SG_ 2565867012 DiffLockStateRearAxle2_EAC1 570;
BA_ "SPN" SG_ 2349075290 External_Acceleration_Demand 2920;
BA_ "SPN" SG_ 2349075290 XBR_EBI_Mode 2914;
BA_ "SPN" SG_ 2349075290 XBR_Priority 2915;
BA_ "SPN" SG_ 2349075290 XBR_Control_Mode 2916;
BA_ "SPN" SG_ 2349075290 XBR_urgency 4099;
BA_ "SPN" SG_ 2349075290 XBR_Message_Counter 3189;
BA_ "SPN" SG_ 2349075290 XBR_Message_Checksum 3188;
BA_ "SPN" SG_ 2349075204 External_Acceleration_Demand_Axle2 2920;
BA_ "SPN" SG_ 2349075204 XBR_EBI_Mode_Axle2 2914;
BA_ "SPN" SG_ 2349075204 XBR_Priority_Axle2 2915;
BA_ "SPN" SG_ 2349075204 XBR_Control_Mode_Axle2 2916;
BA_ "SPN" SG_ 2349075204 XBR_urgency_Axle2 4099;
BA_ "SPN" SG_ 2349075204 XBR_Message_Counter_Axle2 3189;
BA_ "SPN" SG_ 2349075204 XBR_Message_Checksum_Axle2 3188;
VAL_ 2566834778 ProtectLampStatus_MTCU 3 "Notavailable" 2 "Reserved" 1 "Lampon" 0 "Lampoff";
VAL_ 2566834778 AmberWarningLampStatus_MTCU 3 "Notavailable" 2 "Reserved" 1 "Lampon" 0 "Lampoff";
VAL_ 2566834778 RedStopLampState_MTCU 3 "Notavailable" 2 "Reserved" 1 "Lampon" 0 "Lampoff";
VAL_ 2566834778 MalfunctionIndicatorLampStatus_MTCU 3 "Notavailable" 2 "Reserved" 1 "Lampon" 0 "Lampoff";
VAL_ 2566834778 FlashProtectLamp_MTCU 3 "Unavailable/DoNotFlash" 2 "Reserved" 1 "FastFlash" 0 "SlowFlash";
VAL_ 2566834778 FlashAmberWarningLamp_MTCU 3 "Unavailable/DoNotFlash" 2 "Reserved" 1 "FastFlash" 0 "SlowFlash";
VAL_ 2566834778 FlashRedStopLamp_MTCU 3 "Unavailable/DoNotFlash" 2 "Reserved" 1 "FastFlash" 0 "SlowFlash";
VAL_ 2566834778 FlashMalfuncIndicatorLamp_MTCU 3 "Unavailable/DoNotFlash" 2 "Reserved" 1 "FastFlash" 0 "SlowFlash";
VAL_ 2566834692 ProtectLampStatus_MTCU_Axle2 3 "Notavailable" 2 "Reserved" 1 "Lampon" 0 "Lampoff";
VAL_ 2566834692 AmberWarningLampStatus_MTCU_Axle2 3 "Notavailable" 2 "Reserved" 1 "Lampon" 0 "Lampoff";
VAL_ 2566834692 RedStopLampState_MTCU_Axle2 3 "Notavailable" 2 "Reserved" 1 "Lampon" 0 "Lampoff";
VAL_ 2566834692 MalfunctionIndicatorLampStatus_MTCU_Axle2 3 "Notavailable" 2 "Reserved" 1 "Lampon" 0 "Lampoff";
VAL_ 2566834692 FlashProtectLamp_MTCU_Axle2 3 "Unavailable/DoNotFlash" 2 "Reserved" 1 "FastFlash" 0 "SlowFlash";
VAL_ 2566834692 FlashAmberWarningLamp_MTCU_Axle2 3 "Unavailable/DoNotFlash" 2 "Reserved" 1 "FastFlash" 0 "SlowFlash";
VAL_ 2566834692 FlashRedStopLamp_MTCU_Axle2 3 "Unavailable/DoNotFlash" 2 "Reserved" 1 "FastFlash" 0 "SlowFlash";
VAL_ 2566834692 FlashMalfuncIndicatorLamp_MTCU_Axle2 3 "Unavailable/DoNotFlash" 2 "Reserved" 1 "FastFlash" 0 "SlowFlash";
VAL_ 2355220570 Actual_Driving_direction_AVE_System 2 "Reverse" 1 "Forward" 0 "Neutral";
VAL_ 2355220570 Actual_Drive_mode 3 "Error" 2 "Regen" 1 "Driving" 0 "Stop";
VAL_ 2355220570 Wheel_Slippage_detection 14 "Error" 2 "Right Wheel Slippage Reduction active" 1 "Left Wheel Slippage Reduction active" 0 "No slippage Reduction";
VAL_ 2355220570 Average_EMotor_speed 65535 "sna" 65534 "error";
VAL_ 2355220570 Actual_torque_AX_System 4095 "sna" 4094 "Error";
VAL_ 2355220570 AX2_System_Ready 1 "Ready" 0 "Not Ready";
VAL_ 2355220570 Cooling_Afterrun_Request 1 "CL30 Afterrun request" 0 "None Afterrung request";
VAL_ 2355220570 EMotor_Overspeed 3 "sna" 2 "Error" 1 "Emotor Overspeed active" 0 "No Overspeed detected";
VAL_ 2355286106 DC_Current_Edrive_System 65535 "sna" 65534 "error";
VAL_ 2355286106 DC_Voltage_Edrive_System 4095 "sna" 4094 "Error";
VAL_ 2355286106 Maximum_torque_available 4095 "sna" 4094 "Error";
VAL_ 2355286106 Minimum_torque_available 4095 "sna" 4094 "Error";
VAL_ 2355351642 Temperature_EMotor_Axle1_1 255 "sna" 254 "Error";
VAL_ 2355351642 Temperature_Inverter_Axle1_1 255 "sna" 254 "Error";
VAL_ 2355351642 Temperature_EMotor_Axle1_2 255 "sna" 254 "Error";
VAL_ 2355351642 Temperature_Inverter_Axle1_2 255 "sna" 254 "Error";
VAL_ 2355417178 CurrentDcLink_Inverter_1 65535 "sna" 65534 "error";
VAL_ 2355417178 MotorSpeed_EMotor_1 65535 "sna" 65534 "error";
VAL_ 2355417178 Torque_EMotor_1 4095 "sna" 4094 "Error";
VAL_ 2355417178 DCL_Voltage_Inverter_1 4095 "sna" 4094 "Error";
VAL_ 2355482714 CurrentDcLink_Inverter_338_2 65535 "sna" 65534 "error";
VAL_ 2355482714 MotorSpeed_EMotor_338_2 65535 "sna" 65534 "error";
VAL_ 2355482714 Torque_EMotor_338_2 4095 "sna" 4094 "Error";
VAL_ 2355482714 DCL_Voltage_Inverter_338_2 4095 "sna" 4094 "Error";
VAL_ 2355548250 ECU_Cl15_State 3 "sna" 2 "Error" 1 "Cl15 On" 0 "CL15 Off";
VAL_ 2355548250 EV_Driveline_Shutdown_Indication 3 "sna" 2 "Error" 1 "Shutdown EV System started" 0 "No request";
VAL_ 2356007002 Derating_Flag 8 "DC Voltage" 4 "Speed rotor" 2 "Oil lubrication" 1 "DC and AC current" 1024 "Power Segmentation (if enabled)" 512 "coolant Derating" 256 "Overspeed Derating" 32 "Temperatur eOilPump" 16 "Temperatur E-Drive" 0 "No Derating";
VAL_ 2355220484 Actual_Driving_direction_AVE_System2 2 "Reverse" 1 "Forward" 0 "Neutral";
VAL_ 2355220484 Actual_Drive_mode2 3 "Error" 2 "Regen" 1 "Driving" 0 "Stop";
VAL_ 2355220484 Wheel_Slippage_detection2 14 "Error" 2 "Right Wheel Slippage Reduction active" 1 "Left Wheel Slippage Reduction active" 0 "No slippage Reduction";
VAL_ 2355220484 Average_EMotor_speed2 65535 "sna" 65534 "error";
VAL_ 2355220484 Actual_torque_AX_System2 4095 "sna" 4094 "Error";
VAL_ 2355220484 AX2_System_Ready2 1 "Ready" 0 "Not Ready";
VAL_ 2355220484 Cooling_Afterrun_Request2 1 "CL30 Afterrun request" 0 "None Afterrung request";
VAL_ 2355220484 EMotor_Overspeed2 3 "sna" 2 "Error" 1 "Emotor Overspeed active" 0 "No Overspeed detected";
VAL_ 2355286020 DC_Current_Edrive_System2 65535 "sna" 65534 "error";
VAL_ 2355286020 DC_Voltage_Edrive_System2 4095 "sna" 4094 "Error";
VAL_ 2355286020 Maximum_torque_available2 4095 "sna" 4094 "Error";
VAL_ 2355286020 Minimum_torque_available2 4095 "sna" 4094 "Error";
VAL_ 2355351556 Temperature_EMotor_Axle2_1 255 "sna" 254 "Error";
VAL_ 2355351556 Temperature_Inverter_Axle2_1 255 "sna" 254 "Error";
VAL_ 2355351556 Temperature_EMotor_Axle2_2 255 "sna" 254 "Error";
VAL_ 2355351556 Temperature_Inverter_Axle2_2 255 "sna" 254 "Error";
VAL_ 2355417092 CurrentDcLink_Inverter_2 65535 "sna" 65534 "error";
VAL_ 2355417092 MotorSpeed_EMotor_2 65535 "sna" 65534 "error";
VAL_ 2355417092 Torque_EMotor_2 4095 "sna" 4094 "Error";
VAL_ 2355417092 DCL_Voltage_Inverter_2 4095 "sna" 4094 "Error";
VAL_ 2355548164 ECU_Cl15_State2 3 "sna" 2 "Error" 1 "Cl15 On" 0 "CL15 Off";
VAL_ 2355548164 EV_Driveline_Shutdown_Indication2 3 "sna" 2 "Error" 1 "Shutdown EV System started" 0 "No request";
VAL_ 2356006916 Derating_Flag_Axle2 8 "DC Voltage" 4 "Speed rotor" 2 "Oil lubrication" 1 "DC and AC current" 1024 "Power Segmentation (if enabled)" 512 "coolant Derating" 256 "Overspeed Derating" 32 "Temperatur eOilPump" 16 "Temperatur E-Drive" 0 "No Derating";
VAL_ 2355613786 Trax1_STRATEGY_FAULT_LEVEL_ 3 "三级故障" 2 "二级故障" 1 "一级故障" 0 "无故障";
VAL_ 2355613786 Trax1_HI_INTERLOCK_FAULT 3 "无效" 2 "void" 1 "有故障" 0 "无故障";
VAL_ 2355613786 Inverter_1_OVERTEMP_MTCU6 3 "无效" 2 "void" 1 "有故障" 0 "无故障";
VAL_ 2355613786 EMotor_1_OVERTEMP_MTCU6 3 "无效" 2 "void" 1 "有故障" 0 "无故障";
VAL_ 2355613786 Inverter_2_OVERTEMP_MTCU6 3 "无效" 2 "void" 1 "有故障" 0 "无故障";
VAL_ 2355613786 EMotor_2_OVERTEMP_MTCU6 3 "无效" 2 "void" 1 "有故障" 0 "无故障";
VAL_ 2557005914 MCU1_NRF_PHASE_HW_OVERCUR 1 "异常" 0 "正常";
VAL_ 2557005914 MCU1_RF_UNBANLANCEDCUR 1 "异常" 0 "正常";
VAL_ 2557005914 MCU1_NRF_CUR_SENSORZERO_FAULT_U 1 "异常" 0 "正常";
VAL_ 2557005914 MCU1_NRF_CUR_SENSORZERO_FAULT_V 1 "异常" 0 "正常";
VAL_ 2557005914 MCU1_NRF_CUR_SENSORZERO_FAULT_W 1 "异常" 0 "正常";
VAL_ 2557005914 MCU1_NRF_PHASE_OVERCUR_U 1 "异常" 0 "正常";
VAL_ 2557005914 MCU1_NRF_PHASE_OVERCUR_V 1 "异常" 0 "正常";
VAL_ 2557005914 MCU1_NRF_PHASE_OVERCUR_W 1 "异常" 0 "正常";
VAL_ 2557005914 MCU1_RF_PHASE_OVERCUR_U 1 "异常" 0 "正常";
VAL_ 2557005914 MCU1_RF_PHASE_OVERCUR_V 1 "异常" 0 "正常";
VAL_ 2557005914 MCU1_RF_PHASE_OVERCUR_W 1 "异常" 0 "正常";
VAL_ 2557005914 MCU1_NRF_DC_SENSORZERO_FAULT 1 "异常" 0 "正常";
VAL_ 2557005914 MCU1_NRF_DC_OVERCUR 1 "异常" 0 "正常";
VAL_ 2557005914 MCU1_NRF_DCFEED_INTERRUPT 1 "异常" 0 "正常";
VAL_ 2557005914 MCU1_NRF_DC_HW_OVERVOL 1 "异常" 0 "正常";
VAL_ 2557005914 MCU1_NRF_DC_SW_OVERVOL 1 "异常" 0 "正常";
VAL_ 2557005914 MCU1_RF_DC_OVERVOL 1 "异常" 0 "正常";
VAL_ 2557005914 MCU1_LIF_DC_OVERVOL 1 "异常" 0 "正常";
VAL_ 2557005914 MCU1_NRF_DC_UNDERVOL 1 "异常" 0 "正常";
VAL_ 2557005914 MCU1_RF_DC_UNDERVOL 1 "异常" 0 "正常";
VAL_ 2557005914 MCU1_LIF_DC_UNDERVO 1 "异常" 0 "正常";
VAL_ 2557005914 MCU1_IGBT_TEMPSENSOR_FAULT 1 "异常" 0 "正常";
VAL_ 2557005914 MCU1_RF_INVTEMP_OVERTEMP 1 "异常" 0 "正常";
VAL_ 2557005914 MCU1_TORQUE_LOSTCONTROL 1 "异常" 0 "正常";
VAL_ 2557005914 MCU1_MOTOR_TEMSENSOR_FAULT 1 "异常" 0 "正常";
VAL_ 2557005914 MCU1_RF_MOTOR_OVERTEMP 1 "异常" 0 "正常";
VAL_ 2557005914 MCU1_NRF_RDC_FAULT 1 "异常" 0 "正常";
VAL_ 2557005914 MCU1_NRF_F_OVERSPEED 1 "异常" 0 "正常";
VAL_ 2557005914 MCU1_RF_F_OVERSPEED 1 "异常" 0 "正常";
VAL_ 2557005914 MCU1_LIF_R_OVERSPEED 1 "异常" 0 "正常";
VAL_ 2557005914 MCU1_NRF_IGBT_HWTEST_FAULT 1 "异常" 0 "正常";
VAL_ 2557005914 MCU1_NRF_IGBT_HWLV_VOL_FAULT 1 "异常" 0 "正常";
VAL_ 2557005914 MCU1_NRF_5V_SUPPLY_FAULT 1 "异常" 0 "正常";
VAL_ 2557005914 MCU1_LIF_MOTOR_OVERTEMP 1 "异常" 0 "正常";
VAL_ 2557005914 MCU1_NRF_LV_VOL_SUPPLY 1 "异常" 0 "正常";
VAL_ 2557005914 MCU1_LIF_INVTEMP_OVERTEMP 1 "异常" 0 "正常";
VAL_ 2557005914 MCU1_NRF_CAN_BUSOFF 1 "异常" 0 "正常";
VAL_ 2557005914 MCU1_RF_CAN_BUSOFF 1 "异常" 0 "正常";
VAL_ 2557005914 MCU1_RF_CAN_INTERNAL_FAULT 1 "异常" 0 "正常";
VAL_ 2557005914 MCU1_VCU_COM_LOST_ 1 "异常" 0 "正常";
VAL_ 2557005914 MCU1_EEPRROM_FAULT_ 1 "异常" 0 "正常";
VAL_ 2557005914 MCU1_LOCKED_ROTOR_FAULT 1 "异常" 0 "正常";
VAL_ 2557005914 MCU1_DISCHARGE_FAULT 1 "异常" 0 "正常";
VAL_ 2557005914 MCU1_SOFTWARE_INTERRUPT 1 "异常" 0 "正常";
VAL_ 2557005914 MCU1_POST_FAULT 1 "异常" 0 "正常";
VAL_ 2557005914 MCU1_MOTOR_SELFLEARNING_FAULT 1 "异常" 0 "正常";
VAL_ 2557005914 MCU1_DATA_OVERFLOW_FAULT 1 "异常" 0 "正常";
VAL_ 2557005914 MCU1_MCU_OVERLOAD_FAULT 1 "异常" 0 "正常";
VAL_ 2557005914 MCU1_MOTOR_OVERLOAD_FAULT 1 "异常" 0 "正常";
VAL_ 2557005914 MCU1_LIF_F_OVERSPEED 1 "异常" 0 "正常";
VAL_ 2557005914 MCU1_TjIGBT_OVER_TEMP 1 "异常" 0 "正常";
VAL_ 2557005914 MCU1_FS_Mw_faultiac_L3 1 "异常" 0 "正常";
VAL_ 2557005914 MCU1_FS_Mw_faultUdc_L3 1 "异常" 0 "正常";
VAL_ 2557005914 MCU1_FS_Mw_faultspeedcal_L3 1 "异常" 0 "正常";
VAL_ 2557005914 MCU1_FS_Mw_faulttorcomp_L3 1 "异常" 0 "正常";
VAL_ 2557005914 MCU1_FS_Mw_faultpwmpowerup_L3 1 "异常" 0 "正常";
VAL_ 2557005914 MCU1_FS_Mw_faultpwmpowerdown_L3 1 "异常" 0 "正常";
VAL_ 2557005914 MCU1_FS_Mw_faultpwm_L3 1 "异常" 0 "正常";
VAL_ 2557005914 MCU1_FS_Mw_faultacdischarge_L3 1 "异常" 0 "正常";
VAL_ 2557005914 MCU1_FS_Mw_faultpowermanager_L3 1 "异常" 0 "正常";
VAL_ 2557071450 MCU1_516_CURSENSOR_SHORT_FAULT__A 1 "异常" 0 "正常";
VAL_ 2557071450 MCU1_516_CURSENSOR_SHORT_FAULT__B 1 "异常" 0 "正常";
VAL_ 2557071450 MCU1_516_CURSENSOR_SHORT_FAULT__C 1 "异常" 0 "正常";
VAL_ 2557071450 MCU1_516_CURSENSOR_OPEN_FAULT__A 1 "异常" 0 "正常";
VAL_ 2557071450 MCU1_516_CURSENSOR_OPEN_FAULT__B 1 "异常" 0 "正常";
VAL_ 2557071450 MCU1_516_CURSENSOR_OPEN_FAULT__C 1 "异常" 0 "正常";
VAL_ 2557071450 MCU1_516_NRF_ANGLE_FAULT 1 "异常" 0 "正常";
VAL_ 2557071450 MCU1_516_RF_POWER_FAULT 1 "异常" 0 "正常";
VAL_ 2557071450 MCU1_516_NRF_PHASE_LOST_FAULT 1 "异常" 0 "正常";
VAL_ 2557071450 MCU1_516_NRF_HEATSINK_FAULT 1 "异常" 0 "正常";
VAL_ 2557071450 MCU1_516_RF_HEATSINK_FAULT 1 "异常" 0 "正常";
VAL_ 2557071450 MCU1_516_LIF_HEATSINK_FAULT 1 "异常" 0 "正常";
VAL_ 2557071450 MCU1_NRF_IGBT_B_HWTEST_FAULT 1 "异常" 0 "正常";
VAL_ 2557071450 MCU1_NRF_IGBT_C_HWTEST_FAULT 1 "异常" 0 "正常";
VAL_ 2557071450 MCU1_NRF_PHASE_B_HW_OVERCUR 1 "异常" 0 "正常";
VAL_ 2557071450 MCU1_NRF_PHASE_C_HW_OVERCUR 1 "异常" 0 "正常";
VAL_ 2557071450 MCU1_NRF_PHASE_OVERCUR 1 "异常" 0 "正常";
VAL_ 2557071450 MCU1_RF_PHASE_OVERCUR 1 "异常" 0 "正常";
VAL_ 2557071450 MCU1_LIF_PHASE_OVERCUR 1 "异常" 0 "正常";
VAL_ 2557071450 MCU1_LIF_PHASE_OVERCUR_U 1 "异常" 0 "正常";
VAL_ 2557071450 MCU1_LIF_PHASE_OVERCUR_V 1 "异常" 0 "正常";
VAL_ 2557071450 MCU1_LIF_PHASE_OVERCUR_W 1 "异常" 0 "正常";
VAL_ 2557071450 MCU1_MCU_OVERLOAD_FAULT_A 1 "异常" 0 "正常";
VAL_ 2557071450 MCU1_MCU_OVERLOAD_FAULT_B 1 "异常" 0 "正常";
VAL_ 2557071450 MCU1_MCU_OVERLOAD_FAULT_C 1 "异常" 0 "正常";
VAL_ 2557071450 MCU1_IGBT_TEMPSENSOR_SHORT_FAULT_B 1 "异常" 0 "正常";
VAL_ 2557071450 MCU1_IGBT_TEMPSENSOR_SHORT_FAULT_C 1 "异常" 0 "正常";
VAL_ 2557071450 MCU1_IGBT_TEMPSENSOR_OPEN_FAULT_A 1 "异常" 0 "正常";
VAL_ 2557071450 MCU1_IGBT_TEMPSENSOR_OPEN_FAULT_B 1 "异常" 0 "正常";
VAL_ 2557071450 MCU1_IGBT_TEMPSENSOR_OPEN_FAULT_C 1 "异常" 0 "正常";
VAL_ 2557071450 MCU1_NRF_INVTEMP_OVERTEMP_A 1 "异常" 0 "正常";
VAL_ 2557071450 MCU1_NRF_INVTEMP_OVERTEMP_B 1 "异常" 0 "正常";
VAL_ 2557071450 MCU1_NRF_INVTEMP_OVERTEMP_C 1 "异常" 0 "正常";
VAL_ 2557071450 MCU1_RF_INVTEMP_OVERTEMP_A 1 "异常" 0 "正常";
VAL_ 2557071450 MCU1_RF_INVTEMP_OVERTEMP_B 1 "异常" 0 "正常";
VAL_ 2557071450 MCU1_RF_INVTEMP_OVERTEMP_C 1 "异常" 0 "正常";
VAL_ 2557071450 MCU1_LIF_INVTEMP_OVERTEMP_A 1 "异常" 0 "正常";
VAL_ 2557071450 MCU1_LIF_INVTEMP_OVERTEMP_B 1 "异常" 0 "正常";
VAL_ 2557071450 MCU1_LIF_INVTEMP_OVERTEMP_C 1 "异常" 0 "正常";
VAL_ 2557071450 MCU1_MOTOR_TEMSENSOR_1_SHORT_FAULT 1 "异常" 0 "正常";
VAL_ 2557071450 MCU1_MOTOR_TEMSENSOR_1_OPEN_FAULT 1 "异常" 0 "正常";
VAL_ 2557071450 MCU1_MOTOR_TEMSENSOR_2_OPEN_FAULT 1 "异常" 0 "正常";
VAL_ 2557071450 MCU1_RF_R_OVERSPEED 1 "异常" 0 "正常";
VAL_ 2557071450 MCU1_NRF_LV_OVERVOL_SUPPLY 1 "异常" 0 "正常";
VAL_ 2557071450 MCU1_NRF_LV_BKP_OVERVOL_SUPPLY 1 "异常" 0 "正常";
VAL_ 2557071450 MCU1_NRF_LV_BKP_UNDERVOL_SUPPLY 1 "异常" 0 "正常";
VAL_ 2557071450 MCU1_NRF_DC_HW_OVERVOL_2 1 "异常" 0 "正常";
VAL_ 2557071450 MCU1_NRF_DC_HW_OVERVOL_1 1 "异常" 0 "正常";
VAL_ 2557071450 MCU1_NRF_DC_HW_HVIL 1 "异常" 0 "正常";
VAL_ 2557071450 MCU1_NRF_5V_DCCUR_SUPPLY_OVERVOL_FAULT 1 "异常" 0 "正常";
VAL_ 2557071450 MCU1_NRF_5V_DCCUR_SUPPLY_UNDERVOL_FAULT 1 "异常" 0 "正常";
VAL_ 2557071450 MCU1_NRF_5V_CUR_SUPPLY_OVERVOL_FAULT 1 "异常" 0 "正常";
VAL_ 2557071450 MCU1_NRF_5V_CUR_SUPPLY_UNDERVOL_FAULT 1 "异常" 0 "正常";
VAL_ 2557071450 MCU1_NRF_5V_DRV_SUPPLY_OVERVOL_FAULT 1 "异常" 0 "正常";
VAL_ 2557071450 MCU1_NRF_PCBTEMP_OVERTEMP 1 "异常" 0 "正常";
VAL_ 2557071450 MCU1_ACCLR_FAULT 1 "异常" 0 "正常";
VAL_ 2557136986 TCU_Power_Over_1st 1 "异常" 0 "正常";
VAL_ 2557136986 TCU_Power_Down_1st 1 "异常" 0 "正常";
VAL_ 2557136986 TCU_CPUNvm_Fault_1st 1 "异常" 0 "正常";
VAL_ 2557136986 TCU_CPURam_Fault_1st 1 "异常" 0 "正常";
VAL_ 2557136986 TCU_CPURom_Fault_1st 1 "异常" 0 "正常";
VAL_ 2557136986 TCU_Reset_Fault_1st 1 "异常" 0 "正常";
VAL_ 2557136986 TCU_System_Fault_1st 1 "异常" 0 "正常";
VAL_ 2557136986 TCU_HSD2AndPowerShort_1st 1 "异常" 0 "正常";
VAL_ 2557136986 TCU_HighPinShort_1st 1 "异常" 0 "正常";
VAL_ 2557136986 TCU_CAN1Disconnect_1st 1 "异常" 0 "正常";
VAL_ 2557136986 TCU_CAN2Disconnect_1st 1 "异常" 0 "正常";
VAL_ 2557136986 TCU_HSD1AndPowerShort_1st 1 "异常" 0 "正常";
VAL_ 2557136986 TCU_AccPdlLoss_1st 1 "异常" 0 "正常";
VAL_ 2557136986 TCU_AccPdlMessgLengthErr_1st 1 "异常" 0 "正常";
VAL_ 2557136986 TCU_AccPdlCheckSumCheckErr_1st 1 "异常" 0 "正常";
VAL_ 2557136986 TCU_AccPdlRollingCounterErr_1st 1 "异常" 0 "正常";
VAL_ 2557136986 TCU_AccPdlInvalidEnab_1st 1 "异常" 0 "正常";
VAL_ 2557136986 TCU_AccPdlEqualInvalidVal_1st 1 "异常" 0 "正常";
VAL_ 2557136986 TCU_TemSnsrOpen_1st 1 "异常" 0 "正常";
VAL_ 2557136986 TCU_TemSnsrShorttoPower_1st 1 "异常" 0 "正常";
VAL_ 2557136986 TCU_TemSnsrShorttoGround_1st 1 "异常" 0 "正常";
VAL_ 2557136986 TCU_OutSftSpdSnsrOpen_1st 1 "异常" 0 "正常";
VAL_ 2557136986 TCU_OutSftSpdShorttoPower_1st 1 "异常" 0 "正常";
VAL_ 2557136986 TCU_OutSftSpdShorttoGround_1st 1 "异常" 0 "正常";
VAL_ 2557136986 TCU_SlctGValStPCSG2_Open_1st 1 "异常" 0 "正常";
VAL_ 2557136986 TCU_SlctGValStPCSG2_ShorttoPower_1st 1 "异常" 0 "正常";
VAL_ 2557136986 TCU_SlctGValStPCSG2_ShorttoGround_1st 1 "异常" 0 "正常";
VAL_ 2557136986 TCU_SlctGValStPCSG2_OverLoad_1st 1 "异常" 0 "正常";
VAL_ 2557136986 TCU_SlctGValStPCSG2_UnderLoad_1st 1 "异常" 0 "正常";
VAL_ 2557136986 TCU_SlctGValStPCSG4_Open_1st 1 "异常" 0 "正常";
VAL_ 2557136986 TCU_SlctGValStPCSG4_ShorttoPower_1st 1 "异常" 0 "正常";
VAL_ 2557136986 TCU_SlctGValStPCSG4_ShorttoGround_1st 1 "异常" 0 "正常";
VAL_ 2557136986 TCU_SlctGValStPCSG4_OverLoad_1st 1 "异常" 0 "正常";
VAL_ 2557136986 TCU_SlctGValStPCSG4_UnderLoad_1st 1 "异常" 0 "正常";
VAL_ 2557136986 TCU_SlctGValStPCSS3_Open_1st 1 "异常" 0 "正常";
VAL_ 2557136986 TCU_SlctGValStPCSS3_ShorttoPower_1st 1 "异常" 0 "正常";
VAL_ 2557136986 TCU_SlctGValStPCSS3_ShorttoGround_1st 1 "异常" 0 "正常";
VAL_ 2557136986 TCU_SlctGValStPCSS3_OverLoad_1st 1 "异常" 0 "正常";
VAL_ 2557136986 TCU_SlctGValStPCSS3_UnderLoad_1st 1 "异常" 0 "正常";
VAL_ 2557136986 TCU_SlctGValStPCSS4_Open_1st 1 "异常" 0 "正常";
VAL_ 2557136986 TCU_SlctGValStPCSS4_ShorttoPower_1st 1 "异常" 0 "正常";
VAL_ 2557136986 TCU_SlctGValStPCSS4_ShorttoGround_1st 1 "异常" 0 "正常";
VAL_ 2557136986 TCU_SlctGValStPCSS4_OverLoad_1st 1 "异常" 0 "正常";
VAL_ 2557136986 TCU_SlctGValStPCSS4_UnderLoad_1st 1 "异常" 0 "正常";
VAL_ 2557136986 TCU_9VElectricity_OverHigh_1st 1 "异常" 0 "正常";
VAL_ 2557136986 TCU_9VElectricity_OverLow_1st 1 "异常" 0 "正常";
VAL_ 2557136986 TCU_9VElectricityAndPow_Short_1st 1 "异常" 0 "正常";
VAL_ 2557136986 TCU_9VElectricityAndGnd_Short_1st 1 "异常" 0 "正常";
VAL_ 2557136986 TCU_HSD1_Broken_1st 1 "异常" 0 "正常";
VAL_ 2557136986 TCU_HSD1AndGnd_Broken_1st 1 "异常" 0 "正常";
VAL_ 2557136986 TCU_HSD2_Broken_1st 1 "异常" 0 "正常";
VAL_ 2557136986 TCU_HSD2AndGnd_Broken_1st 1 "异常" 0 "正常";
VAL_ 2557136986 TCU_CAN1Node_Fault_1st 1 "异常" 0 "正常";
VAL_ 2557136986 TCU_CANBus_Silence_1st 1 "异常" 0 "正常";
VAL_ 2557136986 TCU_CAN2Node_Fault_1st 1 "异常" 0 "正常";
VAL_ 2557136986 TCU_PosSensorD_Broken_1st 1 "异常" 0 "正常";
VAL_ 2557136986 TCU_PosSensorDAndPow_Broken_1st 1 "异常" 0 "正常";
VAL_ 2557136986 TCU_PosSensorDAndGnd_Broken_1st 1 "异常" 0 "正常";
VAL_ 2557136986 TCU_PosSensorE_Broken_1st 1 "异常" 0 "正常";
VAL_ 2557136986 TCU_PosSensorEAndPow_Broken_1st 1 "异常" 0 "正常";
VAL_ 2557136986 TCU_PosSensorEAndGnd_Broken_1st 1 "异常" 0 "正常";
VAL_ 2557136986 TCU_PrssSenso_Broken_1st 1 "异常" 0 "正常";
VAL_ 2557136986 TCU_PrssSensoAndPow_Broken_1st 1 "异常" 0 "正常";
VAL_ 2557136986 TCU_PrssSensoAndGnd_Broken_1st 1 "异常" 0 "正常";
VAL_ 2557202522 TCU_5VElectricity_OverHigh_1st 1 "异常" 0 "正常";
VAL_ 2557202522 TCU_5VElectricity_OverLow_1st 1 "异常" 0 "正常";
VAL_ 2557202522 TCU_5VElectricityAndPow_Short_1st 1 "异常" 0 "正常";
VAL_ 2557202522 TCU_5VElectricityAndGnd_Short_1st 1 "异常" 0 "正常";
VAL_ 2557202522 TCU_VehSpd_Lost_1st 1 "异常" 0 "正常";
VAL_ 2557202522 TCU_VehSpdMessLength_Fault_1st 1 "异常" 0 "正常";
VAL_ 2557202522 TCU_VehSpdChecSum_Fault_1st 1 "异常" 0 "正常";
VAL_ 2557202522 TCU_VehSpd_InvalidFg_1st 1 "异常" 0 "正常";
VAL_ 2557202522 TCU_VehSpd_Invalid_1st 1 "异常" 0 "正常";
VAL_ 2557202522 TCU_OilTemp_level3_1st 1 "异常" 0 "正常";
VAL_ 2557202522 TCU_OilTemp_level4_1st 1 "异常" 0 "正常";
VAL_ 2557202522 TCU_ATFOilTemp_Low_1st 1 "异常" 0 "正常";
VAL_ 2557202522 TCU_ATFOilTemp_Hop_1st 1 "异常" 0 "正常";
VAL_ 2557202522 TCU_OptSftSpd_High_1st 1 "异常" 0 "正常";
VAL_ 2557202522 TCU_OptSftSpd_Hop_1st 1 "异常" 0 "正常";
VAL_ 2557202522 TCU_OptSftSpd_Zero_1st 1 "异常" 0 "正常";
VAL_ 2557202522 TCU_SftOG_Stuk_1st 1 "异常" 0 "正常";
VAL_ 2557202522 TCU_TqResponse_Failure_1st 1 "异常" 0 "正常";
VAL_ 2557202522 TCU_SftIG_Stuk_1st 1 "异常" 0 "正常";
VAL_ 2557202522 TCU_RollingCounter_Fault_1st 1 "异常" 0 "正常";
VAL_ 2557202522 TCU_PowOn_Failure_1st 1 "异常" 0 "正常";
VAL_ 2557202522 TCU_PowOff_Failure_1st 1 "异常" 0 "正常";
VAL_ 2557202522 TCU_OilTemp_level1_1st 1 "异常" 0 "正常";
VAL_ 2557202522 TCU_OilTemp_level2_1st 1 "异常" 0 "正常";
VAL_ 2566899802 Coolant_Request 4095 "sna" 4094 "Error";
VAL_ 2566899802 Coolant_flow_request 4095 "sna" 4094 "Error";
VAL_ 2566840666 Retarder_Type 255 "sna" 254 "Error";
VAL_ 2566840666 Retarder_Location 255 "sna" 254 "Error";
VAL_ 2566840666 Retarder_Speed_at_Idle_point1 65535 "sna" 65534 "error";
VAL_ 2566840666 RC_Percent_Torque_at_Idle_point1 255 "sna" 254 "Error";
VAL_ 2566840666 Maximum_Retarder_Speed_point2 65535 "sna" 65534 "error";
VAL_ 2566840666 RC_Percent_Torque_at_maximum_Speed_point2 255 "sna" 254 "Error";
VAL_ 2566840666 Retarder_Speed_at_point3 65535 "sna" 65534 "error";
VAL_ 2566840666 RC_Percent_Torque_at_point3 255 "sna" 254 "Error";
VAL_ 2566840666 Retarder_Speed_at_point4 65535 "sna" 65534 "error";
VAL_ 2566840666 RC_Percent_Torque_at_point4 255 "sna" 254 "Error";
VAL_ 2566840666 Retarder_Speed_at_peak_Torque_point5 65535 "sna" 65534 "error";
VAL_ 2566840666 Reference_Retarder_Torque 65535 "sna" 65534 "error";
VAL_ 2566840666 RC_Percent_Torque_at_point5 255 "sna" 254 "Error";
VAL_ 2355613700 Trax2_STRATEGY_FAULT_LEVEL_ 3 "三级故障" 2 "二级故障" 1 "一级故障" 0 "无故障";
VAL_ 2355613700 Trax2_HI_INTERLOCK_FAULT 3 "无效" 2 "void" 1 "有故障" 0 "无故障";
VAL_ 2355613700 Inverter_2_OVERTEMP_MTCU6_Axle2_1 3 "无效" 2 "void" 1 "有故障" 0 "无故障";
VAL_ 2355613700 EMotor_2_OVERTEMP_MTCU6_Axle2_1 3 "无效" 2 "void" 1 "有故障" 0 "无故障";
VAL_ 2355613700 Inverter_2_OVERTEMP_MTCU6_Axle2 3 "无效" 2 "void" 1 "有故障" 0 "无故障";
VAL_ 2355613700 EMotor_2_OVERTEMP_MTCU6_Axle2 3 "无效" 2 "void" 1 "有故障" 0 "无故障";
VAL_ 2557005828 MCU2_NRF_PHASE_HW_OVERCUR 1 "异常" 0 "正常";
VAL_ 2557005828 MCU2_RF_UNBANLANCEDCUR 1 "异常" 0 "正常";
VAL_ 2557005828 MCU2_NRF_CUR_SENSORZERO_FAULT_U 1 "异常" 0 "正常";
VAL_ 2557005828 MCU2_NRF_CUR_SENSORZERO_FAULT_V 1 "异常" 0 "正常";
VAL_ 2557005828 MCU2_NRF_CUR_SENSORZERO_FAULT_W 1 "异常" 0 "正常";
VAL_ 2557005828 MCU2_NRF_PHASE_OVERCUR_U 1 "异常" 0 "正常";
VAL_ 2557005828 MCU2_NRF_PHASE_OVERCUR_V 1 "异常" 0 "正常";
VAL_ 2557005828 MCU2_NRF_PHASE_OVERCUR_W 1 "异常" 0 "正常";
VAL_ 2557005828 MCU2_RF_PHASE_OVERCUR_U 1 "异常" 0 "正常";
VAL_ 2557005828 MCU2_RF_PHASE_OVERCUR_V 1 "异常" 0 "正常";
VAL_ 2557005828 MCU2_RF_PHASE_OVERCUR_W 1 "异常" 0 "正常";
VAL_ 2557005828 MCU2_NRF_DC_SENSORZERO_FAULT 1 "异常" 0 "正常";
VAL_ 2557005828 MCU2_NRF_DC_OVERCUR 1 "异常" 0 "正常";
VAL_ 2557005828 MCU2_NRF_DCFEED_INTERRUPT 1 "异常" 0 "正常";
VAL_ 2557005828 MCU2_NRF_DC_HW_OVERVOL 1 "异常" 0 "正常";
VAL_ 2557005828 MCU2_NRF_DC_SW_OVERVOL 1 "异常" 0 "正常";
VAL_ 2557005828 MCU2_RF_DC_OVERVOL 1 "异常" 0 "正常";
VAL_ 2557005828 MCU2_LIF_DC_OVERVOL 1 "异常" 0 "正常";
VAL_ 2557005828 MCU2_NRF_DC_UNDERVOL 1 "异常" 0 "正常";
VAL_ 2557005828 MCU2_RF_DC_UNDERVOL 1 "异常" 0 "正常";
VAL_ 2557005828 MCU2_LIF_DC_UNDERVO 1 "异常" 0 "正常";
VAL_ 2557005828 MCU2_IGBT_TEMPSENSOR_FAULT 1 "异常" 0 "正常";
VAL_ 2557005828 MCU2_RF_INVTEMP_OVERTEMP 1 "异常" 0 "正常";
VAL_ 2557005828 MCU2_TORQUE_LOSTCONTROL 1 "异常" 0 "正常";
VAL_ 2557005828 MCU2_MOTOR_TEMSENSOR_FAULT 1 "异常" 0 "正常";
VAL_ 2557005828 MCU2_RF_MOTOR_OVERTEMP 1 "异常" 0 "正常";
VAL_ 2557005828 MCU2_NRF_RDC_FAULT 1 "异常" 0 "正常";
VAL_ 2557005828 MCU2_NRF_F_OVERSPEED 1 "异常" 0 "正常";
VAL_ 2557005828 MCU2_RF_F_OVERSPEED 1 "异常" 0 "正常";
VAL_ 2557005828 MCU2_LIF_R_OVERSPEED 1 "异常" 0 "正常";
VAL_ 2557005828 MCU2_NRF_IGBT_HWTEST_FAULT 1 "异常" 0 "正常";
VAL_ 2557005828 MCU2_NRF_IGBT_HWLV_VOL_FAULT 1 "异常" 0 "正常";
VAL_ 2557005828 MCU2_NRF_5V_SUPPLY_FAULT 1 "异常" 0 "正常";
VAL_ 2557005828 MCU2_LIF_MOTOR_OVERTEMP 1 "异常" 0 "正常";
VAL_ 2557005828 MCU2_NRF_LV_VOL_SUPPLY 1 "异常" 0 "正常";
VAL_ 2557005828 MCU2_LIF_INVTEMP_OVERTEMP 1 "异常" 0 "正常";
VAL_ 2557005828 MCU2_NRF_CAN_BUSOFF 1 "异常" 0 "正常";
VAL_ 2557005828 MCU2_RF_CAN_BUSOFF 1 "异常" 0 "正常";
VAL_ 2557005828 MCU2_RF_CAN_INTERNAL_FAULT 1 "异常" 0 "正常";
VAL_ 2557005828 MCU2_VCU_COM_LOST_ 1 "异常" 0 "正常";
VAL_ 2557005828 MCU2_EEPRROM_FAULT_ 1 "异常" 0 "正常";
VAL_ 2557005828 MCU2_LOCKED_ROTOR_FAULT 1 "异常" 0 "正常";
VAL_ 2557005828 MCU2_DISCHARGE_FAULT 1 "异常" 0 "正常";
VAL_ 2557005828 MCU2_SOFTWARE_INTERRUPT 1 "异常" 0 "正常";
VAL_ 2557005828 MCU2_POST_FAULT 1 "异常" 0 "正常";
VAL_ 2557005828 MCU2_MOTOR_SELFLEARNING_FAULT 1 "异常" 0 "正常";
VAL_ 2557005828 MCU2_DATA_OVERFLOW_FAULT 1 "异常" 0 "正常";
VAL_ 2557005828 MCU2_MCU_OVERLOAD_FAULT 1 "异常" 0 "正常";
VAL_ 2557005828 MCU2_MOTOR_OVERLOAD_FAULT 1 "异常" 0 "正常";
VAL_ 2557005828 MCU2_LIF_F_OVERSPEED 1 "异常" 0 "正常";
VAL_ 2557005828 MCU2_TjIGBT_OVER_TEMP 1 "异常" 0 "正常";
VAL_ 2557005828 MCU2_FS_Mw_faultiac_L3 1 "异常" 0 "正常";
VAL_ 2557005828 MCU2_FS_Mw_faultUdc_L3 1 "异常" 0 "正常";
VAL_ 2557005828 MCU2_FS_Mw_faultspeedcal_L3 1 "异常" 0 "正常";
VAL_ 2557005828 MCU2_FS_Mw_faulttorcomp_L3 1 "异常" 0 "正常";
VAL_ 2557005828 MCU2_FS_Mw_faultpwmpowerup_L3 1 "异常" 0 "正常";
VAL_ 2557005828 MCU2_FS_Mw_faultpwmpowerdown_L3 1 "异常" 0 "正常";
VAL_ 2557005828 MCU2_FS_Mw_faultpwm_L3 1 "异常" 0 "正常";
VAL_ 2557005828 MCU2_FS_Mw_faultacdischarge_L3 1 "异常" 0 "正常";
VAL_ 2557005828 MCU2_FS_Mw_faultpowermanager_L3 1 "异常" 0 "正常";
VAL_ 2557071364 MCU2_516_CURSENSOR_SHORT_FAULT__A 1 "异常" 0 "正常";
VAL_ 2557071364 MCU2_516_CURSENSOR_SHORT_FAULT__B 1 "异常" 0 "正常";
VAL_ 2557071364 MCU2_516_CURSENSOR_SHORT_FAULT__C 1 "异常" 0 "正常";
VAL_ 2557071364 MCU2_516_CURSENSOR_OPEN_FAULT__A 1 "异常" 0 "正常";
VAL_ 2557071364 MCU2_516_CURSENSOR_OPEN_FAULT__B 1 "异常" 0 "正常";
VAL_ 2557071364 MCU2_516_CURSENSOR_OPEN_FAULT__C 1 "异常" 0 "正常";
VAL_ 2557071364 MCU2_516_NRF_ANGLE_FAULT 1 "异常" 0 "正常";
VAL_ 2557071364 MCU2_516_RF_POWER_FAULT 1 "异常" 0 "正常";
VAL_ 2557071364 MCU2_516_NRF_PHASE_LOST_FAULT 1 "异常" 0 "正常";
VAL_ 2557071364 MCU2_516_NRF_HEATSINK_FAULT 1 "异常" 0 "正常";
VAL_ 2557071364 MCU2_516_RF_HEATSINK_FAULT 1 "异常" 0 "正常";
VAL_ 2557071364 MCU2_516_LIF_HEATSINK_FAULT 1 "异常" 0 "正常";
VAL_ 2557071364 MCU2_NRF_IGBT_B_HWTEST_FAULT 1 "异常" 0 "正常";
VAL_ 2557071364 MCU2_NRF_IGBT_C_HWTEST_FAULT 1 "异常" 0 "正常";
VAL_ 2557071364 MCU2_NRF_PHASE_B_HW_OVERCUR 1 "异常" 0 "正常";
VAL_ 2557071364 MCU2_NRF_PHASE_C_HW_OVERCUR 1 "异常" 0 "正常";
VAL_ 2557071364 MCU2_NRF_PHASE_OVERCUR 1 "异常" 0 "正常";
VAL_ 2557071364 MCU2_RF_PHASE_OVERCUR 1 "异常" 0 "正常";
VAL_ 2557071364 MCU2_LIF_PHASE_OVERCUR 1 "异常" 0 "正常";
VAL_ 2557071364 MCU2_LIF_PHASE_OVERCUR_U 1 "异常" 0 "正常";
VAL_ 2557071364 MCU2_LIF_PHASE_OVERCUR_V 1 "异常" 0 "正常";
VAL_ 2557071364 MCU2_LIF_PHASE_OVERCUR_W 1 "异常" 0 "正常";
VAL_ 2557071364 MCU2_MCU_OVERLOAD_FAULT_A 1 "异常" 0 "正常";
VAL_ 2557071364 MCU2_MCU_OVERLOAD_FAULT_B 1 "异常" 0 "正常";
VAL_ 2557071364 MCU2_MCU_OVERLOAD_FAULT_C 1 "异常" 0 "正常";
VAL_ 2557071364 MCU2_IGBT_TEMPSENSOR_SHORT_FAULT_B 1 "异常" 0 "正常";
VAL_ 2557071364 MCU2_IGBT_TEMPSENSOR_SHORT_FAULT_C 1 "异常" 0 "正常";
VAL_ 2557071364 MCU2_IGBT_TEMPSENSOR_OPEN_FAULT_A 1 "异常" 0 "正常";
VAL_ 2557071364 MCU2_IGBT_TEMPSENSOR_OPEN_FAULT_B 1 "异常" 0 "正常";
VAL_ 2557071364 MCU2_IGBT_TEMPSENSOR_OPEN_FAULT_C 1 "异常" 0 "正常";
VAL_ 2557071364 MCU2_NRF_INVTEMP_OVERTEMP_A 1 "异常" 0 "正常";
VAL_ 2557071364 MCU2_NRF_INVTEMP_OVERTEMP_B 1 "异常" 0 "正常";
VAL_ 2557071364 MCU2_NRF_INVTEMP_OVERTEMP_C 1 "异常" 0 "正常";
VAL_ 2557071364 MCU2_RF_INVTEMP_OVERTEMP_A 1 "异常" 0 "正常";
VAL_ 2557071364 MCU2_RF_INVTEMP_OVERTEMP_B 1 "异常" 0 "正常";
VAL_ 2557071364 MCU2_RF_INVTEMP_OVERTEMP_C 1 "异常" 0 "正常";
VAL_ 2557071364 MCU2_LIF_INVTEMP_OVERTEMP_A 1 "异常" 0 "正常";
VAL_ 2557071364 MCU2_LIF_INVTEMP_OVERTEMP_B 1 "异常" 0 "正常";
VAL_ 2557071364 MCU2_LIF_INVTEMP_OVERTEMP_C 1 "异常" 0 "正常";
VAL_ 2557071364 MCU2_MOTOR_TEMSENSOR_1_SHORT_FAULT 1 "异常" 0 "正常";
VAL_ 2557071364 MCU2_MOTOR_TEMSENSOR_1_OPEN_FAULT 1 "异常" 0 "正常";
VAL_ 2557071364 MCU2_MOTOR_TEMSENSOR_2_OPEN_FAULT 1 "异常" 0 "正常";
VAL_ 2557071364 MCU2_RF_R_OVERSPEED 1 "异常" 0 "正常";
VAL_ 2557071364 MCU2_NRF_LV_OVERVOL_SUPPLY 1 "异常" 0 "正常";
VAL_ 2557071364 MCU2_NRF_LV_BKP_OVERVOL_SUPPLY 1 "异常" 0 "正常";
VAL_ 2557071364 MCU2_NRF_LV_BKP_UNDERVOL_SUPPLY 1 "异常" 0 "正常";
VAL_ 2557071364 MCU2_NRF_DC_HW_OVERVOL_2 1 "异常" 0 "正常";
VAL_ 2557071364 MCU2_NRF_DC_HW_OVERVOL_1 1 "异常" 0 "正常";
VAL_ 2557071364 MCU2_NRF_DC_HW_HVIL 1 "异常" 0 "正常";
VAL_ 2557071364 MCU2_NRF_5V_DCCUR_SUPPLY_OVERVOL_FAULT 1 "异常" 0 "正常";
VAL_ 2557071364 MCU2_NRF_5V_DCCUR_SUPPLY_UNDERVOL_FAULT 1 "异常" 0 "正常";
VAL_ 2557071364 MCU2_NRF_5V_CUR_SUPPLY_OVERVOL_FAULT 1 "异常" 0 "正常";
VAL_ 2557071364 MCU2_NRF_5V_CUR_SUPPLY_UNDERVOL_FAULT 1 "异常" 0 "正常";
VAL_ 2557071364 MCU2_NRF_5V_DRV_SUPPLY_OVERVOL_FAULT 1 "异常" 0 "正常";
VAL_ 2557071364 MCU2_NRF_PCBTEMP_OVERTEMP 1 "异常" 0 "正常";
VAL_ 2557071364 MCU2_ACCLR_FAULT 1 "异常" 0 "正常";
VAL_ 2557136900 TCU_Power_Over_2nd 1 "异常" 0 "正常";
VAL_ 2557136900 TCU_Power_Down_2nd 1 "异常" 0 "正常";
VAL_ 2557136900 TCU_CPUNvm_Fault_2nd 1 "异常" 0 "正常";
VAL_ 2557136900 TCU_CPURam_Fault_2nd 1 "异常" 0 "正常";
VAL_ 2557136900 TCU_CPURom_Fault_2nd 1 "异常" 0 "正常";
VAL_ 2557136900 TCU_Reset_Fault_2nd 1 "异常" 0 "正常";
VAL_ 2557136900 TCU_System_Fault_2nd 1 "异常" 0 "正常";
VAL_ 2557136900 TCU_HSD2AndPowerShort_2nd 1 "异常" 0 "正常";
VAL_ 2557136900 TCU_HighPinShort_2nd 1 "异常" 0 "正常";
VAL_ 2557136900 TCU_CAN1Disconnect_2nd 1 "异常" 0 "正常";
VAL_ 2557136900 TCU_CAN2Disconnect_2nd 1 "异常" 0 "正常";
VAL_ 2557136900 TCU_HSD1AndPowerShort_2nd 1 "异常" 0 "正常";
VAL_ 2557136900 TCU_AccPdlLoss_2nd 1 "异常" 0 "正常";
VAL_ 2557136900 TCU_AccPdlMessgLengthErr_2nd 1 "异常" 0 "正常";
VAL_ 2557136900 TCU_AccPdlCheckSumCheckErr_2nd 1 "异常" 0 "正常";
VAL_ 2557136900 TCU_AccPdlRollingCounterErr_2nd 1 "异常" 0 "正常";
VAL_ 2557136900 TCU_AccPdlInvalidEnab_2nd 1 "异常" 0 "正常";
VAL_ 2557136900 TCU_AccPdlEqualInvalidVal_2nd 1 "异常" 0 "正常";
VAL_ 2557136900 TCU_TemSnsrOpen_2nd 1 "异常" 0 "正常";
VAL_ 2557136900 TCU_TemSnsrShorttoPower_2nd 1 "异常" 0 "正常";
VAL_ 2557136900 TCU_TemSnsrShorttoGround_2nd 1 "异常" 0 "正常";
VAL_ 2557136900 TCU_OutSftSpdSnsrOpen_2nd 1 "异常" 0 "正常";
VAL_ 2557136900 TCU_OutSftSpdShorttoPower_2nd 1 "异常" 0 "正常";
VAL_ 2557136900 TCU_OutSftSpdShorttoGround_2nd 1 "异常" 0 "正常";
VAL_ 2557136900 TCU_SlctGValStPCSG2_Open_2nd 1 "异常" 0 "正常";
VAL_ 2557136900 TCU_SlctGValStPCSG2_ShorttoPower_2nd 1 "异常" 0 "正常";
VAL_ 2557136900 TCU_SlctGValStPCSG2_ShorttoGround_2nd 1 "异常" 0 "正常";
VAL_ 2557136900 TCU_SlctGValStPCSG2_OverLoad_2nd 1 "异常" 0 "正常";
VAL_ 2557136900 TCU_SlctGValStPCSG2_UnderLoad_2nd 1 "异常" 0 "正常";
VAL_ 2557136900 TCU_SlctGValStPCSG4_Open_2nd 1 "异常" 0 "正常";
VAL_ 2557136900 TCU_SlctGValStPCSG4_ShorttoPower_2nd 1 "异常" 0 "正常";
VAL_ 2557136900 TCU_SlctGValStPCSG4_ShorttoGround_2nd 1 "异常" 0 "正常";
VAL_ 2557136900 TCU_SlctGValStPCSG4_OverLoad_2nd 1 "异常" 0 "正常";
VAL_ 2557136900 TCU_SlctGValStPCSG4_UnderLoad_2nd 1 "异常" 0 "正常";
VAL_ 2557136900 TCU_SlctGValStPCSS3_Open_2nd 1 "异常" 0 "正常";
VAL_ 2557136900 TCU_SlctGValStPCSS3_ShorttoPower_2nd 1 "异常" 0 "正常";
VAL_ 2557136900 TCU_SlctGValStPCSS3_ShorttoGround_2nd 1 "异常" 0 "正常";
VAL_ 2557136900 TCU_SlctGValStPCSS3_OverLoad_2nd 1 "异常" 0 "正常";
VAL_ 2557136900 TCU_SlctGValStPCSS3_UnderLoad_2nd 1 "异常" 0 "正常";
VAL_ 2557136900 TCU_SlctGValStPCSS4_Open_2nd 1 "异常" 0 "正常";
VAL_ 2557136900 TCU_SlctGValStPCSS4_ShorttoPower_2nd 1 "异常" 0 "正常";
VAL_ 2557136900 TCU_SlctGValStPCSS4_ShorttoGround_2nd 1 "异常" 0 "正常";
VAL_ 2557136900 TCU_SlctGValStPCSS4_OverLoad_2nd 1 "异常" 0 "正常";
VAL_ 2557136900 TCU_SlctGValStPCSS4_UnderLoad_2nd 1 "异常" 0 "正常";
VAL_ 2557136900 TCU_9VElectricity_OverHigh_2nd 1 "异常" 0 "正常";
VAL_ 2557136900 TCU_9VElectricity_OverLow_2nd 1 "异常" 0 "正常";
VAL_ 2557136900 TCU_9VElectricityAndPow_Short_2nd 1 "异常" 0 "正常";
VAL_ 2557136900 TCU_9VElectricityAndGnd_Short_2nd 1 "异常" 0 "正常";
VAL_ 2557136900 TCU_HSD1_Broken_2nd 1 "异常" 0 "正常";
VAL_ 2557136900 TCU_HSD1AndGnd_Broken_2nd 1 "异常" 0 "正常";
VAL_ 2557136900 TCU_HSD2_Broken_2nd 1 "异常" 0 "正常";
VAL_ 2557136900 TCU_HSD2AndGnd_Broken_2nd 1 "异常" 0 "正常";
VAL_ 2557136900 TCU_CAN1Node_Fault_2nd 1 "异常" 0 "正常";
VAL_ 2557136900 TCU_CANBus_Silence_2nd 1 "异常" 0 "正常";
VAL_ 2557136900 TCU_CAN2Node_Fault_2nd 1 "异常" 0 "正常";
VAL_ 2557136900 TCU_PosSensorD_Broken_2nd 1 "异常" 0 "正常";
VAL_ 2557136900 TCU_PosSensorDAndPow_Broken_2nd 1 "异常" 0 "正常";
VAL_ 2557136900 TCU_PosSensorDAndGnd_Broken_2nd 1 "异常" 0 "正常";
VAL_ 2557136900 TCU_PosSensorE_Broken_2nd 1 "异常" 0 "正常";
VAL_ 2557136900 TCU_PosSensorEAndPow_Broken_2nd 1 "异常" 0 "正常";
VAL_ 2557136900 TCU_PosSensorEAndGnd_Broken_2nd 1 "异常" 0 "正常";
VAL_ 2557136900 TCU_PrssSenso_Broken_2nd 1 "异常" 0 "正常";
VAL_ 2557136900 TCU_PrssSensoAndPow_Broken_2nd 1 "异常" 0 "正常";
VAL_ 2557136900 TCU_PrssSensoAndGnd_Broken_2nd 1 "异常" 0 "正常";
VAL_ 2557202436 TCU_5VElectricity_OverHigh_2nd 1 "异常" 0 "正常";
VAL_ 2557202436 TCU_5VElectricity_OverLow_2nd 1 "异常" 0 "正常";
VAL_ 2557202436 TCU_5VElectricityAndPow_Short_2nd 1 "异常" 0 "正常";
VAL_ 2557202436 TCU_5VElectricityAndGnd_Short_2nd 1 "异常" 0 "正常";
VAL_ 2557202436 TCU_VehSpd_Lost_2nd 1 "异常" 0 "正常";
VAL_ 2557202436 TCU_VehSpdMessLength_Fault_2nd 1 "异常" 0 "正常";
VAL_ 2557202436 TCU_VehSpdChecSum_Fault_2nd 1 "异常" 0 "正常";
VAL_ 2557202436 TCU_VehSpd_InvalidFg_2nd 1 "异常" 0 "正常";
VAL_ 2557202436 TCU_VehSpd_Invalid_2nd 1 "异常" 0 "正常";
VAL_ 2557202436 TCU_OilTemp_level3_2nd 1 "异常" 0 "正常";
VAL_ 2557202436 TCU_OilTemp_level4_2nd 1 "异常" 0 "正常";
VAL_ 2557202436 TCU_ATFOilTemp_Low_2nd 1 "异常" 0 "正常";
VAL_ 2557202436 TCU_ATFOilTemp_Hop_2nd 1 "异常" 0 "正常";
VAL_ 2557202436 TCU_OptSftSpd_High_2nd 1 "异常" 0 "正常";
VAL_ 2557202436 TCU_OptSftSpd_Hop_2nd 1 "异常" 0 "正常";
VAL_ 2557202436 TCU_OptSftSpd_Zero_2nd 1 "异常" 0 "正常";
VAL_ 2557202436 TCU_SftOG_Stuk_2nd 1 "异常" 0 "正常";
VAL_ 2557202436 TCU_TqResponse_Failure_2nd 1 "异常" 0 "正常";
VAL_ 2557202436 TCU_SftIG_Stuk_2nd 1 "异常" 0 "正常";
VAL_ 2557202436 TCU_RollingCounter_Fault_2nd 1 "异常" 0 "正常";
VAL_ 2557202436 TCU_PowOn_Failure_2nd 1 "异常" 0 "正常";
VAL_ 2557202436 TCU_PowOff_Failure_2nd 1 "异常" 0 "正常";
VAL_ 2557202436 TCU_OilTemp_level1_2nd 1 "异常" 0 "正常";
VAL_ 2557202436 TCU_OilTemp_level2_2nd 1 "异常" 0 "正常";
VAL_ 2566899716 Coolant_Request_Axle2 4095 "sna" 4094 "Error";
VAL_ 2566899716 Coolant_flow_request_Axle2 4095 "sna" 4094 "Error";
VAL_ 2566840580 Retarder_Type_Axle2 255 "sna" 254 "Error";
VAL_ 2566840580 Retarder_Location_Axle2 255 "sna" 254 "Error";
VAL_ 2566840580 Retarder_Speed_at_Idle_point1_Axle2 65535 "sna" 65534 "error";
VAL_ 2566840580 RC_Percent_Torque_at_Idle_point1_Axle2 255 "sna" 254 "Error";
VAL_ 2566840580 Maximum_Retarder_Speed_point2_Axle2 65535 "sna" 65534 "error";
VAL_ 2566840580 RC_Percent_Torque_at_maximum_Speed_point2_Axle2 255 "sna" 254 "Error";
VAL_ 2566840580 Retarder_Speed_at_point3_Axle2 65535 "sna" 65534 "error";
VAL_ 2566840580 RC_Percent_Torque_at_point3_Axle2 255 "sna" 254 "Error";
VAL_ 2566840580 Retarder_Speed_at_point4_Axle2 65535 "sna" 65534 "error";
VAL_ 2566840580 RC_Percent_Torque_at_point4_Axle2 255 "sna" 254 "Error";
VAL_ 2566840580 Retarder_Speed_at_peak_Torque_point5_Axle2 65535 "sna" 65534 "error";
VAL_ 2566840580 Reference_Retarder_Torque_Axle2 65535 "sna" 65534 "error";
VAL_ 2566840580 RC_Percent_Torque_at_point5_Axle2 255 "sna" 254 "Error";
VAL_ 2566841178 EMotor_speed_at_idle_Point1 65535 "sna" 65534 "error";
VAL_ 2566841178 EC_Percent_Torque_at_Idle_Point1 255 "sna" 254 "Error";
VAL_ 2566841178 EMotor_Speed_at_Point2 65535 "sna" 65534 "error";
VAL_ 2566841178 EC_Percent_Torque_at_Point2 255 "sna" 254 "Error";
VAL_ 2566841178 EMotor_Speed_at_Point3 65535 "sna" 65534 "error";
VAL_ 2566841178 EC_Percent_Torque_at_Point3 255 "sna" 254 "Error";
VAL_ 2566841178 EMotor_Speed_at_Point4 65535 "sna" 65534 "error";
VAL_ 2566841178 EC_Percent_Torque_at_Point4 255 "sna" 254 "Error";
VAL_ 2566841178 EMotor_Speed_at_Point5 65535 "sna" 65534 "error";
VAL_ 2566841178 EC_Percent_Torque_at_Point5 255 "sna" 254 "Error";
VAL_ 2566841178 EMotor_reference_torque 65535 "sna" 65534 "error";
VAL_ 2566841092 EMotor_speed_at_idle_Point1_Axle2 65535 "sna" 65534 "error";
VAL_ 2566841092 EC_Percent_Torque_at_Idle_Point1_Axle2 255 "sna" 254 "Error";
VAL_ 2566841092 EMotor_Speed_at_Point2_Axle2 65535 "sna" 65534 "error";
VAL_ 2566841092 EC_Percent_Torque_at_Point2_Axle2 255 "sna" 254 "Error";
VAL_ 2566841092 EMotor_Speed_at_Point3_Axle2 65535 "sna" 65534 "error";
VAL_ 2566841092 EC_Percent_Torque_at_Point3_Axle2 255 "sna" 254 "Error";
VAL_ 2566841092 EMotor_Speed_at_Point4_Axle2 65535 "sna" 65534 "error";
VAL_ 2566841092 EC_Percent_Torque_at_Point4_Axle2 255 "sna" 254 "Error";
VAL_ 2566841092 EMotor_Speed_at_Point5_Axle2 65535 "sna" 65534 "error";
VAL_ 2566841092 EC_Percent_Torque_at_Point5_Axle2 255 "sna" 254 "Error";
VAL_ 2566841092 EMotor_reference_torque_Axle2 65535 "sna" 65534 "error";
VAL_ 2364539994 EMotor_TrqRet_Mode 8 "转矩限制";
VAL_ 2364539994 Drivers_Demand_EMotor_Percent_Torque 255 "sna" 254 "Error";
VAL_ 2364539994 E_Actual_EMotor_Percent_Torque 255 "sna" 254 "Error";
VAL_ 2364539994 EMotor_Speed 65535 "sna" 65534 "error";
VAL_ 2364539994 Source_Adress_of_Ctrl_Device 255 "sna" 254 "Error";
VAL_ 2364539738 Actual_Maximum_Available_Engine_Percent_Torque 255 "sna" 254 "Error";
VAL_ 2566840154 Nominal_FrictionPercent_Torque 255 "sna" 254 "Error";
VAL_ 2565865562 EMotor_Torque_Mode 8 "转矩限制";
VAL_ 2565865562 Recuperation_Enable_Switch 1 "active" 0 "not active";
VAL_ 2565865562 R_Actual_EMotor_Percent_Torque 255 "sna" 254 "Error";
VAL_ 2565865562 Intended_EMotor_Percent_Torque 255 "sna" 254 "Error";
VAL_ 2565865562 Source_Adress_of_Crtl_Device 255 "sna" 254 "Error";
VAL_ 2565865562 Driver_Demand_EMotor_Percent_Torque 255 "sna" 254 "Error";
VAL_ 2565865562 Actual_Maximum_Available_EMotor_Recuperation_Torque 255 "sna" 254 "Error";
VAL_ 2566856794 Actual_EMotor_Ouput_Shaft_Speed_EMRC1 255 "sna" 254 "Error";
VAL_ 2566856794 Drivers_Demand_EMotor_Retarder_Percent_Torque_EMRC1 255 "sna" 254 "Error";
VAL_ 2566856794 Source_Adress_of_Ctrl_Device_EMRC1 255 "sna" 254 "Error";
VAL_ 2566856794 Intended_EMotor_Percent_Torque_EMRC1 255 "sna" 254 "Error";
VAL_ 2566856794 Actual_Maximum_Available_EMotor_Recuperation_Torque_EMRC1 255 "sna" 254 "Error";
VAL_ 2364539908 EMotor_TrqRet_Mode_Axle2 8 "转矩限制";
VAL_ 2364539908 Drivers_Demand_EMotor_Percent_Torque_Axle2 255 "sna" 254 "Error";
VAL_ 2364539908 E_Actual_EMotor_Percent_Torque_Axle2 255 "sna" 254 "Error";
VAL_ 2364539908 EMotor_Speed_Axle2 65535 "sna" 65534 "error";
VAL_ 2364539908 Source_Adress_of_Ctrl_Device_Axle2 255 "sna" 254 "Error";
VAL_ 2364539652 Actual_Maximum_Available_Engine_Percent_Torque_Axle2 255 "sna" 254 "Error";
VAL_ 2566840068 Nominal_FrictionPercent_Torque_Axle2 255 "sna" 254 "Error";
VAL_ 2565865476 EMotor_Torque_Mode_Axle2 8 "转矩限制";
VAL_ 2565865476 Recuperation_Enable_Switch_Axle2 1 "active" 0 "not active";
VAL_ 2565865476 R_Actual_EMotor_Percent_Torque_Axle2 255 "sna" 254 "Error";
VAL_ 2565865476 Intended_EMotor_Percent_Torque_Axle2 255 "sna" 254 "Error";
VAL_ 2565865476 Source_Adress_of_Crtl_Device_Axle2 255 "sna" 254 "Error";
VAL_ 2565865476 Driver_Demand_EMotor_Percent_Torque_Axle2 255 "sna" 254 "Error";
VAL_ 2565865476 Actual_Maximum_Available_EMotor_Recuperation_Torque_Axle2 255 "sna" 254 "Error";
VAL_ 2566856708 Actual_EMotor_Ouput_Shaft_Speed_EMRC1_Axle2 255 "sna" 254 "Error";
VAL_ 2566856708 Drivers_Demand_EMotor_Retarder_Percent_Torque_EMRC1_Axle2 255 "sna" 254 "Error";
VAL_ 2566856708 Source_Adress_of_Ctrl_Device_EMRC1_Axle2 255 "sna" 254 "Error";
VAL_ 2566856708 Intended_EMotor_Percent_Torque_EMRC1_Axle2 255 "sna" 254 "Error";
VAL_ 2566856708 Actual_Maximum_Available_EMotor_Recuperation_Torque_EMRC1_Axle2 255 "sna" 254 "Error";
VAL_ 2565866074 Driveline_Engaged 3 "Not available" 2 "Error" 1 "Driveline engaged" 0 "Driveline disengaged";
VAL_ 2565866074 Shift_In_Progress 3 "Not available" 2 "Error" 1 "Shift in process" 0 "Shift is not in process";
VAL_ 2565866074 ETC_EMotor_Speed 65535 "sna" 65534 "error";
VAL_ 2565866842 Transmission_Selected_Gear 127 "D2" 126 "D1" 125 "N" 124 "R1" 123 "R2" 122 "R3" 121 "R4" 120 "R5" 130 "D5" 129 "D4" 128 "D3";
VAL_ 2565866842 Transmission_Current_Gear 127 "D2" 126 "D1" 125 "N" 124 "R1" 123 "R2" 122 "R3" 121 "R4" 120 "R5" 130 "D5" 129 "D4" 128 "D3";
VAL_ 2566802010 Transmission_Ready_for_Brake_Release 3 "Not available" 2 "Error" 1 "Transmission Ready for Brake Release" 0 "Transmission Not Ready for Brake Release";
VAL_ 2566840922 Number_of_Reverse_Gear_Ratios 4095 "sna" 4094 "Error";
VAL_ 2566840922 Number_of_Forward_Gear_Ratios 4095 "sna" 4094 "Error";
VAL_ 2566840922 Transmission_Gear_Ratio 4095 "sna" 4094 "Error";
VAL_ 2565867098 DiffLockStateRearAxle1_EAC1 3 "SNA" 2 "Error" 1 "Differential lock engaged" 0 "Differential lock disengaged";
VAL_ 2565865988 Driveline_Engaged_Axle2 3 "Not available" 2 "Error" 1 "Driveline engaged" 0 "Driveline disengaged";
VAL_ 2565865988 Shift_In_Progress_Axle2 3 "Not available" 2 "Error" 1 "Shift in process" 0 "Shift is not in process";
VAL_ 2565865988 ETC_EMotor_Speed_Axle2 65535 "sna" 65534 "error";
VAL_ 2565866756 Transmission_Selected_Gear_Axle2 127 "D2" 126 "D1" 125 "N" 124 "R1" 123 "R2" 122 "R3" 121 "R4" 120 "R5" 130 "D5" 129 "D4" 128 "D3";
VAL_ 2565866756 Transmission_Current_Gear_Axle2 127 "D2" 126 "D1" 125 "N" 124 "R1" 123 "R2" 122 "R3" 121 "R4" 120 "R5" 130 "D5" 129 "D4" 128 "D3";
VAL_ 2566801924 Transmission_Ready_for_Brake_Release_Axle2 3 "Not available" 2 "Error" 1 "Transmission Ready for Brake Release" 0 "Transmission Not Ready for Brake Release";
VAL_ 2566840836 Number_of_Reverse_Gear_Ratios_Axle2 4095 "sna" 4094 "Error";
VAL_ 2566840836 Number_of_Forward_Gear_Ratios_Axle2 4095 "sna" 4094 "Error";
VAL_ 2566840836 Transmission_Gear_Ratio_Axle2 4095 "sna" 4094 "Error";
VAL_ 2565867012 DiffLockStateRearAxle2_EAC1 3 "SNA" 2 "Error" 1 "Differential lock engaged" 0 "Differential lock disengaged";
VAL_ 2349075290 XBR_EBI_Mode 0 "No Endurance Brake Integration 0xFFowed";
VAL_ 2349075290 XBR_Priority 3 "Low" 2 "Midium" 1 "High" 0 "Highest";
VAL_ 2349075290 XBR_Control_Mode 3 "Not defined" 2 "Acceleration control with maximum mode" 1 "Acc. control with addition mode" 0 "Override disabled";
VAL_ 2349075204 XBR_EBI_Mode_Axle2 0 "No Endurance Brake Integration 0xFFowed";
VAL_ 2349075204 XBR_Priority_Axle2 3 "Low" 2 "Midium" 1 "High" 0 "Highest";
VAL_ 2349075204 XBR_Control_Mode_Axle2 3 "Not defined" 2 "Acceleration control with maximum mode" 1 "Acc. control with addition mode" 0 "Override disabled";
VAL_ 2355941466 Allowed_Towing_Mode 7 "SNA" 6 "Error" 3 "Mode3 mech not neutral (Mode3_notMNeutral)" 2 "Mode2 eOP not operational (Mode2_eOP_nok)" 1 "Mode1 eOP operational (Mode1_eOP_ok)" 0 "Mode0 not relevant (Mode0_na)";
VAL_ 2355941466 Towing_Error 15 "SNA" 14 "Error" 4 "TowingTimeTooLong (TimeTooLong)" 2 "TowingDistanceTooLong (OdoTooLong)" 1 "Towing speed is too high (SpdTooHigh)" 0 "No error";
VAL_ 2355941380 Allowed_Towing_Mode_Axle2 7 "SNA" 6 "Error" 3 "Mode3 mech not neutral (Mode3_notMNeutral)" 2 "Mode2 eOP not operational (Mode2_eOP_nok)" 1 "Mode1 eOP operational (Mode1_eOP_ok)" 0 "Mode0 not relevant (Mode0_na)";
VAL_ 2355941380 Towing_Error_Axle2 15 "SNA" 14 "Error" 4 "TowingTimeTooLong (TimeTooLong)" 2 "TowingDistanceTooLong (OdoTooLong)" 1 "Towing speed is too high (SpdTooHigh)" 0 "No error";
